VERSION "created by canmatrix"

NS_ :

BS_:

BU_: CabHeater_44 EAC_94 DCDC_1A HVJB_1E PPC_HV_5B PPC_00 PPC_EngineBrake_29 VECU_27 SAC_30 DTCO_EE eDS_5A EBS3_0B AEBS_A0 BMS_F4 Gearbox_03 DD_17 SERVICE_TOOL_F9 DANA_5F
VAL_TABLE_ ChargingSessionState 4 "ChargeSessionOngoing" 3 "Shutdown_CCU" 2 "Shutdown_EVSE" 1 "Shutdown_EV" 0 "No plug inserted" ;
VAL_TABLE_ ActiveDischarge 3 "NotAvailable" 2 "Error" 1 "Active" 0 "Not Active" ;
VAL_TABLE_ StopChargingSwitchIndication 3 "Not Available" 2 "Error" 1 "On" 0 "Off" ;

BO_ 3221225472 VECTOR__INDEPENDENT_SIG_MSG: 0 Vector__XXX
 SG_ HVESChargeConsent : 0|2@1+ (1,0) [0|3] "" Vector__XXX
 SG_ PropulsionModeReqDist : 0|16@1+ (0.03125,0) [0|2007.96875] "km" Vector__XXX
 SG_ PropulsionModeReqMaxSpd : 0|8@1+ (1,0) [0|250] "km/h" Vector__XXX
 SG_ StoredESSetPointReq : 0|8@1+ (0.4,0) [0|100] "%" Vector__XXX
 SG_ StoredESCharge_DischargeRateReq : 0|8@1+ (0.4,0) [0|100] "%" Vector__XXX
 SG_ ExtlESConnectionDemand : 0|4@1+ (1,0) [0|15] "" Vector__XXX
 SG_ PropulsionModeReq : 0|4@1+ (1,0) [0|15] "" Vector__XXX
 SG_ OpVehModeReq : 0|4@1+ (1,0) [0|15] "" Vector__XXX
 SG_ ShutdownCmd : 0|2@1+ (1,0) [0|3] "" Vector__XXX
 SG_ PropulsionDisableReq : 0|2@1+ (1,0) [0|3] "" Vector__XXX
 SG_ HybrdSystmRgnrtvBrakingDisableRq : 0|2@1+ (1,0) [0|3] "" Vector__XXX
 SG_ HybridSystemProtectionOverrideRq : 0|2@1+ (1,0) [0|3] "" Vector__XXX
 SG_ HVESSThermalMnmgtMaintenanceSw : 0|2@1+ (1,0) [0|3] "" Vector__XXX
 SG_ PropulsionMotorCoolantFillSw : 0|2@1+ (1,0) [0|3] "" Vector__XXX
 SG_ PwrECoolantFillSw : 0|2@1+ (1,0) [0|3] "" Vector__XXX
 SG_ ShutdownSw : 0|2@1+ (1,0) [0|3] "" Vector__XXX
 SG_ PropulsionDisableSw : 0|2@1+ (1,0) [0|3] "" Vector__XXX
 SG_ HybrdSystmCstngRgnrtvBrkngLvlSlc : 0|8@1+ (0.4,0) [0|100] "%" Vector__XXX
 SG_ HybrdSystmBrkPdlRgnrtvBrkngDsblS : 0|2@1+ (1,0) [0|3] "" Vector__XXX
 SG_ HybrdSystmRgnrtvBrkngDsbleSwitch : 0|2@1+ (1,0) [0|3] "" Vector__XXX
 SG_ HybrdSystmPwrElctrncsClntLvlSwtc : 0|2@1+ (1,0) [0|3] "" Vector__XXX
 SG_ HybrdSystmPrplsnClantLevelSwitch : 0|2@1+ (1,0) [0|3] "" Vector__XXX
 SG_ HybrdSystmPrtctionOverrideSwitch : 0|2@1+ (1,0) [0|3] "" Vector__XXX

BO_ 2566901851 UABX_Control: 8 PPC_HV_5B
 SG_ PLCHR_setTimeout : 0|16@1+ (1,0) [0|0] "s" Vector__XXX

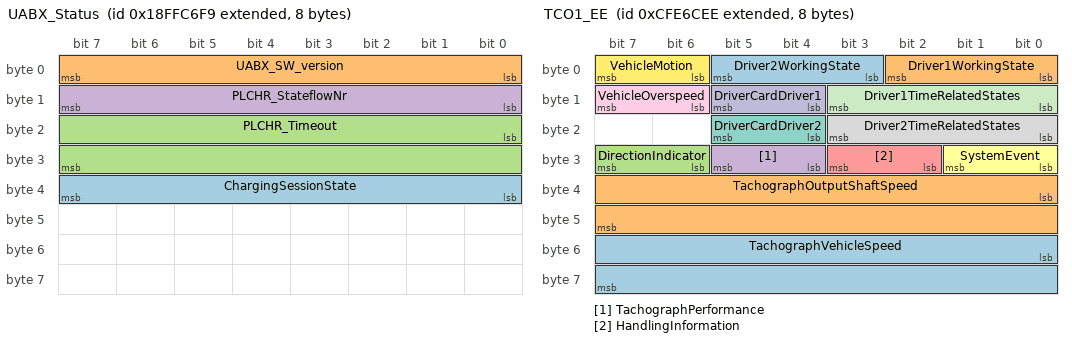
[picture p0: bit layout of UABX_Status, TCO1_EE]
BO_ 2566899449 UABX_Status: 8 SERVICE_TOOL_F9
 SG_ ChargingSessionState : 32|8@1+ (1,0) [0|0] "" Vector__XXX
 SG_ UABX_SW_version : 0|8@1+ (1,0) [0|0] "" Vector__XXX
 SG_ PLCHR_Timeout : 16|16@1+ (1,0) [0|0] "" Vector__XXX
 SG_ PLCHR_StateflowNr : 8|8@1+ (1,0) [0|0] "" Vector__XXX

BO_ 2633727071 WAKE_CCU_5F: 8 DANA_5F
 SG_ ControlBitVector : 0|8@1+ (1,0) [0|255] "state" Vector__XXX

BO_ 2565534720 RQST_HVESSCFG: 3 PPC_00

BO_ 2566866580 EAC_03_94: 8 EAC_94
 SG_ comp_overload : 34|1@1- (1,0) [0|1] "" Vector__XXX
 SG_ comp_temp_sens_shorted : 33|1@1- (1,0) [0|1] "" Vector__XXX
 SG_ comp_temp_sens_open : 32|1@1- (1,0) [0|1] "" Vector__XXX
 SG_ Oil_lev_switch_shorted_gnd : 31|1@1- (1,0) [0|1] "" Vector__XXX
 SG_ Oil_lev_switch_shorted_power : 30|1@1- (1,0) [0|1] "" Vector__XXX
 SG_ HVIL_Out_Open_Circuit_Fault : 29|1@1- (1,0) [0|1] "" Vector__XXX
 SG_ HVIL_In_Open_Circuit_Fault : 28|1@1- (1,0) [0|1] "" Vector__XXX
 SG_ HVIL_Open_Circuit_Fault : 27|1@1- (1,0) [0|1] "" Vector__XXX
 SG_ HVIL_Over_Current_Fault : 26|1@1- (1,0) [0|1] "" Vector__XXX
 SG_ Mult_Int_Temp_Sensor_Fault : 25|1@1- (1,0) [0|1] "" Vector__XXX
 SG_ Torque_High_Reduced_Speed : 24|1@1- (1,0) [0|1] "" Vector__XXX
 SG_ Reserved5 : 23|1@1- (1,0) [0|1] "" Vector__XXX
 SG_ Reserved4 : 22|1@1- (1,0) [0|1] "" Vector__XXX
 SG_ Internal_Temp_Sensor_Fault : 21|1@1- (1,0) [0|1] "" Vector__XXX
 SG_ Oil_Level_Switch_Circuit_Short : 20|1@1- (1,0) [0|1] "" Vector__XXX
 SG_ Oil_Level_Switch_Circuit_Open : 19|1@1- (1,0) [0|1] "" Vector__XXX
 SG_ CAN_Bus_Fault : 18|1@1- (1,0) [0|1] "" Vector__XXX
 SG_ EEPROM_Checksum_Fault : 17|1@1- (1,0) [0|1] "" Vector__XXX
 SG_ ESCM_Enable_Component_SPN_Error : 16|1@1- (1,0) [0|1] "" Vector__XXX
 SG_ ESCM_Max_Current_SPN_Error : 15|1@1- (1,0) [0|1] "" Vector__XXX
 SG_ ESCM_Speed_Request_SPN_Error : 14|1@1- (1,0) [0|1] "" Vector__XXX
 SG_ Power_Control_PGN_Fault : 13|1@1- (1,0) [0|1] "" Vector__XXX
 SG_ Speed_Req_PGN_Fault : 12|1@1- (1,0) [0|1] "" Vector__XXX
 SG_ Oil_Level_Low : 11|1@1- (1,0) [0|1] "" Vector__XXX
 SG_ Reserved2 : 10|1@1- (1,0) [0|1] "" Vector__XXX
 SG_ Reserved1 : 9|1@1- (1,0) [0|1] "" Vector__XXX
 SG_ Emotor_Over_Temperature : 8|1@1- (1,0) [0|1] "" Vector__XXX
 SG_ Compressor_Over_Temperature : 7|1@1- (1,0) [0|1] "" Vector__XXX
 SG_ No_Connection_With_PU : 6|1@1- (1,0) [0|1] "" Vector__XXX
 SG_ Power_Stage_Error : 5|1@1- (1,0) [0|1] "" Vector__XXX
 SG_ Overload : 4|1@1- (1,0) [0|1] "" Vector__XXX
 SG_ Traction_Volt_High : 3|1@1- (1,0) [0|1] "" Vector__XXX
 SG_ Traction_Supply_Current_Low : 2|1@1- (1,0) [0|1] "" Vector__XXX
 SG_ Traction_Volt_Low : 1|1@1- (1,0) [0|1] "" Vector__XXX
 SG_ Traction_Volt_Critical_Low : 0|1@1- (1,0) [0|1] "" Vector__XXX

BO_ 2633785076 HVESSHIST_F4: 19 BMS_F4
 SG_ HVESSTotalEnergyOut : 120|32@1+ (1,0) [0|4211081215] "kWh" Vector__XXX
 SG_ HVESSTotalEnergyInput : 88|32@1+ (1,0) [0|4211081215] "kWh" Vector__XXX
 SG_ HVESSTotalAccumulatedCharge : 56|32@1+ (100,0) [0|421108121500] "Ah" Vector__XXX
 SG_ HVESSTotalEnergyThroughput : 24|32@1+ (100,0) [0|421108121500] "Wh" Vector__XXX
 SG_ HVESSContactorOpenUnderLoadCount : 8|16@1+ (1,0) [0|64255] "" Vector__XXX
 SG_ HVESSStateOfHealth : 0|8@1+ (0.4,0) [0|100] "%" Vector__XXX

BO_ 2365484270 TCO1_EE: 8 DTCO_EE
 SG_ TachographVehicleSpeed : 48|16@1+ (0.00390625,0) [0|250.99609375] "km/h" Vector__XXX
 SG_ TachographOutputShaftSpeed : 32|16@1+ (0.125,0) [0|8031.875] "rpm" Vector__XXX
 SG_ DirectionIndicator : 30|2@1+ (1,0) [0|3] "" Vector__XXX
 SG_ TachographPerformance : 28|2@1+ (1,0) [0|3] "" Vector__XXX
 SG_ HandlingInformation : 26|2@1+ (1,0) [0|3] "" Vector__XXX
 SG_ SystemEvent : 24|2@1+ (1,0) [0|3] "" Vector__XXX
 SG_ DriverCardDriver2 : 20|2@1+ (1,0) [0|3] "" Vector__XXX
 SG_ Driver2TimeRelatedStates : 16|4@1+ (1,0) [0|15] "" Vector__XXX
 SG_ VehicleOverspeed : 14|2@1+ (1,0) [0|3] "" Vector__XXX
 SG_ DriverCardDriver1 : 12|2@1+ (1,0) [0|3] "" Vector__XXX
 SG_ Driver1TimeRelatedStates : 8|4@1+ (1,0) [0|15] "" Vector__XXX
 SG_ VehicleMotion : 6|2@1+ (1,0) [0|3] "" Vector__XXX
 SG_ Driver2WorkingState : 3|3@1+ (1,0) [0|7] "" Vector__XXX
 SG_ Driver1WorkingState : 0|3@1+ (1,0) [0|7] "" Vector__XXX

BO_ 2565537626 RQST_TCFG_5A: 3 eDS_5A
 SG_ ParameterGroupNumberRQST : 0|24@1+ (1,0) [0|16777215] "PGN" Vector__XXX

BO_ 2566846554 TRF1_5A: 8 eDS_5A
 SG_ TransmissionOilTemperature1 : 32|16@1+ (0.03125,-273) [-273|1774.96875] "degC" Vector__XXX

BO_ 2566615642 MG1IT_5A: 8 eDS_5A
 SG_ MotorGenerator1InverterTemp1 : 0|8@1+ (1,-40) [-40|215] "degC" Vector__XXX
 SG_ MotorGenerator1InverterTemp2 : 8|8@1+ (1,-40) [-40|215] "degC" Vector__XXX

BO_ 2566615386 MG1IMT_5A: 8 eDS_5A
 SG_ MotorGenerator1Temperature1 : 0|8@1+ (1,-40) [-40|215] "degC" Vector__XXX
 SG_ MotorGenerator1Temperature2 : 8|8@1+ (1,-40) [-40|215] "degC" Vector__XXX

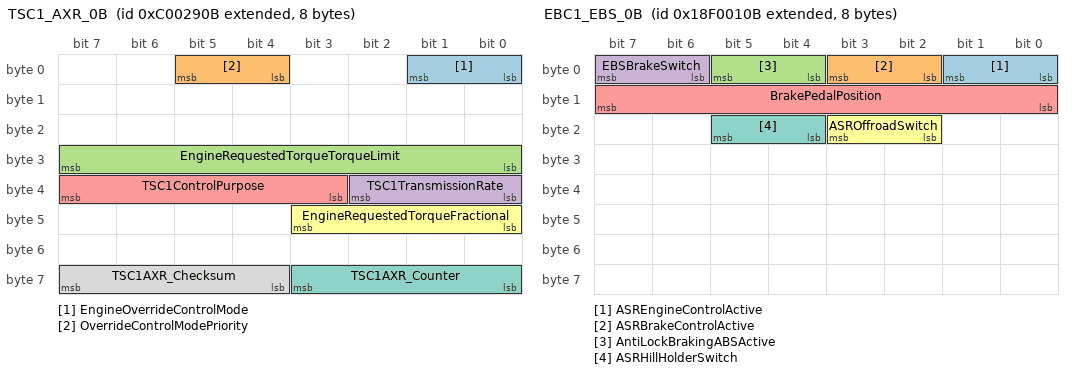
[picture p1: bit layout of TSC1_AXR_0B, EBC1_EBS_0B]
BO_ 2348820747 TSC1_AXR_0B: 8 EBS3_0B
 SG_ EngineOverrideControlMode : 0|2@1+ (1,0) [0|3] "state" Vector__XXX
 SG_ OverrideControlModePriority : 4|2@1+ (1,0) [0|3] "state" Vector__XXX
 SG_ EngineRequestedTorqueTorqueLimit : 24|8@1+ (1,-125) [-125|130] "%" Vector__XXX
 SG_ TSC1TransmissionRate : 32|3@1+ (1,0) [0|7] "state" Vector__XXX
 SG_ TSC1ControlPurpose : 35|5@1+ (1,0) [0|31] "state" Vector__XXX
 SG_ EngineRequestedTorqueFractional : 40|4@1+ (0.125,0) [0|1.875] "%" Vector__XXX
 SG_ TSC1AXR_Counter : 56|4@1+ (1,0) [0|15] "count" Vector__XXX
 SG_ TSC1AXR_Checksum : 60|4@1+ (1,0) [0|15] "count" Vector__XXX

BO_ 2565865739 EBC1_EBS_0B: 8 EBS3_0B
 SG_ ASREngineControlActive : 0|2@1+ (1,0) [0|3] "state" Vector__XXX
 SG_ ASRBrakeControlActive : 2|2@1+ (1,0) [0|3] "state" Vector__XXX
 SG_ AntiLockBrakingABSActive : 4|2@1+ (1,0) [0|3] "state" Vector__XXX
 SG_ EBSBrakeSwitch : 6|2@1+ (1,0) [0|3] "state" Vector__XXX
 SG_ BrakePedalPosition : 8|8@1+ (0.4,0) [0|102] "%" Vector__XXX
 SG_ ASROffroadSwitch : 18|2@1+ (1,0) [0|3] "state" Vector__XXX
 SG_ ASRHillHolderSwitch : 20|2@1+ (1,0) [0|3] "state" Vector__XXX

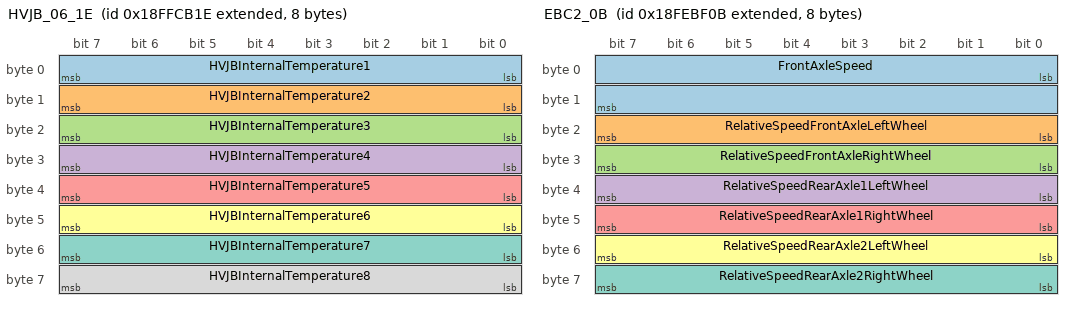
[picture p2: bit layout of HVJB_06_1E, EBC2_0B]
BO_ 2566900510 HVJB_06_1E: 8 HVJB_1E
 SG_ HVJBInternalTemperature1 : 0|8@1+ (1,-40) [-40|215] "degC" Vector__XXX
 SG_ HVJBInternalTemperature2 : 8|8@1+ (1,-40) [-40|215] "degC" Vector__XXX
 SG_ HVJBInternalTemperature3 : 16|8@1+ (1,-40) [-40|215] "degC" Vector__XXX
 SG_ HVJBInternalTemperature4 : 24|8@1+ (1,-40) [-40|215] "degC" Vector__XXX
 SG_ HVJBInternalTemperature5 : 32|8@1+ (1,-40) [-40|215] "degC" Vector__XXX
 SG_ HVJBInternalTemperature6 : 40|8@1+ (1,-40) [-40|215] "degC" Vector__XXX
 SG_ HVJBInternalTemperature7 : 48|8@1+ (1,-40) [-40|215] "degC" Vector__XXX
 SG_ HVJBInternalTemperature8 : 56|8@1+ (1,-40) [-40|215] "degC" Vector__XXX

BO_ 2566831883 EBC2_0B: 8 EBS3_0B
 SG_ FrontAxleSpeed : 0|16@1+ (0.00390625,0) [0|255.99609375] "km/h" Vector__XXX
 SG_ RelativeSpeedFrontAxleLeftWheel : 16|8@1+ (0.0625,-7.8125) [-7.8125|8.125] "km/h" Vector__XXX
 SG_ RelativeSpeedFrontAxleRightWheel : 24|8@1+ (0.0625,-7.8125) [-7.8125|8.125] "km/h" Vector__XXX
 SG_ RelativeSpeedRearAxle1LeftWheel : 32|8@1+ (0.0625,-7.8125) [-7.8125|8.125] "km/h" Vector__XXX
 SG_ RelativeSpeedRearAxle1RightWheel : 40|8@1+ (0.0625,-7.8125) [-7.8125|8.125] "km/h" Vector__XXX
 SG_ RelativeSpeedRearAxle2LeftWheel : 48|8@1+ (0.0625,-7.8125) [-7.8125|8.125] "km/h" Vector__XXX
 SG_ RelativeSpeedRearAxle2RightWheel : 56|8@1+ (0.0625,-7.8125) [-7.8125|8.125] "km/h" Vector__XXX

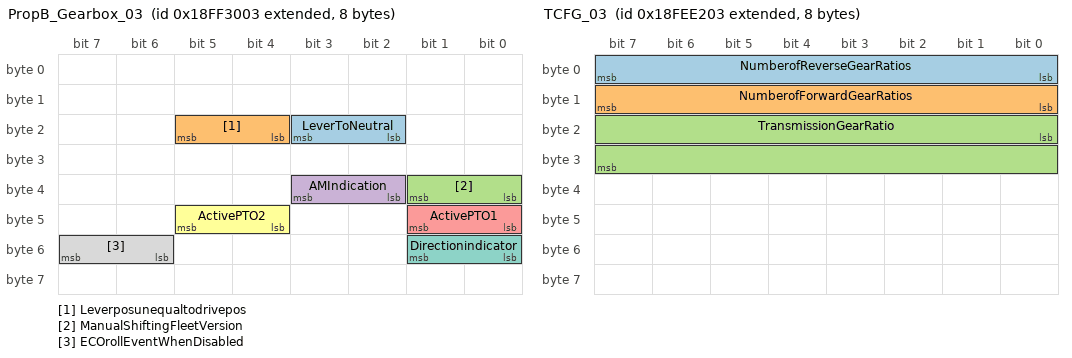
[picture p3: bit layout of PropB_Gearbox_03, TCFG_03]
BO_ 2566860803 PropB_Gearbox_03: 8 Gearbox_03
 SG_ LeverToNeutral : 18|2@1+ (1,0) [0|3] "state" Vector__XXX
 SG_ Leverposunequaltodrivepos : 20|2@1+ (1,0) [0|3] "state" Vector__XXX
 SG_ ManualShiftingFleetVersion : 32|2@1+ (1,0) [0|3] "state" Vector__XXX
 SG_ AMIndication : 34|2@1+ (1,0) [0|3] "state" Vector__XXX
 SG_ ActivePTO1 : 40|2@1+ (1,0) [0|3] "state" Vector__XXX
 SG_ ActivePTO2 : 44|2@1+ (1,0) [0|3] "state" Vector__XXX
 SG_ Directionindicator : 48|2@1+ (1,0) [0|3] "state" Vector__XXX
 SG_ ECOrollEventWhenDisabled : 54|2@1+ (1,0) [0|3] "state" Vector__XXX

BO_ 2566840835 TCFG_03: 8 Gearbox_03
 SG_ NumberofReverseGearRatios : 0|8@1+ (1,0) [0|255] "state" Vector__XXX
 SG_ NumberofForwardGearRatios : 8|8@1+ (1,0) [0|255] "state" Vector__XXX
 SG_ TransmissionGearRatio : 16|16@1+ (0.001,0) [0|65.535] "ratio" Vector__XXX

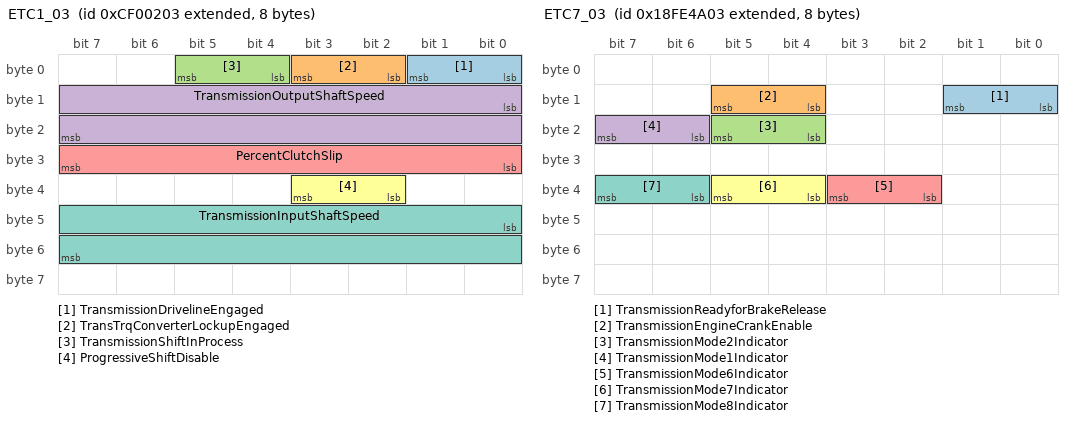
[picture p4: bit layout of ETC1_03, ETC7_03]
BO_ 2364539395 ETC1_03: 8 Gearbox_03
 SG_ TransmissionDrivelineEngaged : 0|2@1+ (1,0) [0|3] "state" Vector__XXX
 SG_ TransTrqConverterLockupEngaged : 2|2@1+ (1,0) [0|3] "state" Vector__XXX
 SG_ TransmissionShiftInProcess : 4|2@1+ (1,0) [0|3] "state" Vector__XXX
 SG_ TransmissionOutputShaftSpeed : 8|16@1+ (0.125,0) [0|8191.875] "rpm" Vector__XXX
 SG_ PercentClutchSlip : 24|8@1+ (0.4,0) [0|102] "%" Vector__XXX
 SG_ ProgressiveShiftDisable : 34|2@1+ (1,0) [0|3] "state" Vector__XXX
 SG_ TransmissionInputShaftSpeed : 40|16@1+ (0.125,0) [0|8191.875] "rpm" Vector__XXX

BO_ 2566801923 ETC7_03: 8 Gearbox_03
 SG_ TransmissionReadyforBrakeRelease : 8|2@1+ (1,0) [0|3] "state" Vector__XXX
 SG_ TransmissionEngineCrankEnable : 12|2@1+ (1,0) [0|3] "state" Vector__XXX
 SG_ TransmissionMode2Indicator : 20|2@1+ (1,0) [0|3] "state" Vector__XXX
 SG_ TransmissionMode1Indicator : 22|2@1+ (1,0) [0|3] "state" Vector__XXX
 SG_ TransmissionMode6Indicator : 34|2@1+ (1,0) [0|3] "state" Vector__XXX
 SG_ TransmissionMode7Indicator : 36|2@1+ (1,0) [0|3] "state" Vector__XXX
 SG_ TransmissionMode8Indicator : 38|2@1+ (1,0) [0|3] "state" Vector__XXX

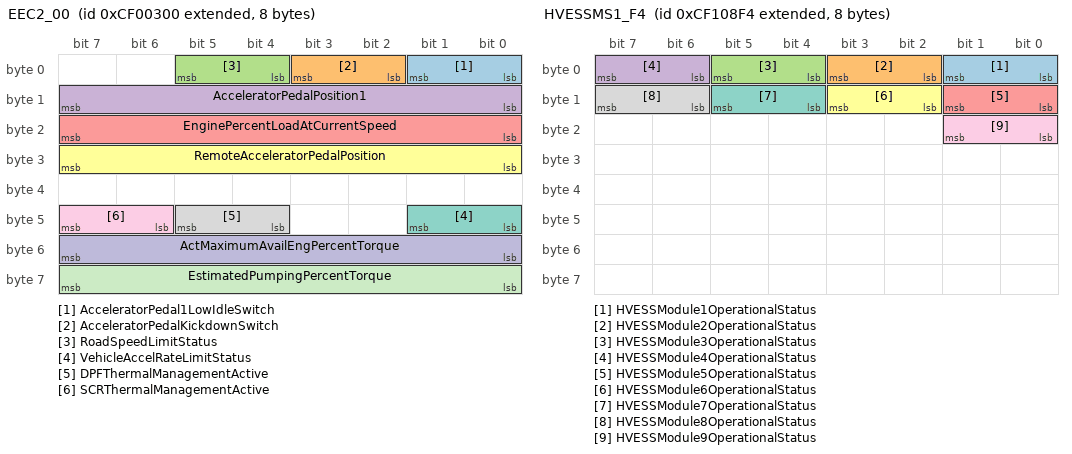
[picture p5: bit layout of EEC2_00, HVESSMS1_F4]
BO_ 2364539648 EEC2_00: 8 PPC_00
 SG_ AcceleratorPedal1LowIdleSwitch : 0|2@1+ (1,0) [0|3] "state" Vector__XXX
 SG_ AcceleratorPedalKickdownSwitch : 2|2@1+ (1,0) [0|3] "state" Vector__XXX
 SG_ RoadSpeedLimitStatus : 4|2@1+ (1,0) [0|3] "state" Vector__XXX
 SG_ AcceleratorPedalPosition1 : 8|8@1+ (0.4,0) [0|102] "%" Vector__XXX
 SG_ EnginePercentLoadAtCurrentSpeed : 16|8@1+ (1,0) [0|255] "%" Vector__XXX
 SG_ RemoteAcceleratorPedalPosition : 24|8@1+ (0.4,0) [0|102] "%" Vector__XXX
 SG_ VehicleAccelRateLimitStatus : 40|2@1+ (1,0) [0|3] "state" Vector__XXX
 SG_ DPFThermalManagementActive : 44|2@1+ (1,0) [0|3] "state" Vector__XXX
 SG_ SCRThermalManagementActive : 46|2@1+ (1,0) [0|3] "state" Vector__XXX
 SG_ ActMaximumAvailEngPercentTorque : 48|8@1+ (0.4,0) [0|102] "%" Vector__XXX
 SG_ EstimatedPumpingPercentTorque : 56|8@1+ (1,-125) [-125|130] "%" Vector__XXX

BO_ 2364606708 HVESSMS1_F4: 8 BMS_F4
 SG_ HVESSModule1OperationalStatus : 0|2@1+ (1,0) [0|3] "bit-mapped" Vector__XXX
 SG_ HVESSModule2OperationalStatus : 2|2@1+ (1,0) [0|3] "bit-mapped" Vector__XXX
 SG_ HVESSModule3OperationalStatus : 4|2@1+ (1,0) [0|3] "bit-mapped" Vector__XXX
 SG_ HVESSModule4OperationalStatus : 6|2@1+ (1,0) [0|3] "bit-mapped" Vector__XXX
 SG_ HVESSModule5OperationalStatus : 8|2@1+ (1,0) [0|3] "bit-mapped" Vector__XXX
 SG_ HVESSModule6OperationalStatus : 10|2@1+ (1,0) [0|3] "bit-mapped" Vector__XXX
 SG_ HVESSModule7OperationalStatus : 12|2@1+ (1,0) [0|3] "bit-mapped" Vector__XXX
 SG_ HVESSModule8OperationalStatus : 14|2@1+ (1,0) [0|3] "bit-mapped" Vector__XXX
 SG_ HVESSModule9OperationalStatus : 16|2@1+ (1,0) [0|3] "bit-mapped" Vector__XXX

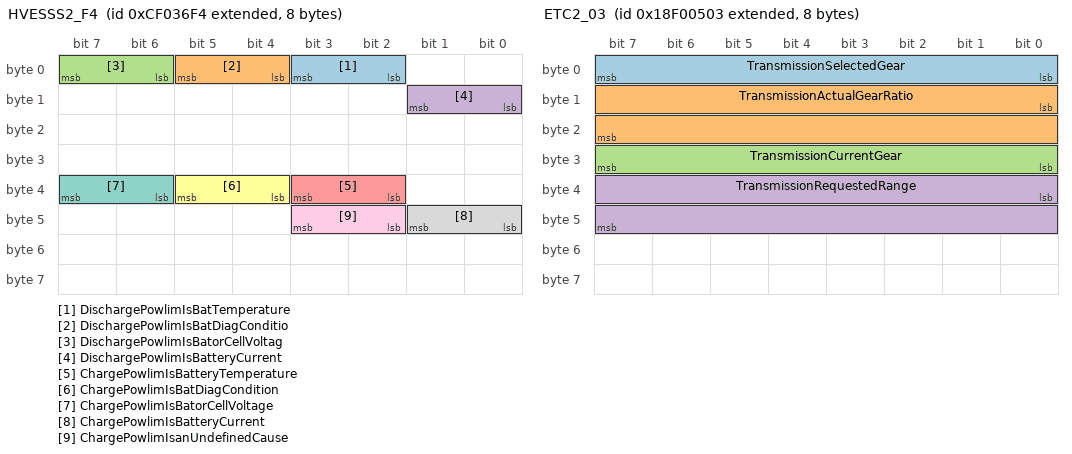
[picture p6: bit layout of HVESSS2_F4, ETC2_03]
BO_ 2364552948 HVESSS2_F4: 8 BMS_F4
 SG_ DischargePowlimIsBatTemperature : 2|2@1+ (1,0) [0|3] "bit-mapped" Vector__XXX
 SG_ DischargePowlimIsBatDiagConditio : 4|2@1+ (1,0) [0|3] "bit-mapped" Vector__XXX
 SG_ DischargePowlimIsBatorCellVoltag : 6|2@1+ (1,0) [0|3] "bit-mapped" Vector__XXX
 SG_ DischargePowlimIsBatteryCurrent : 8|2@1+ (1,0) [0|3] "bit-mapped" Vector__XXX
 SG_ ChargePowlimIsBatteryTemperature : 34|2@1+ (1,0) [0|3] "bit-mapped" Vector__XXX
 SG_ ChargePowlimIsBatDiagCondition : 36|2@1+ (1,0) [0|3] "bit-mapped" Vector__XXX
 SG_ ChargePowlimIsBatorCellVoltage : 38|2@1+ (1,0) [0|3] "bit-mapped" Vector__XXX
 SG_ ChargePowlimIsBatteryCurrent : 40|2@1+ (1,0) [0|3] "bit-mapped" Vector__XXX
 SG_ ChargePowlimIsanUndefinedCause : 42|2@1+ (1,0) [0|3] "bit-mapped" Vector__XXX

BO_ 2565866755 ETC2_03: 8 Gearbox_03
 SG_ TransmissionSelectedGear : 0|8@1+ (1,-125) [-125|130] "state" Vector__XXX
 SG_ TransmissionActualGearRatio : 8|16@1+ (0.001,0) [0|65.535] "ratio" Vector__XXX
 SG_ TransmissionCurrentGear : 24|8@1+ (1,-125) [-125|130] "state" Vector__XXX
 SG_ TransmissionRequestedRange : 32|16@1+ (1,0) [0|65535] "ASCII" Vector__XXX

BO_ 2583630324 HVESS_01_F4: 8 BMS_F4
 SG_ ChargingTimeTillFullSOCEst : 0|16@1+ (1,0) [0|65535] "min" Vector__XXX
 SG_ ChargingTimeTillFullSOCRec : 16|16@1+ (1,0) [0|65535] "min" Vector__XXX

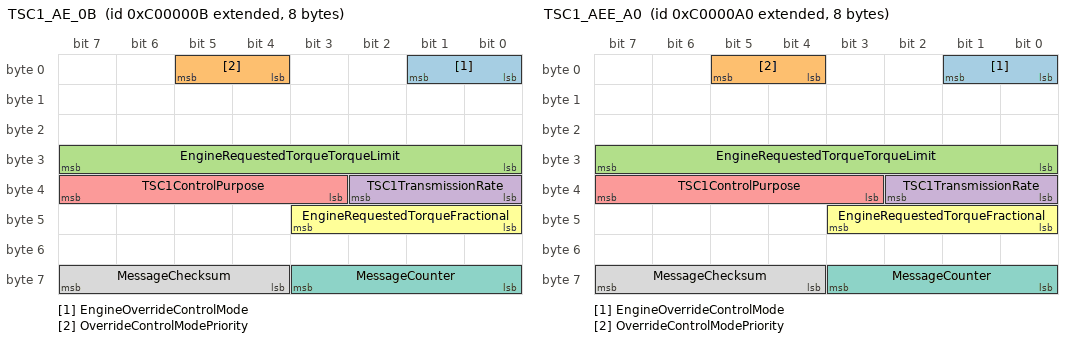
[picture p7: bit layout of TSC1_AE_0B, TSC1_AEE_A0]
BO_ 2348810251 TSC1_AE_0B: 8 EBS3_0B
 SG_ EngineOverrideControlMode : 0|2@1+ (1,0) [0|3] "state" Vector__XXX
 SG_ OverrideControlModePriority : 4|2@1+ (1,0) [0|3] "state" Vector__XXX
 SG_ EngineRequestedTorqueTorqueLimit : 24|8@1+ (1,-125) [-125|130] "%" Vector__XXX
 SG_ TSC1TransmissionRate : 32|3@1+ (1,0) [0|7] "state" Vector__XXX
 SG_ TSC1ControlPurpose : 35|5@1+ (1,0) [0|31] "state" Vector__XXX
 SG_ EngineRequestedTorqueFractional : 40|4@1+ (0.125,0) [0|1.875] "%" Vector__XXX
 SG_ MessageCounter : 56|4@1+ (1,0) [0|15] "count" Vector__XXX
 SG_ MessageChecksum : 60|4@1+ (1,0) [0|15] "count" Vector__XXX

BO_ 2348810400 TSC1_AEE_A0: 8 AEBS_A0
 SG_ EngineOverrideControlMode : 0|2@1+ (1,0) [0|3] "state" Vector__XXX
 SG_ OverrideControlModePriority : 4|2@1+ (1,0) [0|3] "state" Vector__XXX
 SG_ EngineRequestedTorqueTorqueLimit : 24|8@1+ (1,-125) [-125|130] "%" Vector__XXX
 SG_ TSC1TransmissionRate : 32|3@1+ (1,0) [0|7] "state" Vector__XXX
 SG_ TSC1ControlPurpose : 35|5@1+ (1,0) [0|31] "state" Vector__XXX
 SG_ EngineRequestedTorqueFractional : 40|4@1+ (0.125,0) [0|1.875] "%" Vector__XXX
 SG_ MessageCounter : 56|4@1+ (1,0) [0|15] "count" Vector__XXX
 SG_ MessageChecksum : 60|4@1+ (1,0) [0|15] "count" Vector__XXX

BO_ 2566698843 HSS2_5B: 8 PPC_HV_5B
 SG_ HybridPropulsionModeRemDist : 32|16@1+ (0.03125,0) [0|2007.96875] "km" Vector__XXX

BO_ 2566701659 HSS1_5B: 8 PPC_HV_5B
 SG_ StoredEnergySourceLevel : 32|8@1+ (0.4,0) [0|100] "%" Vector__XXX

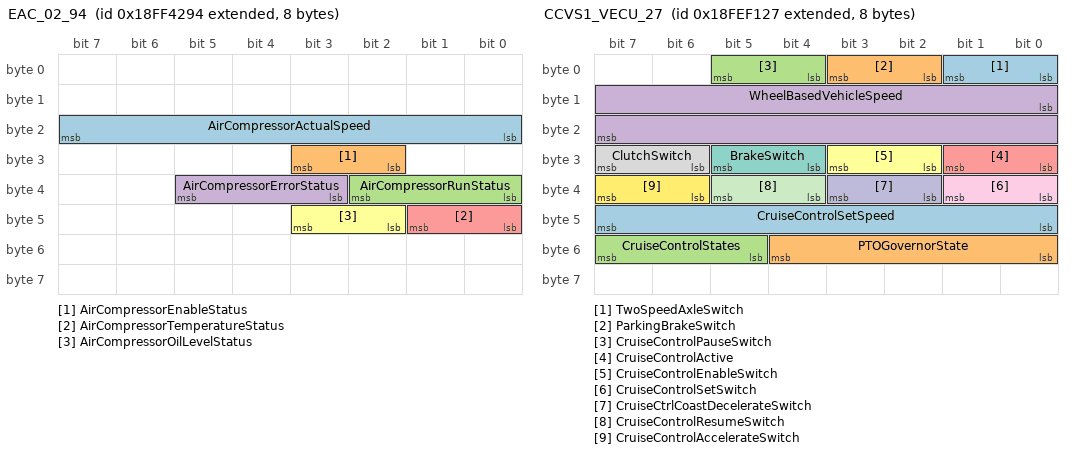
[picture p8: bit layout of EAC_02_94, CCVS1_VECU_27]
BO_ 2566865556 EAC_02_94: 8 EAC_94
 SG_ AirCompressorActualSpeed : 16|8@1+ (20,0) [0|5000] "rpm" Vector__XXX
 SG_ AirCompressorEnableStatus : 26|2@1+ (1,0) [0|3] "state" Vector__XXX
 SG_ AirCompressorRunStatus : 32|3@1+ (1,0) [0|7] "state" Vector__XXX
 SG_ AirCompressorErrorStatus : 35|3@1+ (1,0) [0|7] "state" Vector__XXX
 SG_ AirCompressorTemperatureStatus : 40|2@1+ (1,0) [0|3] "state" Vector__XXX
 SG_ AirCompressorOilLevelStatus : 42|2@1+ (1,0) [0|3] "state" Vector__XXX

BO_ 2566844711 CCVS1_VECU_27: 8 VECU_27
 SG_ TwoSpeedAxleSwitch : 0|2@1+ (1,0) [0|3] "state" Vector__XXX
 SG_ ParkingBrakeSwitch : 2|2@1+ (1,0) [0|3] "state" Vector__XXX
 SG_ CruiseControlPauseSwitch : 4|2@1+ (1,0) [0|3] "state" Vector__XXX
 SG_ WheelBasedVehicleSpeed : 8|16@1+ (0.00390625,0) [0|255.99609375] "km/h" Vector__XXX
 SG_ CruiseControlActive : 24|2@1+ (1,0) [0|3] "state" Vector__XXX
 SG_ CruiseControlEnableSwitch : 26|2@1+ (1,0) [0|3] "state" Vector__XXX
 SG_ BrakeSwitch : 28|2@1+ (1,0) [0|3] "state" Vector__XXX
 SG_ ClutchSwitch : 30|2@1+ (1,0) [0|3] "state" Vector__XXX
 SG_ CruiseControlSetSwitch : 32|2@1+ (1,0) [0|3] "state" Vector__XXX
 SG_ CruiseCtrlCoastDecelerateSwitch : 34|2@1+ (1,0) [0|3] "state" Vector__XXX
 SG_ CruiseControlResumeSwitch : 36|2@1+ (1,0) [0|3] "state" Vector__XXX
 SG_ CruiseControlAccelerateSwitch : 38|2@1+ (1,0) [0|3] "state" Vector__XXX
 SG_ CruiseControlSetSpeed : 40|8@1+ (1,0) [0|255] "km/h" Vector__XXX
 SG_ PTOGovernorState : 48|5@1+ (1,0) [0|31] "state" Vector__XXX
 SG_ CruiseControlStates : 53|3@1+ (1,0) [0|7] "state" Vector__XXX

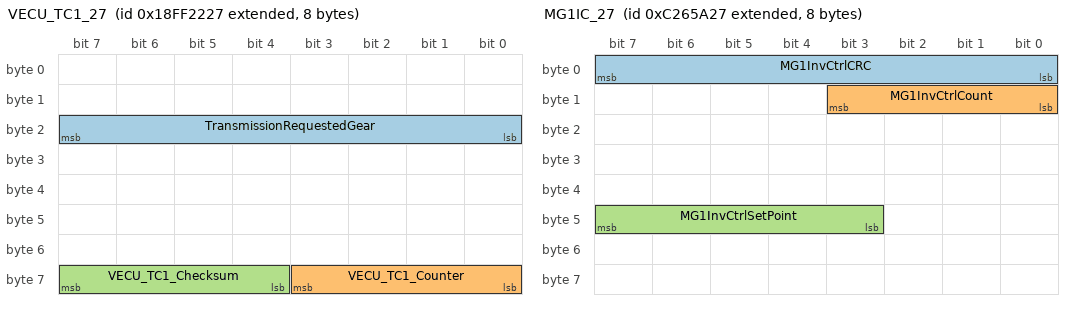
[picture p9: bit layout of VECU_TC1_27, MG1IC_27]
BO_ 2566857255 VECU_TC1_27: 8 VECU_27
 SG_ TransmissionRequestedGear : 16|8@1+ (1,-125) [-125|130] "gear value" Vector__XXX
 SG_ VECU_TC1_Counter : 56|4@1+ (1,0) [0|15] "count" Vector__XXX
 SG_ VECU_TC1_Checksum : 60|4@1+ (1,0) [0|15] "count" Vector__XXX

BO_ 2351323687 MG1IC_27: 8 VECU_27
 SG_ MG1InvCtrlCRC : 0|8@1+ (1,0) [0|255] "count" Vector__XXX
 SG_ MG1InvCtrlCount : 8|4@1+ (1,0) [0|15] "count" Vector__XXX
 SG_ MG1InvCtrlSetPoint : 43|5@1+ (1,0) [0|31] "state" Vector__XXX

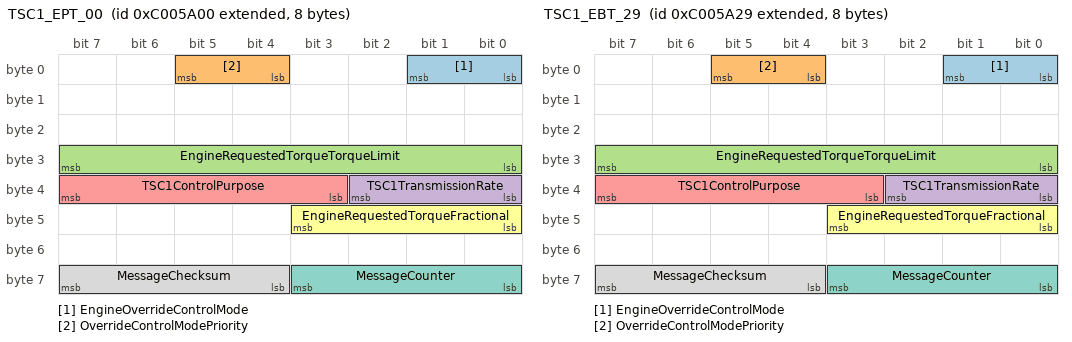
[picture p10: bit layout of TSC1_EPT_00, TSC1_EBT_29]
BO_ 2348833280 TSC1_EPT_00: 8 PPC_00
 SG_ EngineOverrideControlMode : 0|2@1+ (1,0) [0|3] "state" Vector__XXX
 SG_ OverrideControlModePriority : 4|2@1+ (1,0) [0|3] "state" Vector__XXX
 SG_ EngineRequestedTorqueTorqueLimit : 24|8@1+ (1,-125) [-125|130] "%" Vector__XXX
 SG_ TSC1TransmissionRate : 32|3@1+ (1,0) [0|7] "state" Vector__XXX
 SG_ TSC1ControlPurpose : 35|5@1+ (1,0) [0|31] "state" Vector__XXX
 SG_ EngineRequestedTorqueFractional : 40|4@1+ (0.125,0) [0|1.875] "%" Vector__XXX
 SG_ MessageCounter : 56|4@1+ (1,0) [0|15] "count" Vector__XXX
 SG_ MessageChecksum : 60|4@1+ (1,0) [0|15] "count" Vector__XXX

BO_ 2348833321 TSC1_EBT_29: 8 PPC_EngineBrake_29
 SG_ EngineOverrideControlMode : 0|2@1+ (1,0) [0|3] "state" Vector__XXX
 SG_ OverrideControlModePriority : 4|2@1+ (1,0) [0|3] "state" Vector__XXX
 SG_ EngineRequestedTorqueTorqueLimit : 24|8@1+ (1,-125) [-125|130] "%" Vector__XXX
 SG_ TSC1TransmissionRate : 32|3@1+ (1,0) [0|7] "state" Vector__XXX
 SG_ TSC1ControlPurpose : 35|5@1+ (1,0) [0|31] "state" Vector__XXX
 SG_ EngineRequestedTorqueFractional : 40|4@1+ (0.125,0) [0|1.875] "%" Vector__XXX
 SG_ MessageCounter : 56|4@1+ (1,0) [0|15] "count" Vector__XXX
 SG_ MessageChecksum : 60|4@1+ (1,0) [0|15] "count" Vector__XXX

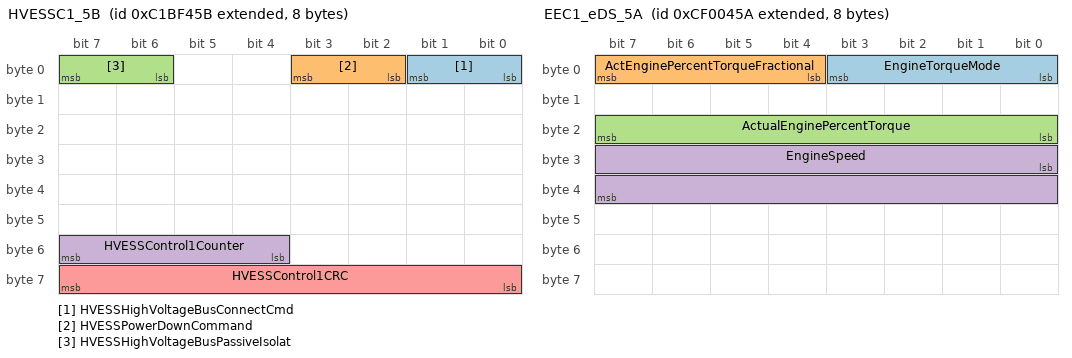
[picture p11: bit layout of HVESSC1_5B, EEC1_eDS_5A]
BO_ 2350642267 HVESSC1_5B: 8 PPC_HV_5B
 SG_ HVESSHighVoltageBusConnectCmd : 0|2@1+ (1,0) [0|3] "bit-mapped" Vector__XXX
 SG_ HVESSPowerDownCommand : 2|2@1+ (1,0) [0|3] "bit-mapped" Vector__XXX
 SG_ HVESSHighVoltageBusPassiveIsolat : 6|2@1+ (1,0) [0|3] "bit-mapped" Vector__XXX
 SG_ HVESSControl1Counter : 52|4@1+ (1,0) [0|15] "bit-mapped" Vector__XXX
 SG_ HVESSControl1CRC : 56|8@1+ (1,0) [0|255] "count" Vector__XXX

BO_ 2364539738 EEC2_eDS_5A: 8 eDS_5A
 SG_ ActMaximumAvailEngPercentTorque : 48|8@1+ (0.4,0) [0|102] "%" Vector__XXX

BO_ 2364539994 EEC1_eDS_5A: 8 eDS_5A
 SG_ EngineTorqueMode : 0|4@1+ (1,0) [0|15] "state" Vector__XXX
 SG_ ActEnginePercentTorqueFractional : 4|4@1+ (0.125,0) [0|1.875] "%" Vector__XXX
 SG_ ActualEnginePercentTorque : 16|8@1+ (1,-125) [-125|130] "%" Vector__XXX
 SG_ EngineSpeed : 24|16@1+ (0.125,0) [0|8191.875] "rpm" Vector__XXX

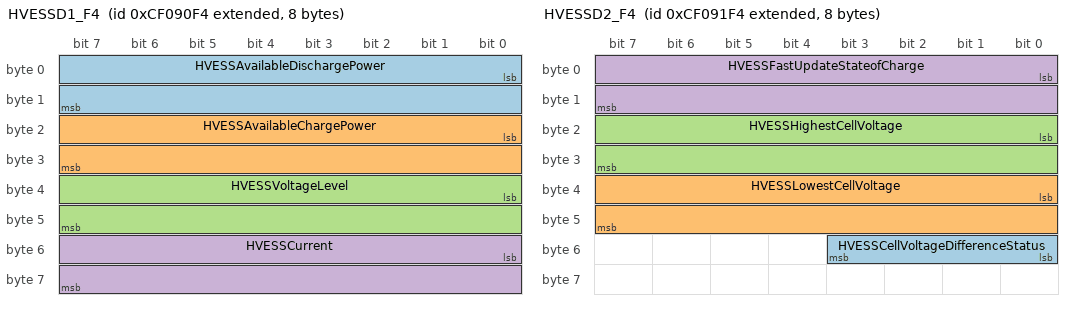
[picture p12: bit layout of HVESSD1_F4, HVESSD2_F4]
BO_ 2364575988 HVESSD1_F4: 8 BMS_F4
 SG_ HVESSAvailableDischargePower : 0|16@1+ (0.05,0) [0|3276.75] "kW" Vector__XXX
 SG_ HVESSAvailableChargePower : 16|16@1+ (0.05,0) [0|3276.75] "kW" Vector__XXX
 SG_ HVESSVoltageLevel : 32|16@1+ (0.05,0) [0|3276.75] "V" Vector__XXX
 SG_ HVESSCurrent : 48|16@1+ (0.05,-1600) [-1600|1676.75] "A" Vector__XXX

BO_ 2364576244 HVESSD2_F4: 8 BMS_F4
 SG_ HVESSCellVoltageDifferenceStatus : 48|4@1+ (1,0) [0|15] "" Vector__XXX
 SG_ HVESSLowestCellVoltage : 32|16@1+ (0.001,0) [0|64.255] "V" Vector__XXX
 SG_ HVESSHighestCellVoltage : 16|16@1+ (0.001,0) [0|64.255] "V" Vector__XXX
 SG_ HVESSFastUpdateStateofCharge : 0|16@1+ (0.0015625,0) [0|102.3984375] "%"  PPC_00

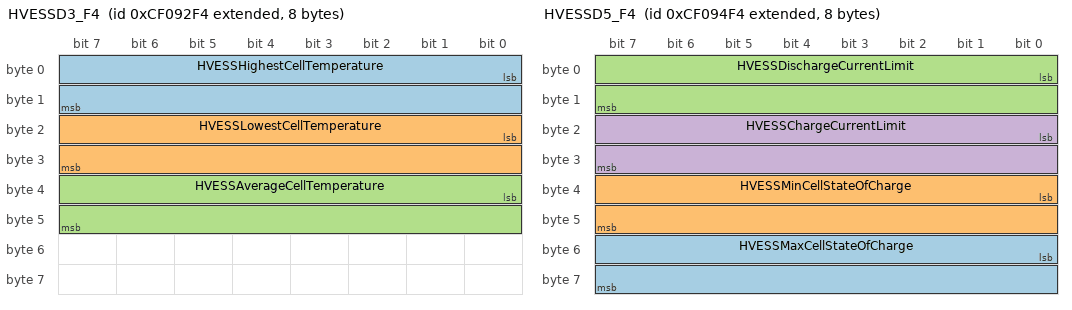
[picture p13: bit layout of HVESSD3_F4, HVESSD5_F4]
BO_ 2364576500 HVESSD3_F4: 8 BMS_F4
 SG_ HVESSHighestCellTemperature : 0|16@1+ (0.03125,-273) [-273|1774.96875] "degC" Vector__XXX
 SG_ HVESSLowestCellTemperature : 16|16@1+ (0.03125,-273) [-273|1774.96875] "degC" Vector__XXX
 SG_ HVESSAverageCellTemperature : 32|16@1+ (0.03125,-273) [-273|1774.96875] "degC"  PPC_00

BO_ 2364577012 HVESSD5_F4: 8 BMS_F4
 SG_ HVESSMaxCellStateOfCharge : 48|16@1+ (0.0015625,0) [0|100.3984375] "%" Vector__XXX
 SG_ HVESSMinCellStateOfCharge : 32|16@1+ (0.0015625,0) [0|100.3984375] "%" Vector__XXX
 SG_ HVESSDischargeCurrentLimit : 0|16@1+ (0.05,-1600) [-1600|1676.75] "A" Vector__XXX
 SG_ HVESSChargeCurrentLimit : 16|16@1+ (0.05,-1600) [-1600|1676.75] "A"  PPC_00

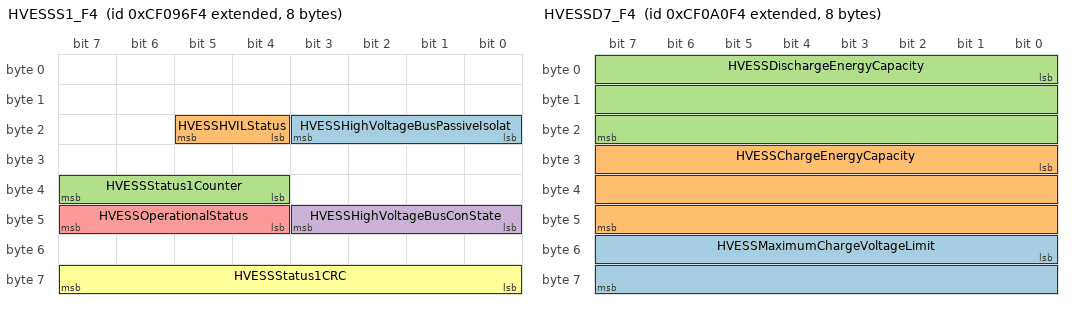
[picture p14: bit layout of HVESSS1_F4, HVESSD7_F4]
BO_ 2364577524 HVESSS1_F4: 8 BMS_F4
 SG_ HVESSHighVoltageBusPassiveIsolat : 16|4@1+ (1,0) [0|15] "state" Vector__XXX
 SG_ HVESSHVILStatus : 20|2@1+ (1,0) [0|3] "bit-mapped" Vector__XXX
 SG_ HVESSStatus1Counter : 36|4@1+ (1,0) [0|15] "bit-mapped" Vector__XXX
 SG_ HVESSHighVoltageBusConState : 40|4@1+ (1,0) [0|15] "state" Vector__XXX
 SG_ HVESSOperationalStatus : 44|4@1+ (1,0) [0|15] "state" Vector__XXX
 SG_ HVESSStatus1CRC : 56|8@1+ (1,0) [0|255] "count" Vector__XXX

BO_ 2364580084 HVESSD7_F4: 8 BMS_F4
 SG_ HVESSMaximumChargeVoltageLimit : 48|16@1+ (0.05,0) [0|3276.75] "V" Vector__XXX
 SG_ HVESSChargeEnergyCapacity : 24|24@1+ (0.001,0) [0|16449.535] "kWh" Vector__XXX
 SG_ HVESSDischargeEnergyCapacity : 0|24@1+ (0.001,0) [0|16449.535] "kWh" Vector__XXX

BO_ 2364606964 HVESSTS1_F4: 8 BMS_F4
 SG_ HVESSThermalManagementSystemHtrS : 48|2@1+ (1,0) [0|3] "bit-mapped" Vector__XXX

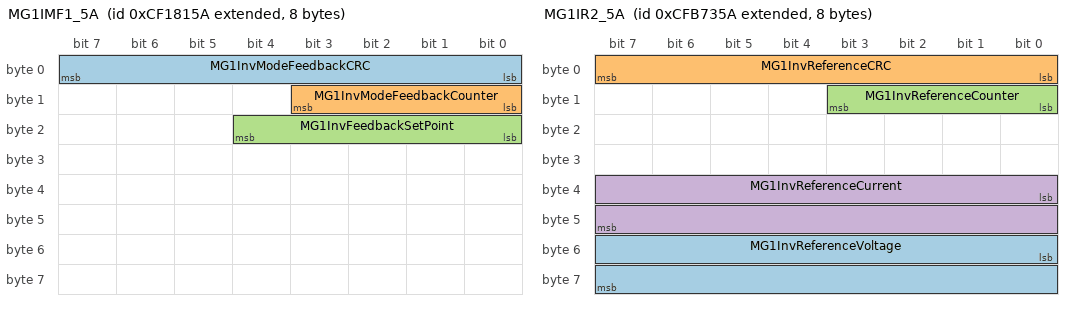
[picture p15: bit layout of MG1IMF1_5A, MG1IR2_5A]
BO_ 2364637530 MG1IMF1_5A: 8 eDS_5A
 SG_ MG1InvModeFeedbackCRC : 0|8@1+ (1,0) [0|255] "count" Vector__XXX
 SG_ MG1InvModeFeedbackCounter : 8|4@1+ (1,0) [0|15] "count" Vector__XXX
 SG_ MG1InvFeedbackSetPoint : 16|5@1+ (1,0) [0|31] "state" Vector__XXX

BO_ 2566841178 EC1_eDS_5A: 39 eDS_5A
 SG_ SupportTSC1CtrlPurposeGroup4 : 304|8@1+ (1,0) [0|255] "" Vector__XXX
 SG_ SupportTSC1CtrlPurposeGroup3 : 296|8@1+ (1,0) [0|255] "" Vector__XXX
 SG_ SupportTSC1CtrlPurposeGroup2 : 288|8@1+ (1,0) [0|255] "" Vector__XXX
 SG_ SupportTSC1CtrlPurposeGroup1 : 280|8@1+ (1,0) [0|255] "" Vector__XXX
 SG_ SupportVariableRateTSC1Message : 272|8@1+ (1,0) [0|255] "" Vector__XXX
 SG_ EngDefaultTorqueLimit : 256|16@1+ (1,0) [0|64255] "Nm" Vector__XXX
 SG_ EngMomentOfInertia : 240|16@1+ (0.004,0) [0|257.02] "kg-m¬≤" Vector__XXX
 SG_ EngExRngRqdSpdCtrlRngUpperLimit : 224|16@1+ (0.125,0) [0|8031.875] "rpm" Vector__XXX
 SG_ EngRqdTorqueCtrlRangeUpperLimit : 216|8@1+ (1,-125) [-125|125] "%" Vector__XXX
 SG_ EngRqdTorqueCtrlRangeLowerLimit : 208|8@1+ (1,-125) [-125|125] "%" Vector__XXX
 SG_ EngRqedSpeedCtrlRangeUpperLimit : 200|8@1+ (10,0) [0|2500] "rpm" Vector__XXX
 SG_ EngRqedSpeedCtrlRangeLowerLimit : 192|8@1+ (10,0) [0|2500] "rpm" Vector__XXX
 SG_ EngMxMomentaryOverrideTimeLimit : 184|8@1+ (0.1,0) [0|25] "s" Vector__XXX
 SG_ EngMxMmntaryOverrideSpeedPoint7 : 168|16@1+ (0.125,0) [0|8031.875] "rpm" Vector__XXX
 SG_ EngReferenceTorque : 152|16@1+ (1,0) [0|64255] "Nm" Vector__XXX
 SG_ EngSpeedAtHighIdlePoint6 : 120|16@1+ (0.125,0) [0|8031.875] "rpm" Vector__XXX
 SG_ EngGainOfEndspeedGovernor : 136|16@1+ (0.00078125,0) [0|50.2] "%/rpm" Vector__XXX
 SG_ EngPercentTorqueAtPoint5 : 112|8@1+ (1,-125) [-125|125] "%" Vector__XXX
 SG_ EngSpeedAtPoint5 : 96|16@1+ (0.125,0) [0|8031.875] "rpm" Vector__XXX
 SG_ EngPercentTorqueAtPoint4 : 88|8@1+ (1,-125) [-125|125] "%" Vector__XXX
 SG_ EngSpeedAtPoint4 : 72|16@1+ (0.125,0) [0|8031.875] "rpm" Vector__XXX
 SG_ EngPercentTorqueAtPoint3 : 64|8@1+ (1,-125) [-125|125] "%" Vector__XXX
 SG_ EngSpeedAtPoint3 : 48|16@1+ (0.125,0) [0|8031.875] "rpm" Vector__XXX
 SG_ EngPercentTorqueAtPoint2 : 40|8@1+ (1,-125) [-125|125] "%" Vector__XXX
 SG_ EngSpeedAtPoint2 : 24|16@1+ (0.125,0) [0|8031.875] "rpm" Vector__XXX
 SG_ EngPercentTorqueAtIdlePoint1 : 16|8@1+ (1,-125) [-125|125] "%" Vector__XXX
 SG_ EngSpeedAtIdlePoint1 : 0|16@1+ (0.125,0) [0|8031.875] "rpm" Vector__XXX

BO_ 2365289306 MG1IR2_5A: 8 eDS_5A
 SG_ MG1InvReferenceVoltage : 48|16@1+ (0.125,0) [0|8191.875] "V" Vector__XXX
 SG_ MG1InvReferenceCRC : 0|8@1+ (1,0) [0|255] "count" Vector__XXX
 SG_ MG1InvReferenceCounter : 8|4@1+ (1,0) [0|15] "count" Vector__XXX
 SG_ MG1InvReferenceCurrent : 32|16@1+ (0.125,0) [0|8191.875] "A" Vector__XXX

BO_ 2365289562 MG1IS1_5A: 8 eDS_5A
 SG_ MG1InvDCVoltageAbs m1 : 52|12@1+ (0.5,-1000) [-1000|1000] "V" Vector__XXX
 SG_ MG1InvDCCurrentAbs m1 : 40|12@1+ (0.65,-1300) [-1300|1300] "A" Vector__XXX
 SG_ dummyMuxSelector M : 12|1@1+ (1,0) [0|0] "" Vector__XXX
 SG_ MG1InvStatus1CRC : 0|8@1+ (1,0) [0|255] "count" Vector__XXX
 SG_ MG1InvStatus1Counter : 8|4@1+ (1,0) [0|15] "count" Vector__XXX
 SG_ MG1InvDCCurrent m0 : 40|12@1+ (0.0625,-125) [-125|125.9375] "%" Vector__XXX
 SG_ MG1InvDCVoltage m0 : 52|12@1+ (0.0625,-125) [-125|125.9375] "%" Vector__XXX

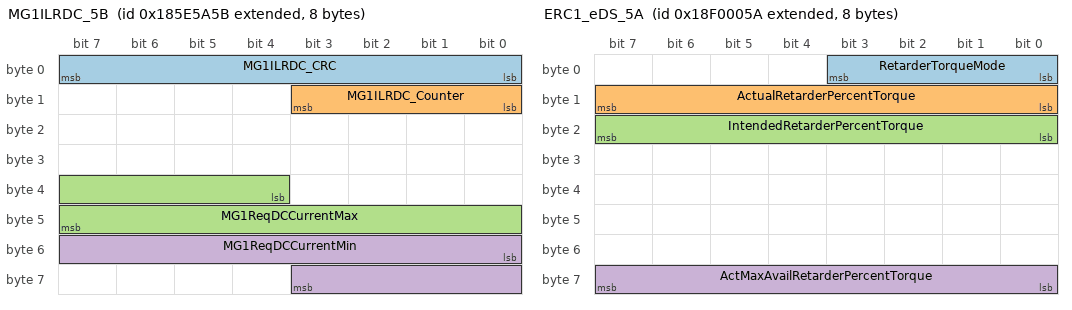
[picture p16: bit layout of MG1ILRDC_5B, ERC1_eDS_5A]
BO_ 2556320347 MG1ILRDC_5B: 8 PPC_HV_5B
 SG_ MG1ILRDC_CRC : 0|8@1+ (1,0) [0|255] "count" Vector__XXX
 SG_ MG1ILRDC_Counter : 8|4@1+ (1,0) [0|15] "count" Vector__XXX
 SG_ MG1ReqDCCurrentMax : 36|12@1+ (0.0625,-125) [-125|130.9375] "%" Vector__XXX
 SG_ MG1ReqDCCurrentMin : 48|12@1+ (0.0625,-125) [-125|130.9375] "%" Vector__XXX

BO_ 2564882267 CM1_HVS_5B: 8 PPC_HV_5B
 SG_ AuxiliaryHtrCoolantPumpRequest : 24|2@1+ (1,0) [0|3] "state" Vector__XXX

BO_ 2565537627 RQST_HVESS_5B: 3 PPC_HV_5B
 SG_ ParameterGroupNumberRQST : 0|24@1+ (1,0) [0|16777215] "PGN" Vector__XXX

BO_ 2565865562 ERC1_eDS_5A: 8 eDS_5A
 SG_ RetarderTorqueMode : 0|4@1+ (1,0) [0|15] "state" Vector__XXX
 SG_ ActualRetarderPercentTorque : 8|8@1+ (1,-125) [-125|130] "%" Vector__XXX
 SG_ IntendedRetarderPercentTorque : 16|8@1+ (1,-125) [-125|130] "%" Vector__XXX
 SG_ ActMaxAvailRetarderPercentTorque : 56|8@1+ (1,-125) [-125|130] "%" Vector__XXX

CM_ BO_ 3221225472 "This is a message for not used signals, created by Vector CANdb++ DBC OLE DB Provider.";
CM_ SG_ 3221225472 HVESChargeConsent "Indicates the sender's consent to charge the system's HVES (high-voltage energy storage) from EVSE (electric vehicle supply equipment), i.e. offboard vehicle charging station.
For example, a controller has certain application-specific conditions ...";
CM_ SG_ 3221225472 PropulsionModeReqDist "The requested distance to maintain a Hybrid Propulsion Mode (see SPN 7889) other than Mode 1 - Stored Energy Source Sustaining.
When the distance is met, or a protective mode is activated (e.g. HVES charge is depleted while in Mode 5 - Stored ...";
CM_ SG_ 3221225472 PropulsionModeReqMaxSpd "The requested maximum speed for the vehicle while in a Hybrid Propulsion Mode (see SPN 7889) other than Mode 1 - Stored Energy Source Sustaining.
This shall be the operating vehicle speed limit while in the range defined by Hybrid Propulsion Mode ...";
CM_ SG_ 3221225472 StoredESSetPointReq "Stored Energy Source Set Point Request is used to set the percentage that the Stored Energy Source should be managed to by the system.
A value of FBh indicates a request for the default set point. The percentage (0-100%) is the percentage of HVES ...";
CM_ SG_ 3221225472 StoredESCharge_DischargeRateReq "Stored Energy Source Charge/Discharge Rate Request is used to control the rate at which the stored energy is changed in Energy Increasing or Energy Depleting modes.
A value of FBh indicates a request for the default charge/discharge rate.  In a ...";
CM_ SG_ 3221225472 ExtlESConnectionDemand "This parameter allows for two external energy source connections.  Propulsion may or may not be allowed as defined by the Operator Vehicle Mode Request (SPN 7888).  The state of the engine (fuel cell etc.) is dictated by the Hybrid Propulsion Mode ...";
CM_ SG_ 3221225472 PropulsionModeReq "Hybrid Propulsion Mode Request is the operator intended propulsion mode.  This parameter can be from only one source on the vehicle.  Response to this request can be found in the Hybrid Propulsion Mode Status (SPN 7896) and Hybrid Propulsion Mode ...";
CM_ SG_ 3221225472 OpVehModeReq "Operator Vehicle Mode Request is the operator intended vehicle mode.  This parameter can be from only one source on the vehicle.  In the case of a Diesel-Electric Hybrid, the source of this parameter may be a vehicle controller that monitors the ...";
CM_ SG_ 3221225472 ShutdownCmd "Indicates the Hybrid System Shutdown Request state.  The signal gives network controllers the ability to disable all hybrid system functionality including propulsion, regenerative braking, and hybrid powered accessories.  For electric hybrids, the ...";
CM_ SG_ 3221225472 PropulsionDisableReq "Indicates the Hybrid System Disable Request state.  The signal gives network controllers the ability to disable the propulsion aspect of hybrid system operation when this request is on.  However, hybrid powered accessories may be on and the engine ...";
CM_ SG_ 3221225472 HybrdSystmRgnrtvBrakingDisableRq "Indicates the hybrid system regenerative braking disable request state.  This signal gives network controllers the ability to disable all regenerative braking.  This is not the operator controlled switch that performs regenerative braking disable ...";
CM_ SG_ 3221225472 HybridSystemProtectionOverrideRq "Indicates the hybrid system protection override request state.  This request allows overriding of hybrid system protection
features and failure modes allowing hybrid systems to continue to operate, if possible. This is not the physical switch that ...";
CM_ SG_ 3221225472 HVESSThermalMnmgtMaintenanceSw "Indicates the HVESS Thermal Management Maintenance Switch position. This switch is used to request the Hybrid or Electric Vehicle System Controller to maintain HVESS thermal management for maintenance purposes.
00b = Off
01b = On
10b = Error
11b ...";
CM_ SG_ 3221225472 PropulsionMotorCoolantFillSw "Indicates the coolant fill switch position for the propulsion motor cooling system.  This switch is used to enable the pump for filling the cooling system.  When the switch is in the On state, the pump is to be running.
00b = Off
01b = On
10b = ...";
CM_ SG_ 3221225472 PwrECoolantFillSw "Indicates the coolant fill switch position for the power electronics cooling system.  This switch is used to enable the pump for filling the cooling system.  When the switch is in the On state, the pump is to be running.
00b = Off
01b = On
10b = ...";
CM_ SG_ 3221225472 ShutdownSw "When the operator enables this switch, all hybrid system functionality is disabled including propulsion, regenerative braking, and hybrid powered accessories.  For electric hybrids, the hybrid system shall be placed in an electrically off state ...";
CM_ SG_ 3221225472 PropulsionDisableSw "When the operator enables this switch, the propulsion aspect of hybrid system operation will be disabled.  However, hybrid powered accessories may be on and the engine may still run.  Regenerative braking is allowed unless disabled by SPN 7552 ...";
CM_ SG_ 3221225472 HybrdSystmCstngRgnrtvBrkngLvlSlc "Indicates the coasting regenerative braking level selector position.  Coasting regenerative braking occurs when neither the accelerator nor the brake pedal are depressed.
The coasting regenerative braking level is the position of the driverís ...";
CM_ SG_ 3221225472 HybrdSystmBrkPdlRgnrtvBrkngDsblS "Indicates the brake pedal regenerative braking disable switch position.  This switch allows the operator to disable regenerative braking (e.g. such as during slippery road conditions) that is controlled by brake pedal application.   Regenerative ...";
CM_ SG_ 3221225472 HybrdSystmRgnrtvBrkngDsbleSwitch "Indicates the regenerative braking disable switch position.  This switch gives the operator the ability to disable all regenerative braking from all inputs (e.g. such as during slippery road conditions).
00b = Regenerative Braking Disable Switch is ...";
CM_ SG_ 3221225472 HybrdSystmPwrElctrncsClntLvlSwtc "Indicates the coolant level switch position in the hybrid system power electronics (e.g. Inverters, DC/DC converters) cooling system.
00b = Coolant Level is not sufficient
01b = Coolant Level is sufficient
10b = Error
11b = Not Available";
CM_ SG_ 3221225472 HybrdSystmPrplsnClantLevelSwitch "Indicates the coolant level switch position in the hybrid system propulsion (e.g. electric motor, generator) cooling system.
00b = Coolant Level is not sufficient
01b = Coolant Level is sufficient
10b = Error
11b = Not Available";
CM_ SG_ 3221225472 HybrdSystmPrtctionOverrideSwitch "Indicates the Protection Override switch position.  This switch allows the operator to override hybrid system protection features and failure modes allowing hybrid system to continue to operate if possible.
00b = Not Active
01b = Active
10b = ...";
CM_ BO_ 2633727071 "Wake : Reserved for Network Operation Mode";
CM_ SG_ 2633727071 ControlBitVector "SPN:8623
The Control Bit Vector shall consist of:
Bit 0: Repeat Message Request
Bit 3: NM Coordinator Sleep Bit
Bit 4 Active Wakeup Bit
";
CM_ BO_ 2633785076 "High Voltage Energy Storage System History
Historical data for High Voltage Energy Storage System (or Pack 1 in systems with only one pack).";
CM_ SG_ 2633785076 HVESSTotalEnergyOut "The cumulative energy which has flowed out of the High Voltage Energy Storage System over the lifetime of the battery system ";
CM_ SG_ 2633785076 HVESSTotalEnergyInput "The cumulative energy which has flowed into the High Voltage Energy Storage System over the lifetime of the battery system (or Pack 1 in systems with only one pack).";
CM_ SG_ 2633785076 HVESSTotalAccumulatedCharge "The total accumulated amp hours which have flowed through High Voltage Energy Storage System (or Pack 1 in systems with only one pack).";
CM_ SG_ 2633785076 HVESSTotalEnergyThroughput "The total energy throughput which has flowed through High Voltage Energy Storage System (or Pack 1 in systems with only one pack).  ";
CM_ SG_ 2633785076 HVESSContactorOpenUnderLoadCount "This signal represents the number of times the contactors inside the High Voltage Energy Storage System ";
CM_ SG_ 2633785076 HVESSStateOfHealth "This signal represents the expected remaining \"Life\" of the High Voltage Energy Storage System (or Pack 1 in systems with only one pack), in percent.  Battery life is a manufacturer-specific measure of how well the energy storage system is ...";
CM_ BO_ 2365484270 "Tachograph";
CM_ SG_ 2365484270 TachographVehicleSpeed "Speed of the vehicle registered by the tachograph.";
CM_ SG_ 2365484270 TachographOutputShaftSpeed "Calculated speed of the transmission output shaft.";
CM_ SG_ 2365484270 DirectionIndicator "Indicates the direction of the vehicle.
00b = Forward
01b = Reverse
10b = Error
11b = Not available";
CM_ SG_ 2365484270 TachographPerformance "Indicates the tachograph performance; including electronic or mechanical analysis, instrument analysis, speed sensor analysis, mass storage analysis, and printer analysis.
00b = Normal performance
01b = Performance analysis
10b = Error
11b = Not ...";
CM_ SG_ 2365484270 HandlingInformation "Indicates that handling information is present.  Information could include \"no printer paper\", \"no driver card\", etc.
00b = No handling information
01b = Handling information
10b = Error
11b = Not available";
CM_ SG_ 2365484270 SystemEvent "Indicates that a tachograph event has occurred. ";
CM_ SG_ 2365484270 DriverCardDriver2 "Indicates the presence of a driver card
00b = Driver card not present
01b = Driver card present
10b = Error
11b = Not available";
CM_ SG_ 2365484270 Driver2TimeRelatedStates "Indicates if the driver approaches or exceeds working time limits (or other limits).";
CM_ SG_ 2365484270 VehicleOverspeed "Indicates whether the vehicle is exceeding the legal speed limit set in the tachograph.
00b = No overspeed
01b = Overspeed
10b = Error
11b = Not available";
CM_ SG_ 2365484270 DriverCardDriver1 "Indicates the presence of a driver card
00b = Driver card not present
01b = Driver card present
10b = Error
11b = Not available";
CM_ SG_ 2365484270 Driver1TimeRelatedStates "Indicates if the driver approaches or exceeds working time limits (or other limits).";
CM_ SG_ 2365484270 VehicleMotion "Indicates whether motion of the vehicle is detected or not.
00b = Vehicle motion not detected
01b = Vehicle motion detected
10b = Error
11b = Not available";
CM_ SG_ 2365484270 Driver2WorkingState "State of work of the driver.";
CM_ SG_ 2365484270 Driver1WorkingState "State of work of the driver.
000b = Rest - sleeping
001b = Driver available - short break
010b = Work - loading, unloading, working in an office
011b = Drive - behind wheel
100b = Reserved
101b = Reserved
110b = Error
111b = Not available...";
CM_ BO_ 2566846554 "Transmission Fluids 1 : ";
CM_ SG_ 2566846554 TransmissionOilTemperature1 "SPN:177
First instance of transmission lubricant temperature.";
CM_ BO_ 2566615642 "MG1IT : Inverter Temperature Status Message";
CM_ SG_ 2566615642 MotorGenerator1InverterTemp1 "SPN:10216
The exact location of this temperature can be defined by the manufacturer.  It is intended to be located somewhere on the inverter. ";
CM_ SG_ 2566615642 MotorGenerator1InverterTemp2 "SPN:10217
The exact location of this temperature can be defined by the manufacturer.  It is intended to be located somewhere on the inverter. ";
CM_ BO_ 2566615386 "Motor/Generator 1 Inverter Motor Temperature : Motor Temperature Status Message";
CM_ SG_ 2566615386 MotorGenerator1Temperature1 "SPN:9059
The exact location of this temperature can be defined by the manufacturer.  It is intended to located somewhere on the motor.";
CM_ SG_ 2566615386 MotorGenerator1Temperature2 "SPN:10220
The exact location of this temperature can be defined by the manufacturer.  It is intended to located somewhere on the motor. ";
CM_ BO_ 2348820747 "Torque/Speed Control 1 : NOTE - Retarder may be disabled by commanding a torque limit of 0%.  ";
CM_ SG_ 2348820747 EngineOverrideControlMode "SPN:695
The override control mode defines which sort of command is used:";
CM_ SG_ 2348820747 EngineRequestedTorqueTorqueLimit "SPN:518
Parameter provided to the engine or retarder in the torque/speed control message for controlling or limiting the output torque.
Requested torque to the engine is measured in indicated torque as a percentage of reference engine torque (see the engine configuration message, PGN 65251). ";
CM_ SG_ 2348820747 TSC1TransmissionRate "SPN:3349
This parameter indicates the transmission rate at which the sending device will transmit the TSC1 message. ";
CM_ SG_ 2348820747 TSC1ControlPurpose "SPN:3350 VVR:[0,6]
State signal which indicates which control mode the sending device is using to generate the TSC1 command.";
CM_ SG_ 2348820747 EngineRequestedTorqueFractional "SPN:4191
This parameter displays an additional torque in percent of the reference engine torque.";
CM_ SG_ 2348820747 TSC1AXR_Counter "SPN:4206 VVR:[0,7]
The message counter is used to detect situations where the transmitting ECU malfunction repeats the same frame all the time.";
CM_ SG_ 2348820747 TSC1AXR_Checksum "SPN:4207
The message checksum is used to verify the signal path from the transmitting device to the receiving device";
CM_ BO_ 2566900510 "PropB_HVJB_06 : High Voltage Junction Box Temperature Measurements";
CM_ SG_ 2566900510 HVJBInternalTemperature1 "SPN:519961
Internal measured temperature";
CM_ SG_ 2566900510 HVJBInternalTemperature2 "SPN:519962
Internal measured temperature";
CM_ SG_ 2566900510 HVJBInternalTemperature3 "SPN:519963
Internal measured temperature";
CM_ SG_ 2566900510 HVJBInternalTemperature4 "SPN:519964
Internal measured temperature";
CM_ SG_ 2566900510 HVJBInternalTemperature5 "SPN:519965
Internal measured temperature";
CM_ SG_ 2566900510 HVJBInternalTemperature6 "SPN:519966
Internal measured temperature";
CM_ SG_ 2566900510 HVJBInternalTemperature7 "SPN:519967
Internal measured temperature";
CM_ SG_ 2566900510 HVJBInternalTemperature8 "SPN:519968
Internal measured temperature";
CM_ BO_ 2566831883 "Wheel Speed Information : ";
CM_ SG_ 2566831883 FrontAxleSpeed "SPN:904 VVR:[0,64255]
The average speed of the two front wheels.";
CM_ SG_ 2566831883 RelativeSpeedFrontAxleLeftWheel "SPN:905
The speed of the front axle, left wheel relative to the front axle speed, SPN 904.";
CM_ SG_ 2566831883 RelativeSpeedFrontAxleRightWheel "SPN:906
The speed of the front axle, right wheel relative to the front axle speed, SPN 904.";
CM_ SG_ 2566831883 RelativeSpeedRearAxle1LeftWheel "SPN:907
The speed of the rear axle #1, left wheel relative to the front axle speed, SPN 904.";
CM_ SG_ 2566831883 RelativeSpeedRearAxle1RightWheel "SPN:908
The speed of the rear axle #1, right wheel relative to the front axle speed, SPN 904.";
CM_ SG_ 2566831883 RelativeSpeedRearAxle2LeftWheel "SPN:909
The speed of the rear axle #2, left wheel relative to the front axle speed, SPN 904.";
CM_ SG_ 2566831883 RelativeSpeedRearAxle2RightWheel "SPN:910
The speed of the rear axle #2, right wheel relative to the front axle speed, SPN 904.";
CM_ BO_ 2566860803 "PropB_Gearbox : PROPB_AST is renamed to PropB_Gearbox";
CM_ SG_ 2566860803 LeverToNeutral "SPN:522911 VVR:[0,1]
";
CM_ SG_ 2566860803 Leverposunequaltodrivepos "SPN:522912 VVR:[0,1]
";
CM_ SG_ 2566860803 ManualShiftingFleetVersion "SPN:523706 VVR:[0,1]
00b = Manual Shifting not allowed (fleet version)
01b = Manual Shifting allowed (fleet version)
10b = Reserved
11b = Dont care/ take no action (no fleet version)";
CM_ SG_ 2566860803 AMIndication "SPN:523631 VVR:[0,2]
Signal to indicate if the A or the M indication on the instrument should be lit.
00b = Off (A and M)
01b = M-indication on
10b = A-Indication on
11b = Reserved";
CM_ SG_ 2566860803 ActivePTO1 "SPN:522914 VVR:[0,1]
This signal indicates the status of the PTO-1 activation permission from AS-Tronic gearbox to BBM. ";
CM_ SG_ 2566860803 ActivePTO2 "SPN:522915 VVR:[0,1]
This signal indicates the status of the PTO-2 activation permission from AS-Tronic gearbox to BBM. ";
CM_ SG_ 2566860803 Directionindicator "SPN:1619
Indicates the direction of the vehicle.
00 - Forward
01 - Reverse
10 - Error
11 - Not available";
CM_ SG_ 2566860803 ECOrollEventWhenDisabled "SPN:524138 VVR:[0,1]
Signal ECOroll Event When Disabled
00b     No Ecoroll event when disabled
01b     Ecoroll event occurred when disabled
10b     Reserved
11b     Dont care/take no action (leave function as is)
";
CM_ BO_ 2566840835 "Transmission Configuration : Total message length depends on total number of forward and reverse gear ratios.NOTE:  The first gear ratio transmitted in bytes 3,4 will be the highest reverse gear ratio.  Additional 2-byte gear ratios will follow:   3,4    Highest reverse gear ratio    .    .   a,b    Lowest reverse gear ratio   c,d    Lowest forward gear ratio    .    .   e,f    Highest forward gear ratio
VARIABLE_DLC_MESSAGE";
CM_ SG_ 2566840835 NumberofReverseGearRatios "SPN:958 VVR:[0,250]
Number of reverse gear ratios in the transmission, provided as part of the transmission configuration.";
CM_ SG_ 2566840835 NumberofForwardGearRatios "SPN:957 VVR:[0,250]
Number of forward gear ratios in the transmission, provided as part of the configuration.";
CM_ SG_ 2566840835 TransmissionGearRatio "SPN:581 VVR:[0,64255]
The transmission configuration describes the number of forward gears, the number of reverse gears, and the ratio of each gear with the following resolution.";
CM_ BO_ 2364539395 "Electronic Transmission Controller 1 : Electronic Transmission Controller #1Note:Single input shaft transmissions should use SPN 161 (Transmission Input Shaft Speed)";
CM_ SG_ 2364539395 TransmissionDrivelineEngaged "SPN:560
Driveline engaged indicates the transmission controlled portion of the driveline is engaged sufficiently to allow a transfer of torque through the transmission.  ";
CM_ SG_ 2364539395 TransTrqConverterLockupEngaged "SPN:573 VVR:[0,1]
State signal which indicates whether the torque converter lockup is engaged.
00 Torque converter lockup disengaged
01 Torque converter lockup engaged
10 Error
11 Not available";
CM_ SG_ 2364539395 TransmissionShiftInProcess "SPN:574
Indicates that the transmission is in process of shifting from the current gear to the selected gear. This state is generally ACTIVE during the entire time that the transmission controls the vehicle during a shift. This includes any transmission clutch control, all engine control sequences, pulling to transmission neutral, and engaging the destination gear (e.g., until it is no longer sending commands and/or limits to the engine). See also SPN 560. (See Figure SPN574_A)";
CM_ SG_ 2364539395 TransmissionOutputShaftSpeed "SPN:191 VVR:[0,64255]
Calculated speed of the transmission output shaft.";
CM_ SG_ 2364539395 PercentClutchSlip "SPN:522 VVR:[0,250]
Parameter which represents the ratio of input shaft speed to current engine speed (in percent).
Percent Clutch Slip = ((Engine rpm - Input shaft rpm)/(Engine rpm)) x 100";
CM_ SG_ 2364539395 ProgressiveShiftDisable "SPN:607 VVR:[0,1]
Command signal used to indicate that progressive shifting by the engine should be disallowed.
00 Progressive shift is not disabled
01 Progressive shift is disabled
10 Reserved
11 Take no action";
CM_ SG_ 2364539395 TransmissionInputShaftSpeed "SPN:161 VVR:[0,64255]
Rotational velocity of the primary shaft transferring power into the transmission.  When a torque converter is present, it is the output of the torque converter.";
CM_ BO_ 2566801923 "Electronic Transmission Controller 7 : Transmission status information from the transmission controller to network.";
CM_ SG_ 2566801923 TransmissionReadyforBrakeRelease "SPN:3086
This parameter indicates that enough torque / motive force is available at the transmission output shaft to release all the brakes without a risk of unintentional movement in the opposite direction.";
CM_ SG_ 2566801923 TransmissionEngineCrankEnable "SPN:2900 VVR:[0,1]
State signal from the transmission indicating if the transmissions status is such that engine cranking is allowed (i.e.  at a minimum, transmission is in neutral and the driveline is disengaged). ";
CM_ SG_ 2566801923 TransmissionMode2Indicator "SPN:2537
This state signal is the transmissions indication that it is operating under transmission mode 2 (SPN 1853) as commanded via the TC1 message (PGN 256). ";
CM_ SG_ 2566801923 TransmissionMode1Indicator "SPN:2536
This state signal is the transmissions indication that it is operating under transmission mode 1 (SPN 1852) as commanded via the TC1 message (PGN 256).  The definition of the transmission mode is left to the discretion of the transmission manufacturer.
00 Transmission Mode 1 not active
01 Transmission Mode 1 Active
10 Error
11 Not available";
CM_ SG_ 2566801923 TransmissionMode6Indicator "SPN:4251
This state signal is the transmissions indication that it is operating under transmission mode 6 (SPN 4247) as commanded via the TC1 message (PGN 256).";
CM_ SG_ 2566801923 TransmissionMode7Indicator "SPN:4252
This state signal is the transmissions indication that it is operating under transmission mode 7 (SPN 4248) as commanded via the TC1 message (PGN 256).";
CM_ SG_ 2566801923 TransmissionMode8Indicator "SPN:4253
This state signal is the transmissions indication that it is operating under transmission mode 8 (SPN 4249) as commanded via the TC1 message (PGN 256). ";
CM_ BO_ 2364606708 "High Voltage Energy Storage System Module Status 1 : Module Status message 1 for High Voltage Energy Storage System (or Pack 1 in systems with only one pack).";
CM_ SG_ 2364606708 HVESSModule1OperationalStatus "SPN:8214
Operational Status of Module 1 in the High Voltage Energy Storage System (or Pack 1 in systems with only one pack)";
CM_ SG_ 2364606708 HVESSModule2OperationalStatus "SPN:8215
Operational Status of Module 2 in the High Voltage Energy Storage System (or Pack 1 in systems with only one pack)";
CM_ SG_ 2364606708 HVESSModule3OperationalStatus "SPN:8216
Operational Status of Module 3 in the High Voltage Energy Storage System (or Pack 1 in systems with only one pack)";
CM_ SG_ 2364606708 HVESSModule4OperationalStatus "SPN:8217
Operational Status of Module 4 in the High Voltage Energy Storage System (or Pack 1 in systems with only one pack)";
CM_ SG_ 2364606708 HVESSModule5OperationalStatus "SPN:8218
Operational Status of Module 5 in the High Voltage Energy Storage System (or Pack 1 in systems with only one pack)";
CM_ SG_ 2364606708 HVESSModule6OperationalStatus "SPN:8219
Operational Status of Module 6 in the High Voltage Energy Storage System (or Pack 1 in systems with only one pack)";
CM_ SG_ 2364606708 HVESSModule7OperationalStatus "SPN:8220
Operational Status of Module 7 in the High Voltage Energy Storage System (or Pack 1 in systems with only one pack)";
CM_ SG_ 2364606708 HVESSModule8OperationalStatus "SPN:8221
Operational Status of Module 8 in the High Voltage Energy Storage System (or Pack 1 in systems with only one pack)";
CM_ SG_ 2364606708 HVESSModule9OperationalStatus "SPN:8222
Operational Status of Module 9 in the High Voltage Energy Storage System (or Pack 1 in systems with only one pack)";
CM_ BO_ 2364552948 "High Voltage Energy Storage System Status 2 : Status data set 2 for High Voltage Energy Storage System (or Pack 1 in systems with only one pack).";
CM_ SG_ 2364552948 DischargePowlimIsBatTemperature "SPN:8104
Indicates whether or not discharge power of this HVES instance is being limited due to battery temperature.
This parameter provides HVES system level information. If there are multiple packs in the system, then both individual pack messages (e.g. HVESP1, HVESP2 etc.)";
CM_ SG_ 2364552948 DischargePowlimIsBatDiagConditio "SPN:8105
Indicates whether or not discharge power of this HVES instance is being limited due to a battery diagnostic condition.";
CM_ SG_ 2364552948 DischargePowlimIsBatorCellVoltag "SPN:8106
Indicates whether or not discharge power of this HVES instance is being limited due to a battery or cell voltage level.";
CM_ SG_ 2364552948 DischargePowlimIsBatteryCurrent "SPN:8107
Indicates whether or not discharge power of this HVES instance is being limited due to battery current.";
CM_ SG_ 2364552948 ChargePowlimIsBatteryTemperature "SPN:8110
Indicates whether or not charge power of this HVES instance is being limited due to battery temperature.";
CM_ SG_ 2364552948 ChargePowlimIsBatDiagCondition "SPN:8111
Indicates whether or not charge power of this HVES instance is being limited due to a battery diagnostic condition.";
CM_ SG_ 2364552948 ChargePowlimIsBatorCellVoltage "SPN:8112
Indicates whether or not charge power of this HVES instance is being limited due to a battery or cell voltage level.";
CM_ SG_ 2364552948 ChargePowlimIsBatteryCurrent "SPN:8113
Indicates whether or not charge power of this HVES instance is being limited due to battery current.";
CM_ SG_ 2364552948 ChargePowlimIsanUndefinedCause "SPN:8114
Indicates whether or not charge power of this HVES instance is being limited due to an undefined cause.";
CM_ BO_ 2565866755 "Electronic Transmission Controller 2 : ";
CM_ SG_ 2565866755 TransmissionSelectedGear "SPN:524
The gear that the transmission will attempt to achieve during the current shift if a shift is in progress, or the next shift if one is pending (i.e., waiting for torque reduction to initiate the shift).";
CM_ SG_ 2565866755 TransmissionActualGearRatio "SPN:526 VVR:[0,64255]
Actual ratio of input shaft speed to output shaft speed.";
CM_ SG_ 2565866755 TransmissionCurrentGear "SPN:523
The gear currently engaged in the transmission or the last gear engaged while the transmission is in the process of shifting to the new or selected gear. ";
CM_ SG_ 2565866755 TransmissionRequestedRange "SPN:162 VVR:[1,254]
Range selected by the operator.  Characters may include P, Rx, Rx-1...R2, R1, R, Nx, Nx-1...N2, N1, N, D, D1, D2..., Dx, L, L1, L2..., Lx-1, 1, 2, 3,... ";
CM_ BO_ 2583630324 "PropB_HVESS_01 : High Voltage Energy Storage System information";
CM_ SG_ 2583630324 ChargingTimeTillFullSOCEst "SPN:520171 VVR:[0,64255]
This signal indicates the estimated charging time till 100% State of Charge.";
CM_ SG_ 2583630324 ChargingTimeTillFullSOCRec "SPN:520172 VVR:[0,64255]
This signal indicates the estimated charging time till received target State of Charge.";
CM_ BO_ 2348810251 "Torque/Speed Control 1 : NOTE - Retarder may be disabled by commanding a torque limit of 0%.  Use of the limit mode allows the use of the retarder only up to the limit specified in the request. ";
CM_ SG_ 2348810251 EngineOverrideControlMode "SPN:695
The override control mode defines which sort of command is used";
CM_ SG_ 2348810251 OverrideControlModePriority "SPN:897
This field is used as an input to the engine or retarder to determine the priority of the Override Control Mode received in the Torque/Speed Control message (see PGN 0).  ";
CM_ SG_ 2348810251 EngineRequestedTorqueTorqueLimit "SPN:518
Parameter provided to the engine or retarder in the torque/speed control message for controlling or limiting the output torque. ";
CM_ SG_ 2348810251 TSC1TransmissionRate "SPN:3349
This parameter indicates the transmission rate at which the sending device will transmit the TSC1 message. ";
CM_ SG_ 2348810251 TSC1ControlPurpose "SPN:3350 VVR:[0,6]
State signal which indicates which control mode the sending device is using to generate the TSC1 command. ";
CM_ SG_ 2348810251 EngineRequestedTorqueFractional "SPN:4191
This parameter displays an additional torque in percent of the reference engine torque.";
CM_ SG_ 2348810251 MessageCounter "SPN:4206 VVR:[0,7]
The message counter is used to detect situations where the transmitting ECU malfunction repeats the same frame all the time.";
CM_ SG_ 2348810251 MessageChecksum "SPN:4207
The message checksum is used to verify the signal path from the transmitting device to the receiving device.";
CM_ BO_ 2348810400 "Torque/Speed Control 1 : NOTE - Retarder may be disabled by commanding a torque limit of 0%.  Use of the limit mode allows the use of the retarder only up to the limit specified in the request. ";
CM_ SG_ 2348810400 EngineOverrideControlMode "SPN:695
The override control mode defines which sort of command is used:";
CM_ SG_ 2348810400 OverrideControlModePriority "SPN:897
This field is used as an input to the engine or retarder to determine the priority of the Override Control Mode received in the Torque/Speed Control message (see PGN 0).";
CM_ SG_ 2348810400 EngineRequestedTorqueTorqueLimit "SPN:518
Parameter provided to the engine or retarder in the torque/speed control message for controlling or limiting the output torque.";
CM_ SG_ 2348810400 TSC1TransmissionRate "SPN:3349
This parameter indicates the transmission rate at which the sending device will transmit the TSC1 message. ";
CM_ SG_ 2348810400 TSC1ControlPurpose "SPN:3350 VVR:[0,6]
State signal which indicates which control mode the sending device is using to generate the TSC1 command.  Note that the modes are not in prioritized order. ";
CM_ SG_ 2348810400 MessageCounter "SPN:4206 VVR:[0,7]
The message counter is used to detect situations where the transmitting ECU malfunction repeats the same frame all the time. ";
CM_ SG_ 2348810400 MessageChecksum "SPN:4207
The message checksum is used to verify the signal path from the transmitting device to the receiving device.";
CM_ SG_ 2566844711 TwoSpeedAxleSwitch "SPN:69
Switch signal which indicates the current axle range.
00 - Low speed range
01 - High speed range
10 - Error
11 - Not available";
CM_ SG_ 2566844711 ParkingBrakeSwitch "SPN:70
Switch signal which indicates when the parking brake is set. ";
CM_ SG_ 2566844711 CruiseControlPauseSwitch "SPN:1633
Switch signal which indicates the position of the Cruise Control Pause Switch used on Remote Cruise Control applications. ";
CM_ SG_ 2566844711 WheelBasedVehicleSpeed "SPN:84 VVR:[0,64255]
Speed of the vehicle as calculated from wheel or tailshaft speed.";
CM_ SG_ 2566844711 CruiseControlActive "SPN:595
Cruise control is switched on.  It is not ensured that the engine is controlled by cruise control, as in the case of a large drivers demand the engine is controlled by the driver while cruise control is active ";
CM_ SG_ 2566844711 CruiseControlEnableSwitch "SPN:596
Switch signal which indicates that it is possible to manage the cruise control function.
00 - Cruise control disabled
01 - Cruise control enabled
10 - Error
11 - Not available";
CM_ SG_ 2566844711 BrakeSwitch "SPN:597
Switch signal which indicates that the driver operated brake foot pedal is being pressed. ";
CM_ SG_ 2566844711 ClutchSwitch "SPN:598
Switch signal which indicates that the clutch pedal is being pressed. ";
CM_ SG_ 2566844711 CruiseControlSetSwitch "SPN:599
Switch signal of the cruise control activator which indicates that the activator is in the position set
00 - Cruise control activator not in the position set
01 - Cruise control activator in position set
10 - Error
11 - Not available";
CM_ SG_ 2566844711 CruiseCtrlCoastDecelerateSwitch "SPN:600
Switch signal of the cruise control activator which indicates that the activator is in the position coast (decelerate).";
CM_ SG_ 2566844711 CruiseControlResumeSwitch "SPN:601
Switch signal of the cruise control activator which indicates that the activator is in the position resume.";
CM_ SG_ 2566844711 CruiseControlAccelerateSwitch "SPN:602
Switch signal of the cruise control activator which indicates that the activator is in the position accelerate.";
CM_ SG_ 2566844711 CruiseControlSetSpeed "SPN:86 VVR:[0,250]
Value of set (chosen) velocity of velocity control system.  See SPN 6809 for an alternate resolution.";
CM_ SG_ 2566844711 PTOGovernorState "SPN:976 VVR:[0,20]
This parameter is used to indicate the current state or mode of operation by the power takeoff (PTO) governor. ";
CM_ SG_ 2566844711 CruiseControlStates "SPN:527
This parameter is used to indicate the current state, or mode, of operation by the cruise control device.  ";
CM_ BO_ 2566857255 "PropB_VECU_TC1 : VECU Transmission Control 01";
CM_ SG_ 2566857255 TransmissionRequestedGear "SPN:525
Parameter specific values for this parameter are as follows:";
CM_ SG_ 2566857255 VECU_TC1_Counter "SPN:4206 VVR:[0,7]
The message counter is used to detect situations where the transmitting ECU malfunction repeats the same frame all the time. ";
CM_ SG_ 2566857255 VECU_TC1_Checksum "SPN:4207 VVR:[0,7]
The message checksum is used to verify the signal path from the transmitting device to the receiving device.";
CM_ BO_ 2351323687 "MG1IC : Primary Control Message from this instance of Inverter.  Some examples of use would be for a hybrid or electric vehicle propulsion motor or generator.";
CM_ SG_ 2351323687 MG1InvCtrlCRC "SPN:10157
The CRC is defined as follows: - Length: 8 bits - Polynomial: x^8+x^5+x^3+x^2+x+1";
CM_ SG_ 2351323687 MG1InvCtrlCount "SPN:10158
The message counter is used to detect situations where the transmitting ECU malfunction repeats the same frame all the time. ";
CM_ SG_ 2351323687 MG1InvCtrlSetPoint "SPN:10162 VVR:[5,12]
Requests the modes for this instance of the inverter.  See SPN 10167 [Control Setpoint Mode] for the feedback to this request.
Passive modes:  Modes where the inverter does not actively control the motor torque, for example.";
CM_ BO_ 2348833280 "Torque/Speed Control 1 : NOTE - Retarder may be disabled by commanding a torque limit of 0%.
Note that the 10 ms transmission repetition rate is intended for temporary powertrain control (P32 of SPN 3350).  Slower transmission rates (for control purposes P1 through P31 of SPN 3350) may be supported for longer duration control.";
CM_ SG_ 2348833280 EngineOverrideControlMode "SPN:695
The override control mode defines which sort of command is used:";
CM_ SG_ 2348833280 EngineRequestedTorqueTorqueLimit "SPN:518
Parameter provided to the engine or retarder in the torque/speed control message for controlling or limiting the output torque.
Requested torque to the engine is measured in indicated torque as a percentage of reference engine torque ";
CM_ SG_ 2348833280 TSC1TransmissionRate "SPN:3349
This parameter indicates the transmission rate at which the sending device will transmit the TSC1 message. ";
CM_ SG_ 2348833280 TSC1ControlPurpose "SPN:3350 VVR:[0,6]
State signal which indicates which control mode the sending device is using to generate the TSC1 command.  Note that the modes are not in prioritized order. ";
CM_ SG_ 2348833280 EngineRequestedTorqueFractional "SPN:4191
This parameter displays an additional torque in percent of the reference engine torque.";
CM_ SG_ 2348833280 MessageCounter "SPN:4206 VVR:[0,7]
The message counter is used to detect situations where the transmitting ECU malfunction repeats the same frame all the time.  The receiver of the information may use the counter parameter to detect this situation.  ";
CM_ SG_ 2348833280 MessageChecksum "SPN:4207
The message checksum is used to verify the signal path from the transmitting device to the receiving device.";
CM_ BO_ 2348833321 "Torque/Speed Control 1 : NOTE - Retarder may be disabled by commanding a torque limit of 0%.
Note that the 10 ms transmission repetition rate is intended for temporary powertrain control (P32 of SPN 3350).  Slower transmission rates (for control purposes P1 through P31 of SPN 3350) may be supported for longer duration control.";
CM_ SG_ 2348833321 EngineOverrideControlMode "SPN:695
The override control mode defines which sort of command is used:";
CM_ SG_ 2348833321 EngineRequestedTorqueTorqueLimit "SPN:518
Parameter provided to the engine or retarder in the torque/speed control message for controlling or limiting the output torque. ";
CM_ SG_ 2348833321 TSC1TransmissionRate "SPN:3349
This parameter indicates the transmission rate at which the sending device will transmit the TSC1 message.";
CM_ SG_ 2348833321 EngineRequestedTorqueFractional "SPN:4191
This parameter displays an additional torque in percent of the reference engine torque.";
CM_ SG_ 2348833321 MessageCounter "SPN:4206 VVR:[0,7]
The message counter is used to detect situations where the transmitting ECU malfunction repeats the same frame all the time. ";
CM_ SG_ 2348833321 MessageChecksum "SPN:4207
The message checksum is used to verify the signal path from the transmitting device to the receiving device.";
CM_ BO_ 2350642267 "High Voltage Energy Storage System Control 1 : Control commands to be sent to High Voltage Energy Storage System (or Pack 1 in systems with only one pack).";
CM_ SG_ 2350642267 HVESSHighVoltageBusConnectCmd "SPN:8123
Command to connect the High Voltage Energy Storage System (or Pack 1 in systems with only one pack) to the high-voltage bus.  ";
CM_ SG_ 2350642267 HVESSPowerDownCommand "SPN:8124
Command to shut down the High Voltage Energy Storage System (or Pack 1 in systems with only one pack). ";
CM_ SG_ 2350642267 HVESSHighVoltageBusPassiveIsolat "SPN:8126
Command for the High Voltage Energy Storage System (or Pack 1 in systems with only one pack) to perform a passive electrical isolation test on the high voltage bus.";
CM_ SG_ 2350642267 HVESSControl1Counter "SPN:13027
The message counter is used to detect situations where the transmitting ECU malfunction repeats the same frame all the time.";
CM_ SG_ 2350642267 HVESSControl1CRC "SPN:13028";
CM_ BO_ 2364539738 "Electronic Engine Controller 2 : Identifies electronic engine control related parameters.";
CM_ SG_ 2364539738 ActMaximumAvailEngPercentTorque "SPN:3357 VVR:[0,250]
This is the maximum amount of torque that the engine can immediately deliver as a percentage of the reference engine torque (SPN 544). ";
CM_ BO_ 2364539994 "Electronic Engine Controller 1 : Engine related parameters";
CM_ SG_ 2364539994 EngineTorqueMode "SPN:899
State signal which indicates which engine torque mode is currently generating, limiting, or controlling the torque. ";
CM_ SG_ 2364539994 ActEnginePercentTorqueFractional "SPN:4154
This parameter displays an additional torque in percent of the reference engine torque.";
CM_ SG_ 2364539994 ActualEnginePercentTorque "SPN:513
The calculated output torque of the engine.  The data is transmitted in indicated torque as a percent of reference engine torque (see the engine configuration message, PGN 65251). ";
CM_ SG_ 2364539994 EngineSpeed "SPN:190 VVR:[0,64255]
Actual engine speed which is calculated over a minimum crankshaft angle of 720 degrees divided by the number of cylinders.";
CM_ BO_ 2364575988 "High Voltage Energy Storage System Data 1 : Data set 1 (electrical data) for High Voltage Energy Storage System (or Pack 1 in systems with only one pack).High Voltage Energy Storage System Data 1 : Data set 1 (electrical data) for High Voltage Energy Storage System (or Pack 1 in systems with only one pack).";
CM_ SG_ 2364575988 HVESSAvailableDischargePower "SPN:5917 VVR:[0,64255]
The rate at which the High Voltage Energy Storage System (or Pack 1 in systems with only one pack) can currently provide energy for propulsion or other uses.";
CM_ SG_ 2364575988 HVESSAvailableChargePower "SPN:5918 VVR:[0,64255]
The rate at which the High Voltage Energy Storage System (or Pack 1 in systems with only one pack) can currently receive energy from a regenerative or recharging system.";
CM_ SG_ 2364575988 HVESSVoltageLevel "SPN:5919 VVR:[0,64255]
The voltage level of the High Voltage Energy Storage System (or Pack 1 in systems with only one pack). ";
CM_ SG_ 2364575988 HVESSCurrent "SPN:5920
The current in or out of the High Voltage Energy Storage System (or Pack 1 in systems with only one pack).";
CM_ BO_ 2364576244 "High Voltage Energy Storage System Data 2
Data set 2 (electrical data) for High Voltage Energy Storage System (or Pack 1 in systems with only one pack).";
CM_ SG_ 2364576244 HVESSCellVoltageDifferenceStatus "Indicates whether or not the differential between the highest and lowest cell voltages are within acceptable limits, according to the hvess (or Pack 1 in systems with only one pack).  ";
CM_ SG_ 2364576244 HVESSLowestCellVoltage "The lowest voltage level reported by any cell in the High Voltage Energy Storage System (or Pack 1 in systems with only one pack).";
CM_ SG_ 2364576244 HVESSHighestCellVoltage "The highest voltage level reported by any cell in the High Voltage Energy Storage System (or Pack 1 in systems with only one pack).";
CM_ SG_ 2364576244 HVESSFastUpdateStateofCharge "Indicates the High Voltage Energy Storage System (or Pack 1 in systems with only one pack) state of charge. 0% means no charge remaining, 100% means the system is fully charged in terms of physical limits of the energy storage system. Acceptable ...";
CM_ BO_ 2364576500 "High Voltage Energy Storage System Data 3 : Data set 3 (thermal data) for High Voltage Energy Storage System (or Pack 1 in systems with only one pack).";
CM_ SG_ 2364576500 HVESSHighestCellTemperature "SPN:8075
The highest temperature level reported by any cell in the High Voltage Energy Storage System (or Pack 1 in systems with only one pack)";
CM_ SG_ 2364576500 HVESSLowestCellTemperature "SPN:8076
The lowest temperature level reported by any cell in the High Voltage Energy Storage System (or Pack 1 in systems with only one pack). ";
CM_ SG_ 2364576500 HVESSAverageCellTemperature "SPN:8077
The average temperature level of all cells in the High Voltage Energy Storage System (or Pack 1 in systems with only one pack).";
CM_ BO_ 2364577012 "High Voltage Energy Storage System Data 5 : Data set 5 (electrical data) for High Voltage Energy Storage System (or Pack 1 in systems with only one pack).";
CM_ SG_ 2364577012 HVESSMaxCellStateOfCharge "Indicates the state of charge of the highest-charged cell in the High Voltage Energy Storage System (or Pack 1 in systems with only one pack). ";
CM_ SG_ 2364577012 HVESSMinCellStateOfCharge "Indicates the state of charge of the lowest-charged cell in the High Voltage Energy Storage System (or Pack 1 in systems with only one pack).  ";
CM_ SG_ 2364577012 HVESSDischargeCurrentLimit "SPN:8082
The maximum permissible current flow out of the High Voltage Energy Storage System (or Pack 1 in systems with only one pack). ";
CM_ SG_ 2364577012 HVESSChargeCurrentLimit "SPN:8083
The maximum permissible current flow into the High Voltage Energy Storage System (or Pack 1 in systems with only one pack). ";
CM_ BO_ 2364577524 "High Voltage Energy Storage System Status 1 : Status data set 1 for High Voltage Energy Storage System (or Pack 1 in systems with only one pack).";
CM_ SG_ 2364577524 HVESSHighVoltageBusPassiveIsolat "SPN:8097 VVR:[0,6]
Status of the high-voltage bus electrical passive isolation test as performed by the High Voltage Energy Storage System (";
CM_ SG_ 2364577524 HVESSHVILStatus "SPN:8098
Status of the High Voltage Interlock Loop from the viewpoint of the High Voltage Energy Storage System (or Pack 1 in systems with only one pack).";
CM_ SG_ 2364577524 HVESSStatus1Counter "SPN:13013
The message counter is used to detect situations where the transmitting ECU malfunction repeats the same frame all the time. ";
CM_ SG_ 2364577524 HVESSHighVoltageBusConState "SPN:8413 VVR:[0,4]
This parameter provides high level feedback on the High Voltage Energy Storage System (or Pack 1 in systems with only one pack) high voltage bus connection. ";
CM_ SG_ 2364577524 HVESSOperationalStatus "SPN:8414 VVR:[0,6]
Provides feedback on where the High Voltage Energy Storage System (or Pack 1 in systems with only one pack) is in its operating spectrum,";
CM_ SG_ 2364577524 HVESSStatus1CRC "SPN:13014
The CRC is defined as follows:
- Length: 8 bits
- Polynomial: x^8+x^5+x^3+x^2+x+1
- Initial Value: FFh";
CM_ BO_ 2364580084 "High Voltage Energy Storage System Data 7 : Data set 7 (electrical) for High Voltage Energy Storage System (or Pack 1 in systems with only one pack).";
CM_ SG_ 2364580084 HVESSMaximumChargeVoltageLimit "SPN:8090 VVR:[0,64255]
The maximum voltage level not to be exceeded while charging the High Voltage Energy Storage System (or Pack 1 in systems with only one pack). ";
CM_ SG_ 2364580084 HVESSChargeEnergyCapacity "The amount of unused electrical energy storage available to be filled by charging High Voltage Energy Storage System (or Pack 1 in systems with only one pack), i.e. ‚Äúhow much empty space is remaining in the tank‚Äù. See SPN 8080 (HVESS Charge ...";
CM_ SG_ 2364580084 HVESSDischargeEnergyCapacity "The amount of stored electrical energy in High Voltage Energy Storage System (or Pack 1 in systems with only one pack) that is available for use by the hybrid system, i.e. ‚Äúhow full is the tank‚Äù. See SPN 8079 (HVESS Discharge Capacity) for ...";
CM_ BO_ 2364606964 "High Voltage Energy Storage System Thermal Management System Status 1 : Collection of data the High Voltage Energy Storage System (or Pack 1 in systems with only one pack) Thermal Management System sends to the Hybrid Controller.High Voltage Energy Storage System Thermal Management System Status 1 : Collection of data the High Voltage Energy Storage System (or Pack 1 in systems with only one pack) Thermal Management System sends to the Hybrid Controller.";
CM_ SG_ 2364606964 HVESSThermalManagementSystemHtrS "SPN:8234
The state of the High Voltage Energy Storage System (or Pack 1 in systems with only one pack) heater
This parameter provides HVES system level information. If there are multiple packs in the system,";
CM_ BO_ 2364637530 "Motor/Generator 1 Inverter Mode Feedback 1 : The first mode feedback message from the inverter.";
CM_ SG_ 2364637530 MG1InvModeFeedbackCRC "SPN:10164
The CRC is defined as follows:";
CM_ SG_ 2364637530 MG1InvModeFeedbackCounter "SPN:10165
The message counter is used to detect situations where the transmitting ECU malfunction repeats the same frame all the time.";
CM_ BO_ 2566841178 "Engine Configuration 1";
CM_ SG_ 2566841178 SupportTSC1CtrlPurposeGroup4 "This parameter indicates which TSC1 control purposes are supported in group 4 of 4.";
CM_ SG_ 2566841178 SupportTSC1CtrlPurposeGroup3 "This parameter indicates which TSC1 control purposes are supported in group 3 of 4.";
CM_ SG_ 2566841178 SupportTSC1CtrlPurposeGroup2 "This parameter indicates which TSC1 control purposes are supported in group 2 of 4.";
CM_ SG_ 2566841178 SupportTSC1CtrlPurposeGroup1 "This parameter indicates which TSC1 control purposes are supported in group 1 of 4.";
CM_ SG_ 2566841178 SupportVariableRateTSC1Message "This parameter indicates which TSC1 transmission rates are supported by the engine ECU in addition to the required";
CM_ SG_ 2566841178 EngDefaultTorqueLimit "Companion parameter to Transmission Torque Limit (SPN 1845).";
CM_ SG_ 2566841178 EngMomentOfInertia "Moment of inertia for the engine, including items driven full-time by the engine such as fuel, oil and cooling pumps.";
CM_ SG_ 2566841178 EngExRngRqdSpdCtrlRngUpperLimit "The maximum engine speed regardless of load that the engine will allow when operating in a speed control/limit mode,";
CM_ SG_ 2566841178 EngRqdTorqueCtrlRangeUpperLimit "The maximum engine torque that the engine will allow when operating in a torque control/limit mode.";
CM_ SG_ 2566841178 EngRqdTorqueCtrlRangeLowerLimit "The minimum engine torque that the engine will allow when operating in a torque control/limit mode.";
CM_ SG_ 2566841178 EngRqedSpeedCtrlRangeUpperLimit "The maximum engine speed regardless of load that the engine will allow when operating in a speed control/limit mode,";
CM_ SG_ 2566841178 EngRqedSpeedCtrlRangeLowerLimit "The minimum engine speed that the engine will allow when operating in a speed control/limit mode.";
CM_ SG_ 2566841178 EngMxMomentaryOverrideTimeLimit "The maximum time limit allowed to override the engine's high idle speed.";
CM_ SG_ 2566841178 EngMxMmntaryOverrideSpeedPoint7 "The maximum engine speed above high idle allowed by the engine control during a momentary high idle override.";
CM_ SG_ 2566841178 EngReferenceTorque "This parameter is the 100% reference value for all defined indicated engine torque parameters.";
CM_ SG_ 2566841178 EngSpeedAtHighIdlePoint6 "Engine speed of high idle (point 6) of the engine torque map (see PGN 65251 and supporting document).";
CM_ SG_ 2566841178 EngGainOfEndspeedGovernor "The endspeed governor is defined as a linear line with the following equations (Capital letters mean physical values, small";
CM_ SG_ 2566841178 EngPercentTorqueAtPoint5 "The torque limit that indicates the available engine torque which can be provided by the engine at point 3, 4, and 5 of the";
CM_ SG_ 2566841178 EngSpeedAtPoint5 "Engine speed of point 3, 4, and 5 of the engine torque map (see PGN 65251 and supporting document).";
CM_ SG_ 2566841178 EngPercentTorqueAtPoint4 "The torque limit that indicates the available engine torque which can be provided by the engine at point 3, 4, and 5 of the";
CM_ SG_ 2566841178 EngSpeedAtPoint4 "Engine speed of point 3, 4, and 5 of the engine torque map (see PGN 65251 and supporting document).";
CM_ SG_ 2566841178 EngPercentTorqueAtPoint3 "The torque limit that indicates the available engine torque which can be provided by the engine at point 3, 4, and 5 of the";
CM_ SG_ 2566841178 EngSpeedAtPoint3 "Engine speed of point 3, 4, and 5 of the engine torque map (see PGN 65251 and supporting document).";
CM_ SG_ 2566841178 EngPercentTorqueAtPoint2 "The torque limit that indicates the available engine torque which can be provided by the engine at point 2 of the engine";
CM_ SG_ 2566841178 EngSpeedAtPoint2 "Engine speed of point 2 of the engine torque map (see PGN 65251 and supporting document).";
CM_ SG_ 2566841178 EngPercentTorqueAtIdlePoint1 "The torque limit that indicates the available engine torque which can be provided by the engine at idle speed.";
CM_ SG_ 2566841178 EngSpeedAtIdlePoint1 "Stationary low idle speed of engine which includes influences due to engine temperature (after power up) and other";
CM_ BO_ 2365289306 "Motor/Generator 1 Inverter Reference 2 : The electrical reference values from this inverter.";
CM_ SG_ 2365289306 MG1InvReferenceVoltage "SPN:10203 VVR:[0,64255]
This value is used for converting inverter voltage in percent to units of Volts (RMS or DC).
(Value in Volts) = (Percent Value)/(100%) * (Reference Voltage)
";
CM_ SG_ 2365289306 MG1InvReferenceCRC "SPN:10200
The CRC is defined as follows:
- Length: 8 bits
- Polynomial: x^8+x^5+x^3+x^2+x+1
- Initial Value: FFh
- Input Data Reflection: Not reflected
- Result Data Reflection: Not reflected
- XOR value: FFh
SAE makes no claim of the functional safety level achieved by this CRC. ";
CM_ SG_ 2365289306 MG1InvReferenceCounter "SPN:10201";
CM_ SG_ 2365289306 MG1InvReferenceCurrent "SPN:10202 VVR:[0,64255]
This value is used for converting inverter current in percent to units of Amps (RMS or DC).
(Value in Amps) = (Percent Value)/(100%) * (Reference Current)";
CM_ BO_ 2365289562 "Motor/Generator 1 Inverter Status 1 : First Status Message from the Inverter.  Some examples of use would be for a hybrid or electric vehicle propulsion motor or generator.";
CM_ SG_ 2365289562 MG1InvDCCurrentAbs "SPN:10175
This is the DC side current of the inverter.";
CM_ SG_ 2365289562 MG1InvStatus1CRC "SPN:10173";
CM_ SG_ 2365289562 MG1InvStatus1Counter "SPN:10174
The message counter is used to detect situations where the transmitting ECU malfunction repeats the same frame all the time.";
CM_ SG_ 2365289562 MG1InvDCCurrent "SPN:10175
This is the DC side current of the inverter.";
CM_ BO_ 2556320347 "Motor/Generator 1 Inverter Limits Request DC Side : Sets the DC Side Voltage and Current limits for the inverter being controlled.  Some examples of use would be for a hybrid or electric vehicle propulsion motor or generator.";
CM_ SG_ 2556320347 MG1ILRDC_CRC "SPN:10204
The CRC is defined as follows:";
CM_ SG_ 2556320347 MG1ILRDC_Counter "SPN:10205
The message counter is used to detect situations where the transmitting ECU malfunction repeats the same frame all the time. ";
CM_ SG_ 2556320347 MG1ReqDCCurrentMax "SPN:10208
This is a request to the inverter to set a maximum DC Side Current limit for this device instance.";
CM_ SG_ 2556320347 MG1ReqDCCurrentMin "SPN:10209
This is a request to the inverter to set a minimum DC Side Current limit for this device instance.";
CM_ BO_ 2564882267 "Cab Message 1 : Message containing parameters originating from the vehicle cab.";
CM_ SG_ 2564882267 AuxiliaryHtrCoolantPumpRequest "SPN:1684 VVR:[0,1]
Indicates whether to activate the auxiliary heater coolant water pump.
00b = Deactivate water pump
01b = Activate water pump
10b = Reserved
11b = Dont care/take no action";
CM_ BO_ 2565537627 "Request : This message type, identified by the PGN, provides the capability to request information globally or from a specific destination.";
CM_ SG_ 2565537627 ParameterGroupNumberRQST "SPN:2540 VVR:[0,262143]
Whenever it is necessary to identify a Parameter Group in the data field of a CAN data frame, it will be expressed in 24 bits. ";
CM_ BO_ 2565865562 "Electronic Retarder Controller 1 ";
CM_ SG_ 2565865562 RetarderTorqueMode "SPN:900
State signal which indicates which retarder torque mode is currently generating, limiting, or controlling the torque. ";
CM_ SG_ 2565865562 ActualRetarderPercentTorque "SPN:520
Actual braking torque of the retarder as a percent of retarder configuration reference torque SPN 556.
Note:  Refer to section 5.2.1.";
CM_ SG_ 2565865562 IntendedRetarderPercentTorque "SPN:1085
Braking torque of retarder that the retarder is currently trying to achieve.  This value takes into account all static limitations,";
CM_ SG_ 2565865562 ActMaxAvailRetarderPercentTorque "SPN:1717
This is the maximum amount of torque that the retarder can immediately deliver. ";
BA_DEF_ BO_  "Bus" STRING ;
BA_DEF_ BO_  "GenMsgCycleTime" INT 0 3600000;
BA_DEF_ BO_  "GenMsgDbName" STRING ;
BA_DEF_ BO_  "GenMsgDelayTime" INT 0 1000;
BA_DEF_ BO_  "GenMsgDescription" STRING ;
BA_DEF_ BO_  "GenMsgILSupport" ENUM  "No","Yes";
BA_DEF_ BO_  "GenMsgRequestable" INT 0 1;
BA_DEF_ BO_  "GenMsgSendType" ENUM  "NoMsgSendType","Cyclic","CyclicOnChange","OnWrite","cyclic","noMsgSendType","Triggered";
BA_DEF_ BO_  "J1939PgAppearanceOnBus" ENUM  "Default","CAN_Extended","CANFD_Extended";
BA_DEF_ BO_  "MsgType" ENUM  "Application","NM ","NMH","TP2.0","ISO-TP ","BAP","EID","KS";
BA_DEF_ BO_  "VFrameFormat" ENUM  "StandardCAN","ExtendedCAN","reserved","J1939PG";
BA_DEF_ SG_  "GenSigDbName" STRING ;
BA_DEF_ SG_  "GenSigDescription" STRING ;
BA_DEF_ SG_  "GenSigEVName" STRING ;
BA_DEF_ SG_  "GenSigILSupport" ENUM  "No","Yes";
BA_DEF_ SG_  "GenSigSendType" ENUM  "Cyclic","OnWrite","reserved","OnChange","reserved","reserved","reserved","NoSigSendType";
BA_DEF_ SG_  "GenSigStartValue" INT 0 10000;
BA_DEF_ SG_  "SPN" INT 0 1000000;
BA_DEF_ SG_  "SigType" ENUM  "Default","Range","RangeSigned","ASCII","Discrete","Control","ReferencePGN","DTC","StringDelimiter","StringLength","StringLengthControl","MessageCounter","MessageChecksum";
BA_DEF_ BU_  "ILUsed" ENUM  "No","Yes";
BA_DEF_ BU_  "J1939MultiPgBroadcastType" STRING ;
BA_DEF_ BU_  "NmStationAddress" INT 0 255;
BA_DEF_  "BusType" STRING ;
BA_DEF_  "DBName" STRING ;
BA_DEF_  "ProtocolType" STRING ;
BA_DEF_ SG_  "SystemSignalLongSymbol" STRING ;
BA_DEF_DEF_  "Bus" "HCAN";
BA_DEF_DEF_  "GenMsgCycleTime" 0;
BA_DEF_DEF_  "GenMsgDbName" "";
BA_DEF_DEF_  "GenMsgDelayTime" 0;
BA_DEF_DEF_  "GenMsgDescription" "";
BA_DEF_DEF_  "GenMsgILSupport" "Yes";
BA_DEF_DEF_  "GenMsgRequestable" 1;
BA_DEF_DEF_  "GenMsgSendType" "";
BA_DEF_DEF_  "J1939PgAppearanceOnBus" "Default";
BA_DEF_DEF_  "MsgType" "Application";
BA_DEF_DEF_  "VFrameFormat" "J1939PG";
BA_DEF_DEF_  "GenSigDbName" "";
BA_DEF_DEF_  "GenSigDescription" "";
BA_DEF_DEF_  "GenSigEVName" "Env@Nodename_@Signame";
BA_DEF_DEF_  "GenSigILSupport" "Yes";
BA_DEF_DEF_  "GenSigSendType" "NoSigSendType";
BA_DEF_DEF_  "GenSigStartValue" 0;
BA_DEF_DEF_  "SPN" 0;
BA_DEF_DEF_  "SigType" "Default";
BA_DEF_DEF_  "ILUsed" "Yes";
BA_DEF_DEF_  "J1939MultiPgBroadcastType" "FEFF";
BA_DEF_DEF_  "NmStationAddress" 254;
BA_DEF_DEF_  "BusType" "CAN";
BA_DEF_DEF_  "DBName" "HCAN_IM38_10_0_64";
BA_DEF_DEF_  "ProtocolType" "J1939";
BA_DEF_DEF_  "SystemSignalLongSymbol" "";
BA_ "DBName" "HCAN_IM40_12_0_71";
BA_ "NmStationAddress" BU_ CabHeater_44 68;
BA_ "NmStationAddress" BU_ EAC_94 148;
BA_ "NmStationAddress" BU_ DCDC_1A 26;
BA_ "NmStationAddress" BU_ HVJB_1E 30;
BA_ "NmStationAddress" BU_ PPC_HV_5B 91;
BA_ "NmStationAddress" BU_ PPC_00 0;
BA_ "NmStationAddress" BU_ PPC_EngineBrake_29 41;
BA_ "NmStationAddress" BU_ VECU_27 39;
BA_ "NmStationAddress" BU_ SAC_30 48;
BA_ "NmStationAddress" BU_ DTCO_EE 238;
BA_ "NmStationAddress" BU_ eDS_5A 90;
BA_ "NmStationAddress" BU_ EBS3_0B 11;
BA_ "NmStationAddress" BU_ AEBS_A0 160;
BA_ "NmStationAddress" BU_ BMS_F4 244;
BA_ "NmStationAddress" BU_ Gearbox_03 3;
BA_ "NmStationAddress" BU_ DD_17 23;
BA_ "NmStationAddress" BU_ SERVICE_TOOL_F9 249;
BA_ "NmStationAddress" BU_ DANA_5F 95;
BA_ "GenMsgCycleTime" BO_ 2566901851 1000;
BA_ "GenMsgCycleTime" BO_ 2566899449 10;
BA_ "GenMsgCycleTime" BO_ 2633727071 100;
BA_ "GenMsgDelayTime" BO_ 2633727071 20;
BA_ "GenMsgRequestable" BO_ 2633727071 0;
BA_ "GenMsgSendType" BO_ 2633727071 1;
BA_ "GenMsgSendType" BO_ 2565534720 0;
BA_ "GenMsgCycleTime" BO_ 2566866580 250;
BA_ "GenMsgSendType" BO_ 2566866580 0;
BA_ "GenMsgCycleTime" BO_ 2633785076 5000;
BA_ "GenMsgSendType" BO_ 2633785076 1;
BA_ "GenMsgCycleTime" BO_ 2365484270 50;
BA_ "GenMsgSendType" BO_ 2365484270 0;
BA_ "GenMsgSendType" BO_ 2565537626 0;
BA_ "GenMsgCycleTime" BO_ 2566846554 1000;
BA_ "GenMsgDelayTime" BO_ 2566846554 63;
BA_ "GenMsgRequestable" BO_ 2566846554 0;
BA_ "GenMsgSendType" BO_ 2566846554 1;
BA_ "GenMsgCycleTime" BO_ 2566615642 1000;
BA_ "GenMsgDelayTime" BO_ 2566615642 104;
BA_ "GenMsgRequestable" BO_ 2566615642 0;
BA_ "GenMsgSendType" BO_ 2566615642 1;
BA_ "GenMsgCycleTime" BO_ 2566615386 1000;
BA_ "GenMsgDelayTime" BO_ 2566615386 77;
BA_ "GenMsgRequestable" BO_ 2566615386 0;
BA_ "GenMsgSendType" BO_ 2566615386 1;
BA_ "GenMsgCycleTime" BO_ 2348820747 50;
BA_ "GenMsgDelayTime" BO_ 2348820747 11;
BA_ "GenMsgRequestable" BO_ 2348820747 0;
BA_ "GenMsgSendType" BO_ 2348820747 1;
BA_ "GenMsgCycleTime" BO_ 2565865739 100;
BA_ "GenMsgDelayTime" BO_ 2565865739 50;
BA_ "GenMsgRequestable" BO_ 2565865739 0;
BA_ "GenMsgSendType" BO_ 2565865739 1;
BA_ "GenMsgCycleTime" BO_ 2566900510 1000;
BA_ "GenMsgDelayTime" BO_ 2566900510 88;
BA_ "GenMsgRequestable" BO_ 2566900510 0;
BA_ "GenMsgSendType" BO_ 2566900510 1;
BA_ "GenMsgCycleTime" BO_ 2566831883 20;
BA_ "GenMsgDelayTime" BO_ 2566831883 2;
BA_ "GenMsgRequestable" BO_ 2566831883 0;
BA_ "GenMsgSendType" BO_ 2566831883 1;
BA_ "GenMsgCycleTime" BO_ 2566860803 50;
BA_ "GenMsgDelayTime" BO_ 2566860803 3;
BA_ "GenMsgRequestable" BO_ 2566860803 0;
BA_ "GenMsgSendType" BO_ 2566860803 1;
BA_ "GenMsgRequestable" BO_ 2566840835 0;
BA_ "GenMsgSendType" BO_ 2566840835 3;
BA_ "GenMsgCycleTime" BO_ 2364539395 10;
BA_ "GenMsgDelayTime" BO_ 2364539395 2;
BA_ "GenMsgRequestable" BO_ 2364539395 0;
BA_ "GenMsgSendType" BO_ 2364539395 1;
BA_ "GenMsgCycleTime" BO_ 2566801923 100;
BA_ "GenMsgDelayTime" BO_ 2566801923 34;
BA_ "GenMsgRequestable" BO_ 2566801923 0;
BA_ "GenMsgSendType" BO_ 2566801923 1;
BA_ "GenMsgCycleTime" BO_ 2364539648 50;
BA_ "GenMsgDelayTime" BO_ 2364539648 25;
BA_ "GenMsgRequestable" BO_ 2364539648 0;
BA_ "GenMsgSendType" BO_ 2364539648 1;
BA_ "GenMsgCycleTime" BO_ 2364606708 100;
BA_ "GenMsgDelayTime" BO_ 2364606708 16;
BA_ "GenMsgRequestable" BO_ 2364606708 0;
BA_ "GenMsgSendType" BO_ 2364606708 1;
BA_ "GenMsgCycleTime" BO_ 2364552948 100;
BA_ "GenMsgDelayTime" BO_ 2364552948 22;
BA_ "GenMsgRequestable" BO_ 2364552948 0;
BA_ "GenMsgSendType" BO_ 2364552948 1;
BA_ "GenMsgCycleTime" BO_ 2565866755 100;
BA_ "GenMsgDelayTime" BO_ 2565866755 37;
BA_ "GenMsgRequestable" BO_ 2565866755 0;
BA_ "GenMsgSendType" BO_ 2565866755 1;
BA_ "GenMsgCycleTime" BO_ 2583630324 5000;
BA_ "GenMsgDelayTime" BO_ 2583630324 50;
BA_ "GenMsgRequestable" BO_ 2583630324 0;
BA_ "GenMsgSendType" BO_ 2583630324 1;
BA_ "GenMsgCycleTime" BO_ 2348810251 20;
BA_ "GenMsgDelayTime" BO_ 2348810251 4;
BA_ "GenMsgRequestable" BO_ 2348810251 0;
BA_ "GenMsgSendType" BO_ 2348810251 1;
BA_ "GenMsgCycleTime" BO_ 2348810400 10;
BA_ "GenMsgRequestable" BO_ 2348810400 0;
BA_ "GenMsgSendType" BO_ 2348810400 1;
BA_ "GenMsgCycleTime" BO_ 2566698843 1000;
BA_ "GenMsgDbName" BO_ 2566698843 "HSS2";
BA_ "GenMsgDelayTime" BO_ 2566698843 24;
BA_ "GenMsgDescription" BO_ 2566698843 "Hybrid System Status 2 : Status information of a hybrid system.";
BA_ "GenMsgRequestable" BO_ 2566698843 0;
BA_ "GenMsgSendType" BO_ 2566698843 0;
BA_ "GenMsgCycleTime" BO_ 2566701659 1000;
BA_ "GenMsgDbName" BO_ 2566701659 "HSS1";
BA_ "GenMsgDelayTime" BO_ 2566701659 31;
BA_ "GenMsgDescription" BO_ 2566701659 "Hybrid System Status 1 : Status information of a hybrid system.";
BA_ "GenMsgRequestable" BO_ 2566701659 0;
BA_ "GenMsgSendType" BO_ 2566701659 3;
BA_ "GenMsgCycleTime" BO_ 2566865556 250;
BA_ "GenMsgDbName" BO_ 2566865556 "EAC_02";
BA_ "GenMsgDelayTime" BO_ 2566865556 11;
BA_ "GenMsgDescription" BO_ 2566865556 "PropB_EAC_02 : Electronic Air Compressor Status";
BA_ "GenMsgRequestable" BO_ 2566865556 0;
BA_ "GenMsgSendType" BO_ 2566865556 0;
BA_ "GenMsgCycleTime" BO_ 2566844711 100;
BA_ "GenMsgDelayTime" BO_ 2566844711 27;
BA_ "GenMsgRequestable" BO_ 2566844711 0;
BA_ "GenMsgSendType" BO_ 2566844711 2;
BA_ "GenMsgCycleTime" BO_ 2566857255 50;
BA_ "GenMsgDelayTime" BO_ 2566857255 19;
BA_ "GenMsgRequestable" BO_ 2566857255 0;
BA_ "GenMsgSendType" BO_ 2566857255 1;
BA_ "GenMsgCycleTime" BO_ 2351323687 10;
BA_ "GenMsgDelayTime" BO_ 2351323687 3;
BA_ "GenMsgRequestable" BO_ 2351323687 0;
BA_ "GenMsgSendType" BO_ 2351323687 1;
BA_ "GenMsgCycleTime" BO_ 2348833280 10;
BA_ "GenMsgDelayTime" BO_ 2348833280 1;
BA_ "GenMsgRequestable" BO_ 2348833280 0;
BA_ "GenMsgSendType" BO_ 2348833280 1;
BA_ "GenMsgCycleTime" BO_ 2348833321 50;
BA_ "GenMsgDelayTime" BO_ 2348833321 1;
BA_ "GenMsgRequestable" BO_ 2348833321 0;
BA_ "GenMsgSendType" BO_ 2348833321 1;
BA_ "GenMsgCycleTime" BO_ 2350642267 20;
BA_ "GenMsgRequestable" BO_ 2350642267 0;
BA_ "GenMsgSendType" BO_ 2350642267 1;
BA_ "GenMsgCycleTime" BO_ 2364539738 50;
BA_ "GenMsgDelayTime" BO_ 2364539738 11;
BA_ "GenMsgRequestable" BO_ 2364539738 0;
BA_ "GenMsgSendType" BO_ 2364539738 1;
BA_ "GenMsgCycleTime" BO_ 2364539994 10;
BA_ "GenMsgDelayTime" BO_ 2364539994 1;
BA_ "GenMsgRequestable" BO_ 2364539994 0;
BA_ "GenMsgSendType" BO_ 2364539994 1;
BA_ "GenMsgCycleTime" BO_ 2364575988 20;
BA_ "GenMsgDelayTime" BO_ 2364575988 9;
BA_ "GenMsgRequestable" BO_ 2364575988 0;
BA_ "GenMsgSendType" BO_ 2364575988 1;
BA_ "GenMsgCycleTime" BO_ 2364576244 20;
BA_ "GenMsgDelayTime" BO_ 2364576244 4;
BA_ "GenMsgRequestable" BO_ 2364576244 0;
BA_ "GenMsgSendType" BO_ 2364576244 1;
BA_ "GenMsgCycleTime" BO_ 2364576500 20;
BA_ "GenMsgDelayTime" BO_ 2364576500 9;
BA_ "GenMsgRequestable" BO_ 2364576500 0;
BA_ "GenMsgSendType" BO_ 2364576500 1;
BA_ "GenMsgCycleTime" BO_ 2364577012 20;
BA_ "GenMsgDelayTime" BO_ 2364577012 5;
BA_ "GenMsgRequestable" BO_ 2364577012 0;
BA_ "GenMsgSendType" BO_ 2364577012 1;
BA_ "GenMsgCycleTime" BO_ 2364577524 100;
BA_ "GenMsgDelayTime" BO_ 2364577524 7;
BA_ "GenMsgRequestable" BO_ 2364577524 0;
BA_ "GenMsgSendType" BO_ 2364577524 2;
BA_ "GenMsgCycleTime" BO_ 2364580084 100;
BA_ "GenMsgDelayTime" BO_ 2364580084 46;
BA_ "GenMsgRequestable" BO_ 2364580084 0;
BA_ "GenMsgSendType" BO_ 2364580084 1;
BA_ "GenMsgCycleTime" BO_ 2364606964 100;
BA_ "GenMsgDelayTime" BO_ 2364606964 19;
BA_ "GenMsgRequestable" BO_ 2364606964 0;
BA_ "GenMsgSendType" BO_ 2364606964 1;
BA_ "GenMsgCycleTime" BO_ 2364637530 100;
BA_ "GenMsgDelayTime" BO_ 2364637530 46;
BA_ "GenMsgRequestable" BO_ 2364637530 0;
BA_ "GenMsgSendType" BO_ 2364637530 1;
BA_ "GenMsgCycleTime" BO_ 2566841178 5000;
BA_ "GenMsgSendType" BO_ 2566841178 0;
BA_ "GenMsgCycleTime" BO_ 2365289306 1000;
BA_ "GenMsgDelayTime" BO_ 2365289306 109;
BA_ "GenMsgRequestable" BO_ 2365289306 0;
BA_ "GenMsgSendType" BO_ 2365289306 1;
BA_ "GenMsgCycleTime" BO_ 2365289562 10;
BA_ "GenMsgDelayTime" BO_ 2365289562 4;
BA_ "GenMsgRequestable" BO_ 2365289562 0;
BA_ "GenMsgSendType" BO_ 2365289562 1;
BA_ "GenMsgCycleTime" BO_ 2556320347 1000;
BA_ "GenMsgDelayTime" BO_ 2556320347 81;
BA_ "GenMsgRequestable" BO_ 2556320347 0;
BA_ "GenMsgSendType" BO_ 2556320347 1;
BA_ "GenMsgCycleTime" BO_ 2564882267 1000;
BA_ "GenMsgDelayTime" BO_ 2564882267 31;
BA_ "GenMsgRequestable" BO_ 2564882267 0;
BA_ "GenMsgSendType" BO_ 2564882267 2;
BA_ "GenMsgRequestable" BO_ 2565537627 0;
BA_ "GenMsgSendType" BO_ 2565537627 3;
BA_ "GenMsgCycleTime" BO_ 2565865562 100;
BA_ "GenMsgDelayTime" BO_ 2565865562 34;
BA_ "GenMsgRequestable" BO_ 2565865562 0;
BA_ "GenMsgSendType" BO_ 2565865562 1;
BA_ "SPN" SG_ 3221225472 HVESChargeConsent 10148;
BA_ "SigType" SG_ 3221225472 HVESChargeConsent 5;
BA_ "SPN" SG_ 3221225472 PropulsionModeReqDist 9707;
BA_ "SigType" SG_ 3221225472 PropulsionModeReqDist 1;
BA_ "SPN" SG_ 3221225472 PropulsionModeReqMaxSpd 9706;
BA_ "SigType" SG_ 3221225472 PropulsionModeReqMaxSpd 1;
BA_ "SPN" SG_ 3221225472 StoredESSetPointReq 7892;
BA_ "SigType" SG_ 3221225472 StoredESSetPointReq 1;
BA_ "SPN" SG_ 3221225472 StoredESCharge_DischargeRateReq 7891;
BA_ "SigType" SG_ 3221225472 StoredESCharge_DischargeRateReq 1;
BA_ "SPN" SG_ 3221225472 ExtlESConnectionDemand 7890;
BA_ "SPN" SG_ 3221225472 PropulsionModeReq 7889;
BA_ "SPN" SG_ 3221225472 OpVehModeReq 7888;
BA_ "SPN" SG_ 3221225472 ShutdownCmd 7560;
BA_ "SigType" SG_ 3221225472 ShutdownCmd 5;
BA_ "SPN" SG_ 3221225472 PropulsionDisableReq 7558;
BA_ "SigType" SG_ 3221225472 PropulsionDisableReq 5;
BA_ "SPN" SG_ 3221225472 HybrdSystmRgnrtvBrakingDisableRq 7559;
BA_ "SigType" SG_ 3221225472 HybrdSystmRgnrtvBrakingDisableRq 5;
BA_ "SPN" SG_ 3221225472 HybridSystemProtectionOverrideRq 7557;
BA_ "SigType" SG_ 3221225472 HybridSystemProtectionOverrideRq 5;
BA_ "SPN" SG_ 3221225472 HVESSThermalMnmgtMaintenanceSw 20877;
BA_ "SigType" SG_ 3221225472 HVESSThermalMnmgtMaintenanceSw 4;
BA_ "SPN" SG_ 3221225472 PropulsionMotorCoolantFillSw 8476;
BA_ "SigType" SG_ 3221225472 PropulsionMotorCoolantFillSw 4;
BA_ "SPN" SG_ 3221225472 PwrECoolantFillSw 8475;
BA_ "SigType" SG_ 3221225472 PwrECoolantFillSw 4;
BA_ "SPN" SG_ 3221225472 ShutdownSw 7555;
BA_ "SigType" SG_ 3221225472 ShutdownSw 4;
BA_ "SPN" SG_ 3221225472 PropulsionDisableSw 7554;
BA_ "SigType" SG_ 3221225472 PropulsionDisableSw 4;
BA_ "SPN" SG_ 3221225472 HybrdSystmCstngRgnrtvBrkngLvlSlc 7556;
BA_ "SigType" SG_ 3221225472 HybrdSystmCstngRgnrtvBrkngLvlSlc 1;
BA_ "SPN" SG_ 3221225472 HybrdSystmBrkPdlRgnrtvBrkngDsblS 7553;
BA_ "SigType" SG_ 3221225472 HybrdSystmBrkPdlRgnrtvBrkngDsblS 4;
BA_ "SPN" SG_ 3221225472 HybrdSystmRgnrtvBrkngDsbleSwitch 7552;
BA_ "SigType" SG_ 3221225472 HybrdSystmRgnrtvBrkngDsbleSwitch 4;
BA_ "SPN" SG_ 3221225472 HybrdSystmPwrElctrncsClntLvlSwtc 7550;
BA_ "SigType" SG_ 3221225472 HybrdSystmPwrElctrncsClntLvlSwtc 4;
BA_ "SPN" SG_ 3221225472 HybrdSystmPrplsnClantLevelSwitch 7549;
BA_ "SigType" SG_ 3221225472 HybrdSystmPrplsnClantLevelSwitch 4;
BA_ "SPN" SG_ 3221225472 HybrdSystmPrtctionOverrideSwitch 7548;
BA_ "SigType" SG_ 3221225472 HybrdSystmPrtctionOverrideSwitch 4;
BA_ "SPN" SG_ 2633727071 ControlBitVector 8623;
BA_ "SPN" SG_ 2633785076 HVESSTotalEnergyOut 13366;
BA_ "SigType" SG_ 2633785076 HVESSTotalEnergyOut 1;
BA_ "SPN" SG_ 2633785076 HVESSTotalEnergyInput 13365;
BA_ "SigType" SG_ 2633785076 HVESSTotalEnergyInput 1;
BA_ "SPN" SG_ 2633785076 HVESSTotalAccumulatedCharge 8212;
BA_ "SigType" SG_ 2633785076 HVESSTotalAccumulatedCharge 1;
BA_ "SPN" SG_ 2633785076 HVESSTotalEnergyThroughput 8211;
BA_ "SigType" SG_ 2633785076 HVESSTotalEnergyThroughput 1;
BA_ "SPN" SG_ 2633785076 HVESSContactorOpenUnderLoadCount 8122;
BA_ "SigType" SG_ 2633785076 HVESSContactorOpenUnderLoadCount 1;
BA_ "SPN" SG_ 2633785076 HVESSStateOfHealth 8121;
BA_ "SigType" SG_ 2633785076 HVESSStateOfHealth 1;
BA_ "SPN" SG_ 2365484270 TachographVehicleSpeed 1624;
BA_ "SigType" SG_ 2365484270 TachographVehicleSpeed 1;
BA_ "SPN" SG_ 2365484270 TachographOutputShaftSpeed 1623;
BA_ "SigType" SG_ 2365484270 TachographOutputShaftSpeed 1;
BA_ "SPN" SG_ 2365484270 DirectionIndicator 1619;
BA_ "SigType" SG_ 2365484270 DirectionIndicator 4;
BA_ "SPN" SG_ 2365484270 TachographPerformance 1620;
BA_ "SigType" SG_ 2365484270 TachographPerformance 5;
BA_ "SPN" SG_ 2365484270 HandlingInformation 1621;
BA_ "SigType" SG_ 2365484270 HandlingInformation 5;
BA_ "SPN" SG_ 2365484270 SystemEvent 1622;
BA_ "SigType" SG_ 2365484270 SystemEvent 5;
BA_ "SPN" SG_ 2365484270 DriverCardDriver2 1616;
BA_ "SigType" SG_ 2365484270 DriverCardDriver2 4;
BA_ "SPN" SG_ 2365484270 Driver2TimeRelatedStates 1618;
BA_ "SPN" SG_ 2365484270 VehicleOverspeed 1614;
BA_ "SigType" SG_ 2365484270 VehicleOverspeed 4;
BA_ "SPN" SG_ 2365484270 DriverCardDriver1 1615;
BA_ "SigType" SG_ 2365484270 DriverCardDriver1 4;
BA_ "SPN" SG_ 2365484270 Driver1TimeRelatedStates 1617;
BA_ "SPN" SG_ 2365484270 VehicleMotion 1611;
BA_ "SigType" SG_ 2365484270 VehicleMotion 4;
BA_ "SPN" SG_ 2365484270 Driver2WorkingState 1613;
BA_ "SPN" SG_ 2365484270 Driver1WorkingState 1612;
BA_ "GenSigStartValue" SG_ 2566846554 TransmissionOilTemperature1 8736;
BA_ "SPN" SG_ 2566846554 TransmissionOilTemperature1 177;
BA_ "SigType" SG_ 2566846554 TransmissionOilTemperature1 1;
BA_ "GenSigStartValue" SG_ 2566615642 MotorGenerator1InverterTemp1 40;
BA_ "SPN" SG_ 2566615642 MotorGenerator1InverterTemp1 10216;
BA_ "GenSigStartValue" SG_ 2566615642 MotorGenerator1InverterTemp2 40;
BA_ "SPN" SG_ 2566615642 MotorGenerator1InverterTemp2 10217;
BA_ "GenSigStartValue" SG_ 2566615386 MotorGenerator1Temperature1 40;
BA_ "SPN" SG_ 2566615386 MotorGenerator1Temperature1 9059;
BA_ "GenSigStartValue" SG_ 2566615386 MotorGenerator1Temperature2 40;
BA_ "SPN" SG_ 2566615386 MotorGenerator1Temperature2 10220;
BA_ "SPN" SG_ 2348820747 EngineOverrideControlMode 695;
BA_ "SPN" SG_ 2348820747 OverrideControlModePriority 897;
BA_ "GenSigStartValue" SG_ 2348820747 EngineRequestedTorqueTorqueLimit 125;
BA_ "SPN" SG_ 2348820747 EngineRequestedTorqueTorqueLimit 518;
BA_ "SigType" SG_ 2348820747 EngineRequestedTorqueTorqueLimit 1;
BA_ "SPN" SG_ 2348820747 TSC1TransmissionRate 3349;
BA_ "SPN" SG_ 2348820747 TSC1ControlPurpose 3350;
BA_ "SPN" SG_ 2348820747 EngineRequestedTorqueFractional 4191;
BA_ "SigType" SG_ 2348820747 EngineRequestedTorqueFractional 1;
BA_ "SPN" SG_ 2348820747 TSC1AXR_Counter 4206;
BA_ "SPN" SG_ 2348820747 TSC1AXR_Checksum 4207;
BA_ "SPN" SG_ 2565865739 ASREngineControlActive 561;
BA_ "SPN" SG_ 2565865739 ASRBrakeControlActive 562;
BA_ "SPN" SG_ 2565865739 AntiLockBrakingABSActive 563;
BA_ "SPN" SG_ 2565865739 EBSBrakeSwitch 1121;
BA_ "SPN" SG_ 2565865739 BrakePedalPosition 521;
BA_ "SigType" SG_ 2565865739 BrakePedalPosition 1;
BA_ "SPN" SG_ 2565865739 ASROffroadSwitch 576;
BA_ "SPN" SG_ 2565865739 ASRHillHolderSwitch 577;
BA_ "GenSigStartValue" SG_ 2566900510 HVJBInternalTemperature1 40;
BA_ "SPN" SG_ 2566900510 HVJBInternalTemperature1 519961;
BA_ "SigType" SG_ 2566900510 HVJBInternalTemperature1 1;
BA_ "GenSigStartValue" SG_ 2566900510 HVJBInternalTemperature2 40;
BA_ "SPN" SG_ 2566900510 HVJBInternalTemperature2 519962;
BA_ "SigType" SG_ 2566900510 HVJBInternalTemperature2 1;
BA_ "GenSigStartValue" SG_ 2566900510 HVJBInternalTemperature3 40;
BA_ "SPN" SG_ 2566900510 HVJBInternalTemperature3 519963;
BA_ "SigType" SG_ 2566900510 HVJBInternalTemperature3 1;
BA_ "GenSigStartValue" SG_ 2566900510 HVJBInternalTemperature4 40;
BA_ "SPN" SG_ 2566900510 HVJBInternalTemperature4 519964;
BA_ "SigType" SG_ 2566900510 HVJBInternalTemperature4 1;
BA_ "GenSigStartValue" SG_ 2566900510 HVJBInternalTemperature5 40;
BA_ "SPN" SG_ 2566900510 HVJBInternalTemperature5 519965;
BA_ "SigType" SG_ 2566900510 HVJBInternalTemperature5 1;
BA_ "GenSigStartValue" SG_ 2566900510 HVJBInternalTemperature6 40;
BA_ "SPN" SG_ 2566900510 HVJBInternalTemperature6 519966;
BA_ "SigType" SG_ 2566900510 HVJBInternalTemperature6 1;
BA_ "GenSigStartValue" SG_ 2566900510 HVJBInternalTemperature7 40;
BA_ "SPN" SG_ 2566900510 HVJBInternalTemperature7 519967;
BA_ "SigType" SG_ 2566900510 HVJBInternalTemperature7 1;
BA_ "GenSigStartValue" SG_ 2566900510 HVJBInternalTemperature8 40;
BA_ "SPN" SG_ 2566900510 HVJBInternalTemperature8 519968;
BA_ "SigType" SG_ 2566900510 HVJBInternalTemperature8 1;
BA_ "SPN" SG_ 2566831883 FrontAxleSpeed 904;
BA_ "SigType" SG_ 2566831883 FrontAxleSpeed 1;
BA_ "GenSigStartValue" SG_ 2566831883 RelativeSpeedFrontAxleLeftWheel 125;
BA_ "SPN" SG_ 2566831883 RelativeSpeedFrontAxleLeftWheel 905;
BA_ "SigType" SG_ 2566831883 RelativeSpeedFrontAxleLeftWheel 1;
BA_ "GenSigStartValue" SG_ 2566831883 RelativeSpeedFrontAxleRightWheel 125;
BA_ "SPN" SG_ 2566831883 RelativeSpeedFrontAxleRightWheel 906;
BA_ "SigType" SG_ 2566831883 RelativeSpeedFrontAxleRightWheel 1;
BA_ "GenSigStartValue" SG_ 2566831883 RelativeSpeedRearAxle1LeftWheel 125;
BA_ "SPN" SG_ 2566831883 RelativeSpeedRearAxle1LeftWheel 907;
BA_ "SigType" SG_ 2566831883 RelativeSpeedRearAxle1LeftWheel 1;
BA_ "GenSigStartValue" SG_ 2566831883 RelativeSpeedRearAxle1RightWheel 125;
BA_ "SPN" SG_ 2566831883 RelativeSpeedRearAxle1RightWheel 908;
BA_ "SigType" SG_ 2566831883 RelativeSpeedRearAxle1RightWheel 1;
BA_ "GenSigStartValue" SG_ 2566831883 RelativeSpeedRearAxle2LeftWheel 125;
BA_ "SPN" SG_ 2566831883 RelativeSpeedRearAxle2LeftWheel 909;
BA_ "SigType" SG_ 2566831883 RelativeSpeedRearAxle2LeftWheel 1;
BA_ "GenSigStartValue" SG_ 2566831883 RelativeSpeedRearAxle2RightWheel 125;
BA_ "SPN" SG_ 2566831883 RelativeSpeedRearAxle2RightWheel 910;
BA_ "SigType" SG_ 2566831883 RelativeSpeedRearAxle2RightWheel 1;
BA_ "SPN" SG_ 2566860803 LeverToNeutral 522911;
BA_ "SPN" SG_ 2566860803 Leverposunequaltodrivepos 522912;
BA_ "SPN" SG_ 2566860803 ManualShiftingFleetVersion 523706;
BA_ "SPN" SG_ 2566860803 AMIndication 523631;
BA_ "SPN" SG_ 2566860803 ActivePTO1 522914;
BA_ "SPN" SG_ 2566860803 ActivePTO2 522915;
BA_ "SPN" SG_ 2566860803 Directionindicator 1619;
BA_ "SPN" SG_ 2566860803 ECOrollEventWhenDisabled 524138;
BA_ "SPN" SG_ 2566840835 NumberofReverseGearRatios 958;
BA_ "SPN" SG_ 2566840835 NumberofForwardGearRatios 957;
BA_ "SPN" SG_ 2566840835 TransmissionGearRatio 581;
BA_ "SigType" SG_ 2566840835 TransmissionGearRatio 1;
BA_ "SPN" SG_ 2364539395 TransmissionDrivelineEngaged 560;
BA_ "SPN" SG_ 2364539395 TransTrqConverterLockupEngaged 573;
BA_ "SPN" SG_ 2364539395 TransmissionShiftInProcess 574;
BA_ "SPN" SG_ 2364539395 TransmissionOutputShaftSpeed 191;
BA_ "SigType" SG_ 2364539395 TransmissionOutputShaftSpeed 1;
BA_ "SPN" SG_ 2364539395 PercentClutchSlip 522;
BA_ "SigType" SG_ 2364539395 PercentClutchSlip 1;
BA_ "SPN" SG_ 2364539395 ProgressiveShiftDisable 607;
BA_ "SPN" SG_ 2364539395 TransmissionInputShaftSpeed 161;
BA_ "SigType" SG_ 2364539395 TransmissionInputShaftSpeed 1;
BA_ "SPN" SG_ 2566801923 TransmissionReadyforBrakeRelease 3086;
BA_ "SPN" SG_ 2566801923 TransmissionEngineCrankEnable 2900;
BA_ "SPN" SG_ 2566801923 TransmissionMode2Indicator 2537;
BA_ "SPN" SG_ 2566801923 TransmissionMode1Indicator 2536;
BA_ "SPN" SG_ 2566801923 TransmissionMode6Indicator 4251;
BA_ "SPN" SG_ 2566801923 TransmissionMode7Indicator 4252;
BA_ "SPN" SG_ 2566801923 TransmissionMode8Indicator 4253;
BA_ "SPN" SG_ 2364539648 AcceleratorPedal1LowIdleSwitch 558;
BA_ "SPN" SG_ 2364539648 AcceleratorPedalKickdownSwitch 559;
BA_ "SPN" SG_ 2364539648 RoadSpeedLimitStatus 1437;
BA_ "SPN" SG_ 2364539648 AcceleratorPedalPosition1 91;
BA_ "SigType" SG_ 2364539648 AcceleratorPedalPosition1 1;
BA_ "SPN" SG_ 2364539648 EnginePercentLoadAtCurrentSpeed 92;
BA_ "SigType" SG_ 2364539648 EnginePercentLoadAtCurrentSpeed 1;
BA_ "SPN" SG_ 2364539648 RemoteAcceleratorPedalPosition 974;
BA_ "SigType" SG_ 2364539648 RemoteAcceleratorPedalPosition 1;
BA_ "SPN" SG_ 2364539648 VehicleAccelRateLimitStatus 2979;
BA_ "SPN" SG_ 2364539648 DPFThermalManagementActive 5399;
BA_ "SPN" SG_ 2364539648 SCRThermalManagementActive 5400;
BA_ "SPN" SG_ 2364539648 ActMaximumAvailEngPercentTorque 3357;
BA_ "SigType" SG_ 2364539648 ActMaximumAvailEngPercentTorque 1;
BA_ "GenSigStartValue" SG_ 2364539648 EstimatedPumpingPercentTorque 125;
BA_ "SPN" SG_ 2364539648 EstimatedPumpingPercentTorque 5398;
BA_ "SigType" SG_ 2364539648 EstimatedPumpingPercentTorque 1;
BA_ "SPN" SG_ 2364606708 HVESSModule1OperationalStatus 8214;
BA_ "SPN" SG_ 2364606708 HVESSModule2OperationalStatus 8215;
BA_ "SPN" SG_ 2364606708 HVESSModule3OperationalStatus 8216;
BA_ "SPN" SG_ 2364606708 HVESSModule4OperationalStatus 8217;
BA_ "SPN" SG_ 2364606708 HVESSModule5OperationalStatus 8218;
BA_ "SPN" SG_ 2364606708 HVESSModule6OperationalStatus 8219;
BA_ "SPN" SG_ 2364606708 HVESSModule7OperationalStatus 8220;
BA_ "SPN" SG_ 2364606708 HVESSModule8OperationalStatus 8221;
BA_ "SPN" SG_ 2364606708 HVESSModule9OperationalStatus 8222;
BA_ "SPN" SG_ 2364552948 DischargePowlimIsBatTemperature 8104;
BA_ "SPN" SG_ 2364552948 DischargePowlimIsBatDiagConditio 8105;
BA_ "SPN" SG_ 2364552948 DischargePowlimIsBatorCellVoltag 8106;
BA_ "SPN" SG_ 2364552948 DischargePowlimIsBatteryCurrent 8107;
BA_ "SPN" SG_ 2364552948 ChargePowlimIsBatteryTemperature 8110;
BA_ "SPN" SG_ 2364552948 ChargePowlimIsBatDiagCondition 8111;
BA_ "SPN" SG_ 2364552948 ChargePowlimIsBatorCellVoltage 8112;
BA_ "SPN" SG_ 2364552948 ChargePowlimIsBatteryCurrent 8113;
BA_ "SPN" SG_ 2364552948 ChargePowlimIsanUndefinedCause 8114;
BA_ "GenSigStartValue" SG_ 2565866755 TransmissionSelectedGear 125;
BA_ "SPN" SG_ 2565866755 TransmissionSelectedGear 524;
BA_ "SPN" SG_ 2565866755 TransmissionActualGearRatio 526;
BA_ "SigType" SG_ 2565866755 TransmissionActualGearRatio 1;
BA_ "GenSigStartValue" SG_ 2565866755 TransmissionCurrentGear 125;
BA_ "SPN" SG_ 2565866755 TransmissionCurrentGear 523;
BA_ "SPN" SG_ 2565866755 TransmissionRequestedRange 162;
BA_ "SPN" SG_ 2583630324 ChargingTimeTillFullSOCEst 520171;
BA_ "SigType" SG_ 2583630324 ChargingTimeTillFullSOCEst 1;
BA_ "SPN" SG_ 2583630324 ChargingTimeTillFullSOCRec 520172;
BA_ "SigType" SG_ 2583630324 ChargingTimeTillFullSOCRec 1;
BA_ "SPN" SG_ 2348810251 EngineOverrideControlMode 695;
BA_ "SPN" SG_ 2348810251 OverrideControlModePriority 897;
BA_ "SPN" SG_ 2348810251 EngineRequestedTorqueTorqueLimit 518;
BA_ "SigType" SG_ 2348810251 EngineRequestedTorqueTorqueLimit 1;
BA_ "SPN" SG_ 2348810251 TSC1TransmissionRate 3349;
BA_ "SPN" SG_ 2348810251 TSC1ControlPurpose 3350;
BA_ "SPN" SG_ 2348810251 EngineRequestedTorqueFractional 4191;
BA_ "SigType" SG_ 2348810251 EngineRequestedTorqueFractional 1;
BA_ "SPN" SG_ 2348810251 MessageCounter 4206;
BA_ "SPN" SG_ 2348810251 MessageChecksum 4207;
BA_ "SPN" SG_ 2348810400 EngineOverrideControlMode 695;
BA_ "SPN" SG_ 2348810400 OverrideControlModePriority 897;
BA_ "SPN" SG_ 2348810400 EngineRequestedTorqueTorqueLimit 518;
BA_ "SigType" SG_ 2348810400 EngineRequestedTorqueTorqueLimit 1;
BA_ "SPN" SG_ 2348810400 TSC1TransmissionRate 3349;
BA_ "SPN" SG_ 2348810400 TSC1ControlPurpose 3350;
BA_ "SPN" SG_ 2348810400 EngineRequestedTorqueFractional 4191;
BA_ "SigType" SG_ 2348810400 EngineRequestedTorqueFractional 1;
BA_ "SPN" SG_ 2348810400 MessageCounter 4206;
BA_ "SPN" SG_ 2348810400 MessageChecksum 4207;
BA_ "GenSigDbName" SG_ 2566698843 HybridPropulsionModeRemDist "Hybrid Propulsion Mode Remaining Distance";
BA_ "GenSigDescription" SG_ 2566698843 HybridPropulsionModeRemDist "reports a count down of the remaining distance until the mode is exited.  ";
BA_ "SPN" SG_ 2566698843 HybridPropulsionModeRemDist 9709;
BA_ "SigType" SG_ 2566698843 HybridPropulsionModeRemDist 1;
BA_ "GenSigDbName" SG_ 2566701659 StoredEnergySourceLevel "Stored Energy Source Level";
BA_ "GenSigDescription" SG_ 2566701659 StoredEnergySourceLevel "Stored Energy Source Level indicates the current operating stored HVES energy capacity available for use.This is the current percentage of the HVES useable capacity. When the state of charge is below the minimum HVES useable capacity, this parameter shal";
BA_ "SPN" SG_ 2566701659 StoredEnergySourceLevel 7895;
BA_ "SigType" SG_ 2566701659 StoredEnergySourceLevel 1;
BA_ "GenSigDbName" SG_ 2566865556 AirCompressorActualSpeed "Air Compressor Actual Speed";
BA_ "GenSigDescription" SG_ 2566865556 AirCompressorActualSpeed "Air Compressor Actual Speed";
BA_ "SPN" SG_ 2566865556 AirCompressorActualSpeed 520186;
BA_ "GenSigDbName" SG_ 2566865556 AirCompressorEnableStatus "Air Compressor Enable Status";
BA_ "GenSigDescription" SG_ 2566865556 AirCompressorEnableStatus "Air Compressor Enable Status00b = Disabled01b = Enabled10b = Error11b = Not available";
BA_ "SPN" SG_ 2566865556 AirCompressorEnableStatus 520187;
BA_ "GenSigDbName" SG_ 2566865556 AirCompressorRunStatus "Air Compressor Run Status";
BA_ "GenSigDescription" SG_ 2566865556 AirCompressorRunStatus "Air Compressor Run Status000b = Standby001b = Running010b = Busy011b = Reserved100b = HVIL Open101b = Request to run110b = Error111b = Not available";
BA_ "SPN" SG_ 2566865556 AirCompressorRunStatus 520188;
BA_ "GenSigDbName" SG_ 2566865556 AirCompressorErrorStatus "Air Compressor Error Status";
BA_ "GenSigDescription" SG_ 2566865556 AirCompressorErrorStatus "Air Compressor Error Status000b = No error001b = Temporary error010b = Severe error011b = Reserved100b = Reserved101b = Reserved110b = Error111b = Not available";
BA_ "SPN" SG_ 2566865556 AirCompressorErrorStatus 520189;
BA_ "GenSigDbName" SG_ 2566865556 AirCompressorTemperatureStatus "Air Compressor Temperature Status";
BA_ "GenSigDescription" SG_ 2566865556 AirCompressorTemperatureStatus "Air Compressor Temperature Status00b = Within operation range01b = Critical overheat10b = Error11b = Not available";
BA_ "SPN" SG_ 2566865556 AirCompressorTemperatureStatus 520190;
BA_ "GenSigDbName" SG_ 2566865556 AirCompressorOilLevelStatus "Air Compressor Oil Level Status";
BA_ "GenSigDescription" SG_ 2566865556 AirCompressorOilLevelStatus "Air Compressor Oil Level Status00b = Sufficient01b = Low10b = Error11b = Not available";
BA_ "SPN" SG_ 2566865556 AirCompressorOilLevelStatus 520191;
BA_ "SPN" SG_ 2566844711 TwoSpeedAxleSwitch 69;
BA_ "SPN" SG_ 2566844711 ParkingBrakeSwitch 70;
BA_ "SPN" SG_ 2566844711 CruiseControlPauseSwitch 1633;
BA_ "SPN" SG_ 2566844711 WheelBasedVehicleSpeed 84;
BA_ "SigType" SG_ 2566844711 WheelBasedVehicleSpeed 1;
BA_ "SPN" SG_ 2566844711 CruiseControlActive 595;
BA_ "SPN" SG_ 2566844711 CruiseControlEnableSwitch 596;
BA_ "SPN" SG_ 2566844711 BrakeSwitch 597;
BA_ "SPN" SG_ 2566844711 ClutchSwitch 598;
BA_ "SPN" SG_ 2566844711 CruiseControlSetSwitch 599;
BA_ "SPN" SG_ 2566844711 CruiseCtrlCoastDecelerateSwitch 600;
BA_ "SPN" SG_ 2566844711 CruiseControlResumeSwitch 601;
BA_ "SPN" SG_ 2566844711 CruiseControlAccelerateSwitch 602;
BA_ "SPN" SG_ 2566844711 CruiseControlSetSpeed 86;
BA_ "SigType" SG_ 2566844711 CruiseControlSetSpeed 1;
BA_ "SPN" SG_ 2566844711 PTOGovernorState 976;
BA_ "SPN" SG_ 2566844711 CruiseControlStates 527;
BA_ "GenSigStartValue" SG_ 2566857255 TransmissionRequestedGear 125;
BA_ "SPN" SG_ 2566857255 TransmissionRequestedGear 525;
BA_ "SPN" SG_ 2566857255 VECU_TC1_Counter 4206;
BA_ "SPN" SG_ 2566857255 VECU_TC1_Checksum 4207;
BA_ "SPN" SG_ 2351323687 MG1InvCtrlCRC 10157;
BA_ "SPN" SG_ 2351323687 MG1InvCtrlCount 10158;
BA_ "SPN" SG_ 2351323687 MG1InvCtrlSetPoint 10162;
BA_ "SPN" SG_ 2348833280 EngineOverrideControlMode 695;
BA_ "SPN" SG_ 2348833280 OverrideControlModePriority 897;
BA_ "GenSigStartValue" SG_ 2348833280 EngineRequestedTorqueTorqueLimit 125;
BA_ "SPN" SG_ 2348833280 EngineRequestedTorqueTorqueLimit 518;
BA_ "SigType" SG_ 2348833280 EngineRequestedTorqueTorqueLimit 1;
BA_ "SPN" SG_ 2348833280 TSC1TransmissionRate 3349;
BA_ "SPN" SG_ 2348833280 TSC1ControlPurpose 3350;
BA_ "SPN" SG_ 2348833280 EngineRequestedTorqueFractional 4191;
BA_ "SigType" SG_ 2348833280 EngineRequestedTorqueFractional 1;
BA_ "SPN" SG_ 2348833280 MessageCounter 4206;
BA_ "SPN" SG_ 2348833280 MessageChecksum 4207;
BA_ "SPN" SG_ 2348833321 EngineOverrideControlMode 695;
BA_ "SPN" SG_ 2348833321 OverrideControlModePriority 897;
BA_ "GenSigStartValue" SG_ 2348833321 EngineRequestedTorqueTorqueLimit 125;
BA_ "SPN" SG_ 2348833321 EngineRequestedTorqueTorqueLimit 518;
BA_ "SigType" SG_ 2348833321 EngineRequestedTorqueTorqueLimit 1;
BA_ "SPN" SG_ 2348833321 TSC1TransmissionRate 3349;
BA_ "SPN" SG_ 2348833321 EngineRequestedTorqueFractional 4191;
BA_ "SigType" SG_ 2348833321 EngineRequestedTorqueFractional 1;
BA_ "SPN" SG_ 2348833321 MessageCounter 4206;
BA_ "SPN" SG_ 2348833321 MessageChecksum 4207;
BA_ "SPN" SG_ 2350642267 HVESSHighVoltageBusConnectCmd 8123;
BA_ "SPN" SG_ 2350642267 HVESSPowerDownCommand 8124;
BA_ "SPN" SG_ 2350642267 HVESSHighVoltageBusPassiveIsolat 8126;
BA_ "SPN" SG_ 2350642267 HVESSControl1Counter 13027;
BA_ "SPN" SG_ 2350642267 HVESSControl1CRC 13028;
BA_ "SPN" SG_ 2364539738 ActMaximumAvailEngPercentTorque 3357;
BA_ "SigType" SG_ 2364539738 ActMaximumAvailEngPercentTorque 1;
BA_ "SPN" SG_ 2364539994 EngineTorqueMode 899;
BA_ "SPN" SG_ 2364539994 ActEnginePercentTorqueFractional 4154;
BA_ "SigType" SG_ 2364539994 ActEnginePercentTorqueFractional 1;
BA_ "GenSigStartValue" SG_ 2364539994 ActualEnginePercentTorque 125;
BA_ "SPN" SG_ 2364539994 ActualEnginePercentTorque 513;
BA_ "SigType" SG_ 2364539994 ActualEnginePercentTorque 1;
BA_ "SPN" SG_ 2364539994 EngineSpeed 190;
BA_ "SigType" SG_ 2364539994 EngineSpeed 1;
BA_ "SPN" SG_ 2364575988 HVESSAvailableDischargePower 5917;
BA_ "SigType" SG_ 2364575988 HVESSAvailableDischargePower 1;
BA_ "SPN" SG_ 2364575988 HVESSAvailableChargePower 5918;
BA_ "SigType" SG_ 2364575988 HVESSAvailableChargePower 1;
BA_ "SPN" SG_ 2364575988 HVESSVoltageLevel 5919;
BA_ "SigType" SG_ 2364575988 HVESSVoltageLevel 1;
BA_ "GenSigStartValue" SG_ 2364575988 HVESSCurrent 10000;
BA_ "SPN" SG_ 2364575988 HVESSCurrent 5920;
BA_ "SigType" SG_ 2364575988 HVESSCurrent 1;
BA_ "SPN" SG_ 2364576244 HVESSCellVoltageDifferenceStatus 5924;
BA_ "SPN" SG_ 2364576244 HVESSLowestCellVoltage 5923;
BA_ "SigType" SG_ 2364576244 HVESSLowestCellVoltage 1;
BA_ "SPN" SG_ 2364576244 HVESSHighestCellVoltage 5922;
BA_ "SigType" SG_ 2364576244 HVESSHighestCellVoltage 1;
BA_ "SPN" SG_ 2364576244 HVESSFastUpdateStateofCharge 5921;
BA_ "SigType" SG_ 2364576244 HVESSFastUpdateStateofCharge 1;
BA_ "GenSigStartValue" SG_ 2364576500 HVESSHighestCellTemperature 8736;
BA_ "SPN" SG_ 2364576500 HVESSHighestCellTemperature 8075;
BA_ "SigType" SG_ 2364576500 HVESSHighestCellTemperature 1;
BA_ "GenSigStartValue" SG_ 2364576500 HVESSLowestCellTemperature 8736;
BA_ "SPN" SG_ 2364576500 HVESSLowestCellTemperature 8076;
BA_ "SigType" SG_ 2364576500 HVESSLowestCellTemperature 1;
BA_ "GenSigStartValue" SG_ 2364576500 HVESSAverageCellTemperature 8736;
BA_ "SPN" SG_ 2364576500 HVESSAverageCellTemperature 8077;
BA_ "SigType" SG_ 2364576500 HVESSAverageCellTemperature 1;
BA_ "SPN" SG_ 2364577012 HVESSMaxCellStateOfCharge 8085;
BA_ "SigType" SG_ 2364577012 HVESSMaxCellStateOfCharge 1;
BA_ "SPN" SG_ 2364577012 HVESSMinCellStateOfCharge 8084;
BA_ "SigType" SG_ 2364577012 HVESSMinCellStateOfCharge 1;
BA_ "GenSigStartValue" SG_ 2364577012 HVESSDischargeCurrentLimit 10000;
BA_ "SPN" SG_ 2364577012 HVESSDischargeCurrentLimit 8082;
BA_ "SigType" SG_ 2364577012 HVESSDischargeCurrentLimit 1;
BA_ "GenSigStartValue" SG_ 2364577012 HVESSChargeCurrentLimit 10000;
BA_ "SPN" SG_ 2364577012 HVESSChargeCurrentLimit 8083;
BA_ "SigType" SG_ 2364577012 HVESSChargeCurrentLimit 1;
BA_ "SPN" SG_ 2364577524 HVESSHighVoltageBusPassiveIsolat 8097;
BA_ "SPN" SG_ 2364577524 HVESSHVILStatus 8098;
BA_ "SPN" SG_ 2364577524 HVESSStatus1Counter 13013;
BA_ "SPN" SG_ 2364577524 HVESSHighVoltageBusConState 8413;
BA_ "SPN" SG_ 2364577524 HVESSOperationalStatus 8414;
BA_ "SPN" SG_ 2364577524 HVESSStatus1CRC 13014;
BA_ "SPN" SG_ 2364580084 HVESSMaximumChargeVoltageLimit 8090;
BA_ "SigType" SG_ 2364580084 HVESSMaximumChargeVoltageLimit 1;
BA_ "SPN" SG_ 2364580084 HVESSChargeEnergyCapacity 8206;
BA_ "SigType" SG_ 2364580084 HVESSChargeEnergyCapacity 1;
BA_ "SPN" SG_ 2364580084 HVESSDischargeEnergyCapacity 8205;
BA_ "SigType" SG_ 2364580084 HVESSDischargeEnergyCapacity 1;
BA_ "SPN" SG_ 2364606964 HVESSThermalManagementSystemHtrS 8234;
BA_ "SPN" SG_ 2364637530 MG1InvModeFeedbackCRC 10164;
BA_ "SPN" SG_ 2364637530 MG1InvModeFeedbackCounter 10165;
BA_ "SPN" SG_ 2364637530 MG1InvFeedbackSetPoint 10167;
BA_ "SPN" SG_ 2566841178 SupportTSC1CtrlPurposeGroup4 3348;
BA_ "SigType" SG_ 2566841178 SupportTSC1CtrlPurposeGroup4 1;
BA_ "SPN" SG_ 2566841178 SupportTSC1CtrlPurposeGroup3 3347;
BA_ "SigType" SG_ 2566841178 SupportTSC1CtrlPurposeGroup3 1;
BA_ "SPN" SG_ 2566841178 SupportTSC1CtrlPurposeGroup2 3346;
BA_ "SigType" SG_ 2566841178 SupportTSC1CtrlPurposeGroup2 1;
BA_ "SPN" SG_ 2566841178 SupportTSC1CtrlPurposeGroup1 3345;
BA_ "SigType" SG_ 2566841178 SupportTSC1CtrlPurposeGroup1 1;
BA_ "SPN" SG_ 2566841178 SupportVariableRateTSC1Message 3344;
BA_ "SigType" SG_ 2566841178 SupportVariableRateTSC1Message 1;
BA_ "SPN" SG_ 2566841178 EngDefaultTorqueLimit 1846;
BA_ "SigType" SG_ 2566841178 EngDefaultTorqueLimit 1;
BA_ "SPN" SG_ 2566841178 EngMomentOfInertia 1794;
BA_ "SigType" SG_ 2566841178 EngMomentOfInertia 1;
BA_ "SPN" SG_ 2566841178 EngExRngRqdSpdCtrlRngUpperLimit 1712;
BA_ "SigType" SG_ 2566841178 EngExRngRqdSpdCtrlRngUpperLimit 1;
BA_ "SPN" SG_ 2566841178 EngRqdTorqueCtrlRangeUpperLimit 538;
BA_ "SigType" SG_ 2566841178 EngRqdTorqueCtrlRangeUpperLimit 1;
BA_ "SPN" SG_ 2566841178 EngRqdTorqueCtrlRangeLowerLimit 537;
BA_ "SigType" SG_ 2566841178 EngRqdTorqueCtrlRangeLowerLimit 1;
BA_ "SPN" SG_ 2566841178 EngRqedSpeedCtrlRangeUpperLimit 536;
BA_ "SigType" SG_ 2566841178 EngRqedSpeedCtrlRangeUpperLimit 1;
BA_ "SPN" SG_ 2566841178 EngRqedSpeedCtrlRangeLowerLimit 535;
BA_ "SigType" SG_ 2566841178 EngRqedSpeedCtrlRangeLowerLimit 1;
BA_ "SPN" SG_ 2566841178 EngMxMomentaryOverrideTimeLimit 534;
BA_ "SigType" SG_ 2566841178 EngMxMomentaryOverrideTimeLimit 1;
BA_ "SPN" SG_ 2566841178 EngMxMmntaryOverrideSpeedPoint7 533;
BA_ "SigType" SG_ 2566841178 EngMxMmntaryOverrideSpeedPoint7 1;
BA_ "SPN" SG_ 2566841178 EngReferenceTorque 544;
BA_ "SigType" SG_ 2566841178 EngReferenceTorque 1;
BA_ "SPN" SG_ 2566841178 EngSpeedAtHighIdlePoint6 532;
BA_ "SigType" SG_ 2566841178 EngSpeedAtHighIdlePoint6 1;
BA_ "SPN" SG_ 2566841178 EngGainOfEndspeedGovernor 545;
BA_ "SigType" SG_ 2566841178 EngGainOfEndspeedGovernor 1;
BA_ "SPN" SG_ 2566841178 EngPercentTorqueAtPoint5 543;
BA_ "SigType" SG_ 2566841178 EngPercentTorqueAtPoint5 1;
BA_ "SPN" SG_ 2566841178 EngSpeedAtPoint5 531;
BA_ "SigType" SG_ 2566841178 EngSpeedAtPoint5 1;
BA_ "SPN" SG_ 2566841178 EngPercentTorqueAtPoint4 542;
BA_ "SigType" SG_ 2566841178 EngPercentTorqueAtPoint4 1;
BA_ "SPN" SG_ 2566841178 EngSpeedAtPoint4 530;
BA_ "SigType" SG_ 2566841178 EngSpeedAtPoint4 1;
BA_ "SPN" SG_ 2566841178 EngPercentTorqueAtPoint3 541;
BA_ "SigType" SG_ 2566841178 EngPercentTorqueAtPoint3 1;
BA_ "SPN" SG_ 2566841178 EngSpeedAtPoint3 529;
BA_ "SigType" SG_ 2566841178 EngSpeedAtPoint3 1;
BA_ "SPN" SG_ 2566841178 EngPercentTorqueAtPoint2 540;
BA_ "SigType" SG_ 2566841178 EngPercentTorqueAtPoint2 1;
BA_ "SPN" SG_ 2566841178 EngSpeedAtPoint2 528;
BA_ "SigType" SG_ 2566841178 EngSpeedAtPoint2 1;
BA_ "SPN" SG_ 2566841178 EngPercentTorqueAtIdlePoint1 539;
BA_ "SigType" SG_ 2566841178 EngPercentTorqueAtIdlePoint1 1;
BA_ "SPN" SG_ 2566841178 EngSpeedAtIdlePoint1 188;
BA_ "SigType" SG_ 2566841178 EngSpeedAtIdlePoint1 1;
BA_ "SPN" SG_ 2365289306 MG1InvReferenceVoltage 10202;
BA_ "SigType" SG_ 2365289306 MG1InvReferenceVoltage 1;
BA_ "SPN" SG_ 2365289306 MG1InvReferenceCRC 10200;
BA_ "SPN" SG_ 2365289306 MG1InvReferenceCounter 10201;
BA_ "SPN" SG_ 2365289306 MG1InvReferenceCurrent 10202;
BA_ "SigType" SG_ 2365289306 MG1InvReferenceCurrent 1;
BA_ "GenSigStartValue" SG_ 2365289562 MG1InvDCVoltageAbs 2000;
BA_ "SPN" SG_ 2365289562 MG1InvDCVoltageAbs 9101;
BA_ "SigType" SG_ 2365289562 MG1InvDCVoltageAbs 1;
BA_ "GenSigStartValue" SG_ 2365289562 MG1InvDCCurrentAbs 2000;
BA_ "SPN" SG_ 2365289562 MG1InvDCCurrentAbs 10175;
BA_ "SigType" SG_ 2365289562 MG1InvDCCurrentAbs 1;
BA_ "SPN" SG_ 2365289562 MG1InvStatus1CRC 10173;
BA_ "SPN" SG_ 2365289562 MG1InvStatus1Counter 10174;
BA_ "GenSigStartValue" SG_ 2365289562 MG1InvDCCurrent 2000;
BA_ "SPN" SG_ 2365289562 MG1InvDCCurrent 10175;
BA_ "SigType" SG_ 2365289562 MG1InvDCCurrent 1;
BA_ "GenSigDbName" SG_ 2365289562 MG1InvDCVoltage "Motor/Generator 1 Inverter DC Side Voltage";
BA_ "GenSigDescription" SG_ 2365289562 MG1InvDCVoltage "The measured or estimated DC side voltage.  ";
BA_ "GenSigStartValue" SG_ 2365289562 MG1InvDCVoltage 2000;
BA_ "SPN" SG_ 2365289562 MG1InvDCVoltage 9101;
BA_ "SigType" SG_ 2365289562 MG1InvDCVoltage 1;
BA_ "SPN" SG_ 2556320347 MG1ILRDC_CRC 10204;
BA_ "SPN" SG_ 2556320347 MG1ILRDC_Counter 10205;
BA_ "GenSigStartValue" SG_ 2556320347 MG1ReqDCCurrentMax 2000;
BA_ "SPN" SG_ 2556320347 MG1ReqDCCurrentMax 10208;
BA_ "SigType" SG_ 2556320347 MG1ReqDCCurrentMax 1;
BA_ "GenSigStartValue" SG_ 2556320347 MG1ReqDCCurrentMin 2000;
BA_ "SPN" SG_ 2556320347 MG1ReqDCCurrentMin 10209;
BA_ "SigType" SG_ 2556320347 MG1ReqDCCurrentMin 1;
BA_ "SPN" SG_ 2564882267 AuxiliaryHtrCoolantPumpRequest 1684;
BA_ "SPN" SG_ 2565537627 ParameterGroupNumberRQST 2540;
BA_ "SPN" SG_ 2565865562 RetarderTorqueMode 900;
BA_ "GenSigStartValue" SG_ 2565865562 ActualRetarderPercentTorque 125;
BA_ "SPN" SG_ 2565865562 ActualRetarderPercentTorque 520;
BA_ "SigType" SG_ 2565865562 ActualRetarderPercentTorque 1;
BA_ "GenSigStartValue" SG_ 2565865562 IntendedRetarderPercentTorque 125;
BA_ "SPN" SG_ 2565865562 IntendedRetarderPercentTorque 1085;
BA_ "SigType" SG_ 2565865562 IntendedRetarderPercentTorque 1;
BA_ "GenSigStartValue" SG_ 2565865562 ActMaxAvailRetarderPercentTorque 125;
BA_ "SPN" SG_ 2565865562 ActMaxAvailRetarderPercentTorque 1717;
BA_ "SigType" SG_ 2565865562 ActMaxAvailRetarderPercentTorque 1;
VAL_ 3221225472 HVESChargeConsent 0 "Charging of HVES system is not allowed" 1 "Charging of HVES system is allowed" 2 "SAE Reserved" 3 "Not Available" ;
VAL_ 3221225472 ExtlESConnectionDemand 0 "No Connection" 1 "Perform Connection 1 Verification" 2 "Energy Drain or Source Connection 1" 3 "Energy Source Connection 1" 4 "Energy Drain Connection 1" 5 "Perform Connection 2 Verification" 6 "Energy Drain or Source Connection 2" 7 "Energy Source Connection 2" 8 "Energy Drain Connection 2" 9 "Perform Connection 3 Verification" 10 "Energy Drain or Source Connection 3" 11 "Energy Source Connection 3" 12 "Energy Drain Connection 3" 13 "SAE Reserved" 14 "Disconnect Request" 15 "No Request/Take no action" ;
VAL_ 3221225472 PropulsionModeReq 0 "No mode requested" 1 "Stored Energy Source Sustaining" 2 "Stored Energy Source Increasing" 3 "Stored Energy Source Depleting" 4 "Stored Energy Source Offline" 5 "Stored Energy Source Only" 14 "Error" 15 "Not Available" ;
VAL_ 3221225472 OpVehModeReq 0 "Off" 1 "Low Voltage Accessory" 2 "Stored Energy Source Active" 3 "Propulsion Active" 4 "to13" 14 "Error" 15 "Not Available" ;
VAL_ 3221225472 ShutdownCmd 0 "Off" 1 "On" 2 "Reserved" 3 "Don't Care / Take No Action" ;
VAL_ 3221225472 PropulsionDisableReq 0 "Off" 1 "On" 2 "Reserved" 3 "Don't Care / Take No Action" ;
VAL_ 3221225472 HybrdSystmRgnrtvBrakingDisableRq 0 "Regenerative braking disable request is not active" 1 "Regenerative braking disable request is active" 2 "Reserved" 3 "Don't care / take no action" ;
VAL_ 3221225472 HybridSystemProtectionOverrideRq 0 "Not active" 1 "Active" 2 "Reserved" 3 "Don't care / take no action" ;
VAL_ 3221225472 HVESSThermalMnmgtMaintenanceSw 0 "Off" 1 "On" 2 "Error" 3 "Not available" ;
VAL_ 3221225472 PropulsionMotorCoolantFillSw 0 "Off" 1 "On" 2 "Error" 3 "Not available" ;
VAL_ 3221225472 PwrECoolantFillSw 0 "Off" 1 "On" 2 "Error" 3 "Not available" ;
VAL_ 3221225472 ShutdownSw 0 "Off" 1 "On" 2 "Error" 3 "Not Available" ;
VAL_ 3221225472 PropulsionDisableSw 0 "Off" 1 "On" 2 "Error" 3 "Not Available" ;
VAL_ 3221225472 HybrdSystmBrkPdlRgnrtvBrkngDsblS 0 "Brake pedal regenerative braking disable switch is off" 1 "Brake pedal regenerative braking disable switch is on" 2 "Error" 3 "Not Available" ;
VAL_ 3221225472 HybrdSystmRgnrtvBrkngDsbleSwitch 0 "Regenerative Braking Disable Switch is off" 1 "Regenerative Braking  Disable Switch is on" 2 "Error" 3 "Not Available" ;
VAL_ 3221225472 HybrdSystmPwrElctrncsClntLvlSwtc 0 "Coolant Level is not sufficient" 1 "Coolant Level is sufficient" 2 "Error" 3 "Not Available" ;
VAL_ 3221225472 HybrdSystmPrplsnClantLevelSwitch 0 "Coolant Level is not sufficient" 1 "Coolant Level is sufficient" 2 "Error" 3 "Not Available" ;
VAL_ 3221225472 HybrdSystmPrtctionOverrideSwitch 0 "Not Active" 1 "Active" 2 "Error" 3 "Not Available" ;
VAL_ 2566899449 ChargingSessionState 4 "ChargeSessionOngoing" 3 "Shutdown_CCU" 2 "Shutdown_EVSE" 1 "Shutdown_EV" 0 "No plug inserted" ;
VAL_ 2566866580 comp_overload 0 "OK" 1 "Fault" ;
VAL_ 2566866580 comp_temp_sens_shorted 0 "OK" 1 "Fault" ;
VAL_ 2566866580 comp_temp_sens_open 0 "OK" 1 "Fault" ;
VAL_ 2566866580 Oil_lev_switch_shorted_gnd 0 "OK" 1 "Fault" ;
VAL_ 2566866580 Oil_lev_switch_shorted_power 0 "OK" 1 "Fault" ;
VAL_ 2566866580 HVIL_Out_Open_Circuit_Fault 0 "Not active" 1 "Active" ;
VAL_ 2566866580 HVIL_In_Open_Circuit_Fault 0 "Not active" 1 "Active" ;
VAL_ 2566866580 HVIL_Open_Circuit_Fault 0 "Not active" 1 "Active" ;
VAL_ 2566866580 HVIL_Over_Current_Fault 0 "Not active" 1 "Active" ;
VAL_ 2566866580 Mult_Int_Temp_Sensor_Fault 0 "Not active" 1 "Active" ;
VAL_ 2566866580 Torque_High_Reduced_Speed 0 "Not active" 1 "Active" ;
VAL_ 2566866580 Internal_Temp_Sensor_Fault 0 "Not active" 1 "Active" ;
VAL_ 2566866580 Oil_Level_Switch_Circuit_Short 0 "Not active" 1 "Active" ;
VAL_ 2566866580 Oil_Level_Switch_Circuit_Open 0 "Not active" 1 "Active" ;
VAL_ 2566866580 CAN_Bus_Fault 0 "Not active" 1 "Active" ;
VAL_ 2566866580 EEPROM_Checksum_Fault 0 "Not active" 1 "Active" ;
VAL_ 2566866580 ESCM_Enable_Component_SPN_Error 0 "Not active" 1 "Active" ;
VAL_ 2566866580 ESCM_Max_Current_SPN_Error 0 "Not active" 1 "Active" ;
VAL_ 2566866580 ESCM_Speed_Request_SPN_Error 0 "Not active" 1 "Active" ;
VAL_ 2566866580 Speed_Req_PGN_Fault 0 "Not active" 1 "Active" ;
VAL_ 2566866580 Oil_Level_Low 0 "Not active" 1 "Active" ;
VAL_ 2566866580 Emotor_Over_Temperature 0 "Not active" 1 "Active" ;
VAL_ 2566866580 Compressor_Over_Temperature 0 "Not active" 1 "Active" ;
VAL_ 2566866580 No_Connection_With_PU 0 "Not active" 1 "Active" ;
VAL_ 2566866580 Power_Stage_Error 0 "Not active" 1 "Active" ;
VAL_ 2566866580 Overload 0 "Not active" 1 "Active" ;
VAL_ 2566866580 Traction_Volt_High 0 "Not active" 1 "Active" ;
VAL_ 2566866580 Traction_Supply_Current_Low 0 "Not active" 1 "Active" ;
VAL_ 2566866580 Traction_Volt_Low 0 "Not active" 1 "Active" ;
VAL_ 2566866580 Traction_Volt_Critical_Low 0 "Not active" 1 "Active" ;
VAL_ 2365484270 DirectionIndicator 0 "Forward" 1 "Reverse" 2 "Error" 3 "Not available" ;
VAL_ 2365484270 TachographPerformance 0 "Normal performance" 1 "Performance analysis" 2 "Error" 3 "Not available" ;
VAL_ 2365484270 HandlingInformation 0 "No handling information" 1 "Handling information" 2 "Error" 3 "Not available" ;
VAL_ 2365484270 SystemEvent 0 "No tachograph event" 1 "Tachograph event" 2 "Error" 3 "Not available" ;
VAL_ 2365484270 DriverCardDriver2 0 "Driver card not present" 1 "Driver card present" 2 "Error" 3 "Not available" ;
VAL_ 2365484270 Driver2TimeRelatedStates 0 "Normal/No limits reached" 1 "Limit #1" 2 "Limit #2" 3 "Limit #3" 4 "Limit #4" 5 "Limit #5" 6 "Limit #6" 7 "Reserved" 8 "Reserved" 9 "Reserved" 10 "Reserved" 11 "Reserved" 12 "Reserved" 13 "Other" 14 "Error" 15 "Not available" ;
VAL_ 2365484270 VehicleOverspeed 0 "No overspeed" 1 "Overspeed" 2 "Error" 3 "Not available" ;
VAL_ 2365484270 DriverCardDriver1 0 "Driver card not present" 1 "Driver card present" 2 "Error" 3 "Not available" ;
VAL_ 2365484270 Driver1TimeRelatedStates 0 "Normal/No limits reached" 1 "Limit #1" 2 "Limit #2" 3 "Limit #3" 4 "Limit #4" 5 "Limit #5" 6 "Limit #6" 7 "Reserved" 8 "Reserved" 9 "Reserved" 10 "Reserved" 11 "Reserved" 12 "Reserved" 13 "Other" 14 "Error" 15 "Not available" ;
VAL_ 2365484270 VehicleMotion 0 "Vehicle motion not detected" 1 "Vehicle motion detected" 2 "Error" 3 "Not available" ;
VAL_ 2365484270 Driver2WorkingState 0 "Rest" 1 "Driver available" 2 "Work" 3 "Drive" 4 "Reserved" 5 "Reserved" 6 "Error" 7 "Not available" ;
VAL_ 2365484270 Driver1WorkingState 0 "Rest" 1 "Driver available" 2 "Work" 3 "Drive" 4 "Reserved" 5 "Reserved" 6 "Error" 7 "Not available" ;
VAL_ 2566846554 TransmissionOilTemperature1 64256 "PARAMETER_SPECIFIC" 64257 "PARAMETER_SPECIFIC" 65024 "ERROR" 65535 "NOT_AVAILABLE" ;
VAL_ 2566615642 MotorGenerator1InverterTemp1 251 "PARAMETER_SPECIFIC" 254 "ERROR" 255 "NOT_AVAILABLE" ;
VAL_ 2566615642 MotorGenerator1InverterTemp2 251 "PARAMETER_SPECIFIC" 254 "ERROR" 255 "NOT_AVAILABLE" ;
VAL_ 2566615386 MotorGenerator1Temperature1 251 "PARAMETER_SPECIFIC" 254 "ERROR" 255 "NOT_AVAILABLE" ;
VAL_ 2566615386 MotorGenerator1Temperature2 251 "PARAMETER_SPECIFIC" 254 "ERROR" 255 "NOT_AVAILABLE" ;
VAL_ 2348820747 EngineOverrideControlMode 3 "Speed/torque limit control" 2 "Torque control" 1 "Speed control" 0 "Override disabled" ;
VAL_ 2348820747 OverrideControlModePriority 3 "Low Priority " 2 "Medium Priority" 1 "High Priority " 0 "Highest Priority" ;
VAL_ 2348820747 EngineRequestedTorqueTorqueLimit 251 "PARAMETER_SPECIFIC" 254 "ERROR" 255 "NOT_AVAILABLE" ;
VAL_ 2348820747 TSC1TransmissionRate 7 "Use standard TSC1 transmission rates of 10 ms to engine" 6 "20 ms transmission rate" 5 "50 ms transmission rate" 4 "100 ms transmission rate" 3 "250 ms transmission rate" 2 "500 ms transmission rate" 1 "750 ms transmission rate" 0 "1000 ms transmission rate" ;
VAL_ 2348820747 TSC1ControlPurpose 31 "P32  Temporary Power Train Control (Original use of TSC1 Command)" 4 "P5  Engine Protection" 3 "P4  Road Speed Governor" 2 "P3  PTO Governor" 1 "P2  Cruise Control" 0 "P1  Accelerator Pedal/Operator Selection" ;
VAL_ 2348820747 TSC1AXR_Counter 15 "NOT_AVAILABLE" ;
VAL_ 2348820747 TSC1AXR_Checksum 15 "NOT_AVAILABLE" ;
VAL_ 2565865739 ASREngineControlActive 0 "PASSIVE" 1 "ACTIVE" 3 "NOT_AVAILABLE" ;
VAL_ 2565865739 ASRBrakeControlActive 0 "PASSIVE" 1 "ACTIVE" 3 "NOT_AVAILABLE" ;
VAL_ 2565865739 AntiLockBrakingABSActive 0 "PASSIVE" 1 "ACTIVE" 3 "NOT_AVAILABLE" ;
VAL_ 2565865739 EBSBrakeSwitch 0 "NOT_PRESSED" 1 "PRESSED" 2 "ERROR" 3 "NOT_AVAILABLE" ;
VAL_ 2565865739 BrakePedalPosition 251 "PARAMETER_SPECIFIC" 254 "ERROR" 255 "NOT_AVAILABLE" ;
VAL_ 2565865739 ASROffroadSwitch 0 "PASSIVE" 1 "ACTIVE" 2 "ERROR" 3 "NOT_AVAILABLE" ;
VAL_ 2565865739 ASRHillHolderSwitch 0 "PASSIVE" 1 "ACTIVE" 2 "ERROR" 3 "NOT_AVAILABLE" ;
VAL_ 2566900510 HVJBInternalTemperature1 254 "ERROR" 255 "NOT_AVAILABLE" ;
VAL_ 2566900510 HVJBInternalTemperature2 254 "ERROR" 255 "NOT_AVAILABLE" ;
VAL_ 2566900510 HVJBInternalTemperature3 254 "ERROR" 255 "NOT_AVAILABLE" ;
VAL_ 2566900510 HVJBInternalTemperature4 254 "ERROR" 255 "NOT_AVAILABLE" ;
VAL_ 2566900510 HVJBInternalTemperature5 254 "ERROR" 255 "NOT_AVAILABLE" ;
VAL_ 2566900510 HVJBInternalTemperature6 254 "ERROR" 255 "NOT_AVAILABLE" ;
VAL_ 2566900510 HVJBInternalTemperature7 254 "ERROR" 255 "NOT_AVAILABLE" ;
VAL_ 2566900510 HVJBInternalTemperature8 254 "ERROR" 255 "NOT_AVAILABLE" ;
VAL_ 2566831883 FrontAxleSpeed 64256 "PARAMETER_SPECIFIC" 65024 "ERROR" 65535 "NOT_AVAILABLE" ;
VAL_ 2566831883 RelativeSpeedFrontAxleLeftWheel 251 "PARAMETER_SPECIFIC" 254 "ERROR" 255 "NOT_AVAILABLE" ;
VAL_ 2566831883 RelativeSpeedFrontAxleRightWheel 251 "PARAMETER_SPECIFIC" 254 "ERROR" 255 "NOT_AVAILABLE" ;
VAL_ 2566831883 RelativeSpeedRearAxle1LeftWheel 251 "PARAMETER_SPECIFIC" 254 "ERROR" 255 "NOT_AVAILABLE" ;
VAL_ 2566831883 RelativeSpeedRearAxle1RightWheel 251 "PARAMETER_SPECIFIC" 254 "ERROR" 255 "NOT_AVAILABLE" ;
VAL_ 2566831883 RelativeSpeedRearAxle2LeftWheel 251 "PARAMETER_SPECIFIC" 254 "ERROR" 255 "NOT_AVAILABLE" ;
VAL_ 2566831883 RelativeSpeedRearAxle2RightWheel 251 "PARAMETER_SPECIFIC" 254 "ERROR" 255 "NOT_AVAILABLE" ;
VAL_ 2566860803 LeverToNeutral 3 "NOT_AVAILABLE" ;
VAL_ 2566860803 Leverposunequaltodrivepos 3 "NOT_AVAILABLE" ;
VAL_ 2566860803 ManualShiftingFleetVersion 3 "NOT_AVAILABLE" ;
VAL_ 2566860803 AMIndication 0 "OFF" 1 "M_INDICATION_ON" 2 "A_INDICATION_ON" ;
VAL_ 2566860803 ActivePTO1 3 "NOT_AVAILABLE" ;
VAL_ 2566860803 ActivePTO2 0 "NOT_ALLOWED" 1 "ALLOWED" 3 "NOT_AVAILABLE" ;
VAL_ 2566860803 Directionindicator 0 "Forward" 1 "Reverse" 2 "Error" 3 "Not Available" ;
VAL_ 2566860803 ECOrollEventWhenDisabled 3 "NOT_AVAILABLE" ;
VAL_ 2566840835 NumberofReverseGearRatios 251 "PARAMETER_SPECIFIC" 254 "ERROR" 255 "NOT_AVAILABLE" ;
VAL_ 2566840835 NumberofForwardGearRatios 251 "PARAMETER_SPECIFIC" 254 "ERROR" 255 "NOT_AVAILABLE" ;
VAL_ 2566840835 TransmissionGearRatio 64256 "PARAMETER_SPECIFIC" 64257 "PARAMETER_SPECIFIC" ;
VAL_ 2364539395 TransmissionDrivelineEngaged 0 "DISENGAGED" 1 "ENGAGED" 2 "ERROR" 3 "NOT_AVAILABLE" ;
VAL_ 2364539395 TransTrqConverterLockupEngaged 0 "DISENGAGED" 1 "ENGAGED" 3 "NOT_AVAILABLE" ;
VAL_ 2364539395 TransmissionShiftInProcess 0 "NOT_IN_PROCESS" 1 "IN_PROCESS" 2 "ERROR" 3 "NOT_AVAILABLE" ;
VAL_ 2364539395 TransmissionOutputShaftSpeed 64256 "PARAMETER_SPECIFIC" 64257 "PARAMETER_SPECIFIC" 64258 "PARAMETER_SPECIFIC" 65535 "NOT_AVAILABLE" ;
VAL_ 2364539395 PercentClutchSlip 251 "PARAMETER_SPECIFIC" 254 "ERROR" 255 "NOT_AVAILABLE" ;
VAL_ 2364539395 ProgressiveShiftDisable 0 "NOT_DISABLED" 1 "DISABLED" 3 "NOT_AVAILABLE" ;
VAL_ 2364539395 TransmissionInputShaftSpeed 64256 "PARAMETER_SPECIFIC" 65024 "ERROR" 65535 "NOT_AVAILABLE" ;
VAL_ 2566801923 TransmissionReadyforBrakeRelease 2 "ERROR" 3 "NOT_AVAILABLE" ;
VAL_ 2566801923 TransmissionEngineCrankEnable 0 "DISABLED" 1 "ENABLED" 3 "NOT_AVAILABLE" ;
VAL_ 2566801923 TransmissionMode2Indicator 0 "NOT_ACTIVE" 1 "ACTIVE" 2 "ERROR" 3 "NOT_AVAILABLE" ;
VAL_ 2566801923 TransmissionMode1Indicator 0 "NOT_ACTIVE" 1 "ACTIVE" 2 "ERROR" 3 "NOT_AVAILABLE" ;
VAL_ 2566801923 TransmissionMode6Indicator 0 "NOT_ACTIVE" 1 "ACTIVE" 2 "ERROR" 3 "NOT_AVAILABLE" ;
VAL_ 2566801923 TransmissionMode7Indicator 0 "NOT_ACTIVE" 1 "ACTIVE" 2 "ERROR" 3 "NOT_AVAILABLE" ;
VAL_ 2566801923 TransmissionMode8Indicator 0 "NOT_ACTIVE" 1 "ACTIVE" 2 "ERROR" 3 "NOT_AVAILABLE" ;
VAL_ 2364539648 AcceleratorPedal1LowIdleSwitch 0 "NOT_IN_LOW_IDLE_CONDITION" 2 "LOW_IDLE_CONDITION" 3 "NOT_AVAILABLE" ;
VAL_ 2364539648 AcceleratorPedalKickdownSwitch 0 "NOT_ACTIVE" 1 "ACTIVE" 2 "ERROR" 3 "NOT_AVAILABLE" ;
VAL_ 2364539648 RoadSpeedLimitStatus 0 "ACTIVE" 1 "NOT_ACTIVE" 3 "NOT_AVAILABLE" ;
VAL_ 2364539648 AcceleratorPedalPosition1 251 "PARAMETER_SPECIFIC" 254 "ERROR" 255 "NOT_AVAILABLE" ;
VAL_ 2364539648 EnginePercentLoadAtCurrentSpeed 251 "PARAMETER_SPECIFIC" 254 "ERROR" 255 "NOT_AVAILABLE" ;
VAL_ 2364539648 RemoteAcceleratorPedalPosition 251 "PARAMETER_SPECIFIC" 254 "ERROR" 255 "NOT_AVAILABLE" ;
VAL_ 2364539648 VehicleAccelRateLimitStatus 0 "NOT_ACTIVE" 1 "ACTIVE" 3 "NOT_AVAILABLE" ;
VAL_ 2364539648 DPFThermalManagementActive 3 "NOT_AVAILABLE" ;
VAL_ 2364539648 SCRThermalManagementActive 3 "NOT_AVAILABLE" ;
VAL_ 2364539648 ActMaximumAvailEngPercentTorque 251 "PARAMETER_SPECIFIC" 254 "ERROR" 255 "NOT_AVAILABLE" ;
VAL_ 2364539648 EstimatedPumpingPercentTorque 251 "PARAMETER_SPECIFIC" 254 "ERROR" 255 "NOT_AVAILABLE" ;
VAL_ 2364606708 HVESSModule1OperationalStatus 2 "ERROR" 3 "NOT_AVAILABLE" ;
VAL_ 2364606708 HVESSModule2OperationalStatus 2 "ERROR" 3 "NOT_AVAILABLE" ;
VAL_ 2364606708 HVESSModule3OperationalStatus 2 "ERROR" 3 "NOT_AVAILABLE" ;
VAL_ 2364606708 HVESSModule4OperationalStatus 2 "ERROR" 3 "NOT_AVAILABLE" ;
VAL_ 2364606708 HVESSModule5OperationalStatus 2 "ERROR" 3 "NOT_AVAILABLE" ;
VAL_ 2364606708 HVESSModule6OperationalStatus 2 "ERROR" 3 "NOT_AVAILABLE" ;
VAL_ 2364606708 HVESSModule7OperationalStatus 2 "ERROR" 3 "NOT_AVAILABLE" ;
VAL_ 2364606708 HVESSModule8OperationalStatus 2 "ERROR" 3 "NOT_AVAILABLE" ;
VAL_ 2364606708 HVESSModule9OperationalStatus 2 "ERROR" 3 "NOT_AVAILABLE" ;
VAL_ 2565866755 TransmissionSelectedGear 251 "PARAMETER_SPECIFIC" 254 "ERROR" 255 "NOT_AVAILABLE" ;
VAL_ 2565866755 TransmissionActualGearRatio 64256 "PARAMETER_SPECIFIC" 64257 "PARAMETER_SPECIFIC" 64258 "PARAMETER_SPECIFIC" 65535 "NOT_AVAILABLE" ;
VAL_ 2565866755 TransmissionCurrentGear 251 "PARAMETER_SPECIFIC" 254 "ERROR" 255 "NOT_AVAILABLE" ;
VAL_ 2565866755 TransmissionRequestedRange 0 "ERROR" 255 "NOT_AVAILABLE" ;
VAL_ 2348810251 EngineOverrideControlMode 3 "Speed/torque limit control" 2 "Torque control" 1 "Speed control" 0 "Override disabled" ;
VAL_ 2348810251 OverrideControlModePriority 3 "Low Priority " 2 "Medium Priority" 1 "High Priority " 0 "Highest Priority" ;
VAL_ 2348810251 TSC1TransmissionRate 7 "Use standard TSC1 transmission rates of 10 ms to engine" 6 "20 ms transmission rate" 5 "50 ms transmission rate" 4 "100 ms transmission rate" 3 "250 ms transmission rate" 2 "500 ms transmission rate" 1 "750 ms transmission rate" 0 "1000 ms transmission rate" ;
VAL_ 2348810251 TSC1ControlPurpose 31 "P32  Temporary Power Train Control (Original use of TSC1 Command)" 4 "P5  Engine Protection" 3 "P4  Road Speed Governor" 2 "P3  PTO Governor" 1 "P2  Cruise Control" 0 "P1  Accelerator Pedal/Operator Selection" ;
VAL_ 2348810400 EngineOverrideControlMode 3 "Speed/torque limit control" 2 "Torque control" 1 "Speed control" 0 "Override disabled" ;
VAL_ 2348810400 OverrideControlModePriority 3 "Low Priority " 2 "Medium Priority" 1 "High Priority " 0 "Highest Priority" ;
VAL_ 2348810400 TSC1TransmissionRate 7 "Use standard TSC1 transmission rates of 10 ms to engine" 6 "20 ms transmission rate" 5 "50 ms transmission rate" 4 "100 ms transmission rate" 3 "250 ms transmission rate" 2 "500 ms transmission rate" 1 "750 ms transmission rate" 0 "1000 ms transmission rate" ;
VAL_ 2348810400 TSC1ControlPurpose 31 "P32  Temporary Power Train Control (Original use of TSC1 Command)" 4 "P5  Engine Protection" 3 "P4  Road Speed Governor" 2 "P3  PTO Governor" 1 "P2  Cruise Control" 0 "P1  Accelerator Pedal/Operator Selection" ;
VAL_ 2566844711 TwoSpeedAxleSwitch 0 "LOW_SPEED_RANGE" 2 "HIGH_SPEED_RANGE" 3 "NOT_AVAILABLE" ;
VAL_ 2566844711 ParkingBrakeSwitch 0 "OFF" 1 "ON" 2 "ERROR" 3 "NOT_AVAILABLE" ;
VAL_ 2566844711 CruiseControlPauseSwitch 0 "OFF" 1 "ON" 2 "ERROR" 3 "NOT_AVAILABLE" ;
VAL_ 2566844711 CruiseControlActive 0 "OFF" 1 "ON" 2 "ERROR" 3 "NOT_AVAILABLE" ;
VAL_ 2566844711 CruiseControlEnableSwitch 0 "DISABLED" 1 "ENABLED" 2 "ERROR" 3 "NOT_AVAILABLE" ;
VAL_ 2566844711 BrakeSwitch 0 "RELEASED" 1 "DEPRESSED" 2 "ERROR" 3 "NOT_AVAILABLE" ;
VAL_ 2566844711 ClutchSwitch 0 "RELEASED" 1 "DEPRESSED" 2 "ERROR" 3 "NOT_AVAILABLE" ;
VAL_ 2566844711 CruiseControlSetSwitch 0 "OFF" 1 "ON" 2 "ERROR" 3 "NOT_AVAILABLE" ;
VAL_ 2566844711 CruiseCtrlCoastDecelerateSwitch 0 "OFF" 1 "ON" 2 "ERROR" 3 "NOT_AVAILABLE" ;
VAL_ 2566844711 CruiseControlResumeSwitch 0 "OFF" 1 "ON" 2 "ERROR" 3 "NOT_AVAILABLE" ;
VAL_ 2566844711 CruiseControlAccelerateSwitch 0 "OFF" 1 "ON" 2 "ERROR" 3 "NOT_AVAILABLE" ;
VAL_ 2566844711 CruiseControlSetSpeed 251 "PARAMETER_SPECIFIC" 254 "ERROR" 255 "NOT_AVAILABLE" ;
VAL_ 2566844711 PTOGovernorState 0 "OFF_DISABLED" 1 "HOLD" 2 "REMOTE_HOLD" 3 "STANDBY" 4 "REMOTE_STANDBY" 5 "SET" 6 "RESUME" 7 "ACCELERATE" 8 "ACCELERATOR_OVERRIDE" 9 "PREPROGRAMMED_SETSPEED_1" 10 "PREPROGRAMMED_SETSPEED_2" 11 "PREPROGRAMMED_SETSPEED_3" 12 "PREPROGRAMMED_SETSPEED_4" 13 "PREPROGRAMMED_SETSPEED_5" 14 "PREPROGRAMMED_SETSPEED_6" 15 "PREPROGRAMMED_SETSPEED_7" 16 "PREPROGRAMMED_SETSPEED_8" 17 "PTO_SETSPEED_MEMORY_1" 18 "PTO_SETSPEED_MEMORY_2" 31 "NOT_AVAILABLE" ;
VAL_ 2566844711 CruiseControlStates 0 "OFF_DISABLED" 1 "HOLD" 2 "ACCELERATE" 3 "DECELERATE" 4 "RESUME" 5 "SET" 6 "ACCELERATOR_OVERRIDE" 7 "NOT_AVAILABLE" ;
VAL_ 2566857255 TransmissionRequestedGear 28 "ManouveringReverse" 222 "NeutralSelectorPosition" 223 "ReverseSelectorPosition" 228 "ManouveringForward" 252 "ForwardDrivePosition" 254 "Error" 255 "Notavailable" ;
VAL_ 2566857255 VECU_TC1_Counter 15 "NOT_AVAILABLE" ;
VAL_ 2566857255 VECU_TC1_Checksum 15 "NOT_AVAILABLE" ;
VAL_ 2351323687 MG1InvCtrlSetPoint 0 "Power On" 2 "Standby" 7 "Enable Torque Control Mode" 8 "Enable Speed Control Mode" 9 "Enable DC Side Voltage Mode" 10 "Enable DC Side Current Mode" 11 "Enable DC Power Control Mode" 12 "Enable Mech. PowerControlMode" 31 " Dont Care/Take No Action" ;
VAL_ 2348833280 EngineOverrideControlMode 3 "Speed/torque limit control" 2 "Torque control" 1 "Speed control" 0 "Override disabled" ;
VAL_ 2348833280 OverrideControlModePriority 3 "Low Priority " 2 "Medium Priority" 1 "High Priority " 0 "Highest Priority" ;
VAL_ 2348833280 EngineRequestedTorqueTorqueLimit 251 "PARAMETER_SPECIFIC" 254 "ERROR" 255 "NOT_AVAILABLE" ;
VAL_ 2348833280 TSC1TransmissionRate 7 "Use standard TSC1 transmission rates of 10 ms to engine" 6 "20 ms transmission rate" 5 "50 ms transmission rate" 4 "100 ms transmission rate" 3 "250 ms transmission rate" 2 "500 ms transmission rate" 1 "750 ms transmission rate" 0 "1000 ms transmission rate" ;
VAL_ 2348833280 TSC1ControlPurpose 31 "P32  Temporary Power Train Control (Original use of TSC1 Command)" 4 "P5  Engine Protection" 3 "P4  Road Speed Governor" 2 "P3  PTO Governor" 1 "P2  Cruise Control" 0 "P1  Accelerator Pedal/Operator Selection" ;
VAL_ 2348833280 EngineRequestedTorqueFractional 8 "NOT_AVAILABLE" 9 "NOT_AVAILABLE" 10 "NOT_AVAILABLE" 11 "NOT_AVAILABLE" 12 "NOT_AVAILABLE" 13 "NOT_AVAILABLE" 14 "NOT_AVAILABLE" 15 "NOT_AVAILABLE" ;
VAL_ 2348833280 MessageCounter 15 "NOT_AVAILABLE" ;
VAL_ 2348833280 MessageChecksum 15 "NOT_AVAILABLE" ;
VAL_ 2348833321 EngineOverrideControlMode 3 "Speed/torque limit control" 2 "Torque control" 1 "Speed control" 0 "Override disabled" ;
VAL_ 2348833321 OverrideControlModePriority 3 "Low Priority " 2 "Medium Priority" 1 "High Priority " 0 "Highest Priority" ;
VAL_ 2348833321 EngineRequestedTorqueTorqueLimit 251 "PARAMETER_SPECIFIC" 254 "ERROR" 255 "NOT_AVAILABLE" ;
VAL_ 2348833321 TSC1TransmissionRate 7 "Use standard TSC1 transmission rates of 10 ms to engine" 6 "20 ms transmission rate" 5 "50 ms transmission rate" 4 "100 ms transmission rate" 3 "250 ms transmission rate" 2 "500 ms transmission rate" 1 "750 ms transmission rate" 0 "1000 ms transmission rate" ;
VAL_ 2348833321 TSC1ControlPurpose 31 "P32  Temporary Power Train Control (Original use of TSC1 Command)" 4 "P5  Engine Protection" 3 "P4  Road Speed Governor" 2 "P3  PTO Governor" 1 "P2  Cruise Control" 0 "P1  Accelerator Pedal/Operator Selection" ;
VAL_ 2348833321 EngineRequestedTorqueFractional 8 "NOT_AVAILABLE" 9 "NOT_AVAILABLE" 10 "NOT_AVAILABLE" 11 "NOT_AVAILABLE" 12 "NOT_AVAILABLE" 13 "NOT_AVAILABLE" 14 "NOT_AVAILABLE" 15 "NOT_AVAILABLE" ;
VAL_ 2348833321 MessageCounter 15 "NOT_AVAILABLE" ;
VAL_ 2348833321 MessageChecksum 15 "NOT_AVAILABLE" ;
VAL_ 2350642267 HVESSHighVoltageBusConnectCmd 0 "OpenContactor" 1 "CloseContactor" 2 "EmergencyClosureRequest" 3 "TakeNoAction" ;
VAL_ 2350642267 HVESSPowerDownCommand 0 "NotRrequested" 1 "NormalPowerDown" 2 "EmergencyPowerdown" 3 "TakeNoAction" ;
VAL_ 2350642267 HVESSHighVoltageBusPassiveIsolat 0 "PassiveIsoTestNotRequested" 1 "PassiveIsoTestRequest" 2 "InhibitPassiveIsoTest" 3 "TakeNoAction" ;
VAL_ 2364539738 ActMaximumAvailEngPercentTorque 251 "PARAMETER_SPECIFIC" 254 "ERROR" 255 "NOT_AVAILABLE" ;
VAL_ 2364539994 EngineTorqueMode 15 "NOT_AVAILABLE" ;
VAL_ 2364539994 ActEnginePercentTorqueFractional 8 "NOT_AVAILABLE" 9 "NOT_AVAILABLE" 10 "NOT_AVAILABLE" 11 "NOT_AVAILABLE" 12 "NOT_AVAILABLE" 13 "NOT_AVAILABLE" 14 "NOT_AVAILABLE" 15 "NOT_AVAILABLE" ;
VAL_ 2364539994 ActualEnginePercentTorque 251 "PARAMETER_SPECIFIC" 254 "ERROR" 255 "NOT_AVAILABLE" ;
VAL_ 2364576244 HVESSCellVoltageDifferenceStatus 0 "Cell-to-cell voltage differential is within acceptable limits" 1 "Cell-to-cell voltage differential exceeds acceptable limits but can be corrected via auto-balancing" 2 "Limits exceeded - external maintenance balancing is required to restore battery performance" 3 "Limits exceeded - external maintenance balancing cannot restore battery performance" 4 "Cell-to-cell voltage differential exceeds acceptable limits" 5 "Reserved" 6 "Reserved" 7 "Reserved" 8 "Reserved" 9 "Reserved" 10 "Reserved" 11 "Reserved" 12 "Reserved" 13 "Reserved" 14 "Error" 15 "Not Available" ;
VAL_ 2364577524 HVESSHighVoltageBusPassiveIsolat 0 "NoTestRequested" 1 "TestRequestedNotinProcess" 2 "Testinprocess" 3 "TestcompleteIsoOK" 4 "TestcompleteIsoMarginal" 5 "TestcompleteIsoNOK" 6 "TestInhibited" 7 "Reserved" 8 "Reserved" 9 "Reserved" 10 "Reserved" 11 "Reserved" 12 "Reserved" 13 "Reserved" 14 "Error" 15 "Notavailable" ;
VAL_ 2364577524 HVESSHVILStatus 0 "HVILClosed" 1 "HVILOpen" 2 "Error" 3 "NotAvailable" ;
VAL_ 2364577524 HVESSHighVoltageBusConState 0 "Disconnected" 1 "Connected" 2 "ConnectioninProcess" 3 "DisconnectioninProcess" 4 "Disconnected" 5 "Reserved" 6 "Reserved" 7 "Reserved" 8 "Reserved" 9 "Reserved" 10 "Reserved" 11 "Reserved" 12 "Reserved" 13 "Reserved" 14 "Error" 15 "NotAvailable" ;
VAL_ 2364577524 HVESSOperationalStatus 0 "InitializationInProcess" 1 "InitializationComplete" 2 "Operational" 3 "NormalPowerDown" 4 "EmergencyPowerDown" 5 "DisabledByExternalCommand" 6 "DisabledByInternalDecision" 7 "Reserved" 8 "Reserved" 9 "Reserved" 10 "Reserved" 11 "Reserved" 12 "Reserved" 13 "Reserved" 14 "Error" 15 "NotAvailable" ;
VAL_ 2364606964 HVESSThermalManagementSystemHtrS 2 "ERROR" 3 "NOT_AVAILABLE" ;
VAL_ 2364637530 MG1InvFeedbackSetPoint 0 "Power On" 2 "Standby" 7 "Enable Torque Control Mode" 8 "Enable Speed Control Mode" 9 "Enable DC Side Voltage Mode" 10 "Enable DC Side Current Mode" 11 "Enable DC Power Control Mode" 12 "Enable Mech PowerControlMode" 28 "RedStop Lamp active (ZF special mode 1)" 30 "Error" 31 " Dont Care/Take No Action" ;
VAL_ 2566841178 SupportTSC1CtrlPurposeGroup4 1 "P25ReservedForAssignmentBySAE" ;
VAL_ 2566841178 SupportTSC1CtrlPurposeGroup3 1 "P17ReservedForAssignmentBySAE" ;
VAL_ 2566841178 SupportTSC1CtrlPurposeGroup2 1 "P9ReservedForAssignmentBySAE" ;
VAL_ 2566841178 SupportTSC1CtrlPurposeGroup1 1 "P1AccelPedal_OperatorSelection" ;
VAL_ 2566841178 SupportVariableRateTSC1Message 1 "MsTransRate" ;
VAL_ 2564882267 AuxiliaryHtrCoolantPumpRequest 0 "NOT_ACTIVE" 1 "ACTIVE" 3 "NOT_AVAILABLE" ;
VAL_ 2565865562 RetarderTorqueMode 15 "NOT_AVAILABLE" ;
VAL_ 2565865562 ActualRetarderPercentTorque 251 "PARAMETER_SPECIFIC" 254 "ERROR" 255 "NOT_AVAILABLE" ;
VAL_ 2565865562 IntendedRetarderPercentTorque 251 "PARAMETER_SPECIFIC" 254 "ERROR" 255 "NOT_AVAILABLE" ;
VAL_ 2565865562 ActMaxAvailRetarderPercentTorque 251 "PARAMETER_SPECIFIC" 254 "ERROR" 255 "NOT_AVAILABLE" ;
